VERSION "1.11.2"

NS_ :

BS_:

BU_: TCU BRK ESP MCU RDD GP TMS GW KPD1 RDE FNR ECU KPD2 ATSGO ACU IMU1 IMU2 IMU3 IMU4 IMU5 AGW PMI HDOQS EGOQS OBC EEC CBSW EJRH EJLH EPDLT EPDL2 EPDLR EPDLA TRBDZ ECU1 CLST LC510 EGDL JS SMB KPAC ACCU Audio TGU RDRR RDLH RDRH AVM CHMSL CTC SMK EVC MCU2 PHM MC3D AMBLMP RCTGU RDU PT3D XCU can1 can2

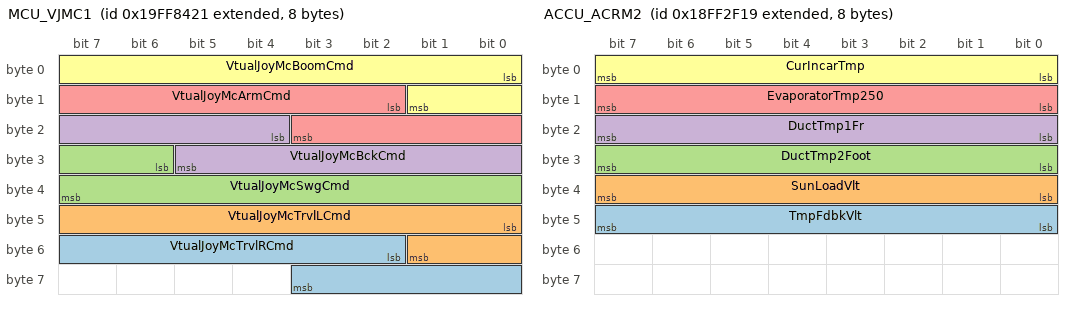
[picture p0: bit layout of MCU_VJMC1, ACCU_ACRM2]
BO_ 2583659553 MCU_VJMC1: 8 MCU
 SG_ VtualJoyMcTrvlRCmd : 50|10@1- (2,-1000) [-1000|3092] "" Vector__XXX
 SG_ VtualJoyMcTrvlLCmd : 40|10@1- (2,-1000) [-1000|3092] "" Vector__XXX
 SG_ VtualJoyMcSwgCmd : 30|10@1- (2,-1000) [-1000|3092] "" Vector__XXX
 SG_ VtualJoyMcBckCmd : 20|10@1- (2,-1000) [-1000|3092] "" Vector__XXX
 SG_ VtualJoyMcArmCmd : 10|10@1- (2,-1000) [-1000|3092] "" Vector__XXX
 SG_ VtualJoyMcBoomCmd : 0|10@1- (2,-1000) [-1000|3092] "" Vector__XXX

BO_ 2583660065 MCU_ESMMC: 250 MCU
 SG_ EstopTpr : 11|2@1+ (1,0) [0|3] "" Vector__XXX
 SG_ FuncFault : 8|3@1+ (1,0) [0|7] "" Vector__XXX
 SG_ GrdAstOptimizedCtrlMdSt : 6|2@1+ (1,0) [0|3] "" Vector__XXX
 SG_ InterlckSt : 3|3@1+ (1,0) [0|7] "" Vector__XXX
 SG_ AutoSt : 0|3@1+ (1,0) [0|7] "" Vector__XXX

BO_ 2583658336 MCU2_WCPD: 76 MCU2
 SG_ WghBckZeroWeight : 576|32@1+ (0.001,-1000000) [0|4294967295] "kg" Vector__XXX
 SG_ WghBckWeight : 544|32@1+ (0.001,-1000000) [0|4294967295] "kg" Vector__XXX
 SG_ WghFrLinkPrmt7 : 512|32@1+ (0.001,-1000000) [0|4294967295] "" Vector__XXX
 SG_ WghFrLinkPrmt6 : 480|32@1+ (0.001,-1000000) [0|4294967295] "" Vector__XXX
 SG_ WghFrLinkPrmt5 : 448|32@1+ (0.001,-1000000) [0|4294967295] "" Vector__XXX
 SG_ WghFrLinkPrmt4 : 416|32@1+ (0.001,-1000000) [0|4294967295] "" Vector__XXX
 SG_ WghFrLinkPrmt3 : 384|32@1+ (0.001,-1000000) [0|4294967295] "" Vector__XXX
 SG_ WghFrLinkPrmt2 : 352|32@1+ (0.001,-1000000) [0|4294967295] "" Vector__XXX
 SG_ WghFrLinkPrmt1 : 320|32@1+ (0.001,-1000000) [0|4294967295] "" Vector__XXX
 SG_ ArmCylStribeckFrcCoefc : 288|32@1+ (0.001,-1000000) [0|4294967295] "" Vector__XXX
 SG_ ArmCylViscousFrcCoefc : 256|32@1+ (0.001,-1000000) [0|4294967295] "" Vector__XXX
 SG_ ArmCylPrsClmbFrcCoefc : 224|32@1+ (0.001,-1000000) [0|4294967295] "" Vector__XXX
 SG_ ArmCylClmbFrcCoefc : 192|32@1+ (0.001,-1000000) [0|4294967295] "" Vector__XXX
 SG_ ArmCylPrsDrpFrcCoefc : 160|32@1+ (0.001,-1000000) [0|4294967295] "" Vector__XXX
 SG_ BoomCylStribeckFrcCoefc : 128|32@1+ (0.001,-1000000) [0|4294967295] "" Vector__XXX
 SG_ BoomCylViscousFrcCoefc : 96|32@1+ (0.001,-1000000) [0|4294967295] "" Vector__XXX
 SG_ BoomCylPrsClmbFrcCoefc : 64|32@1+ (0.001,-1000000) [0|4294967295] "" Vector__XXX
 SG_ BoomCylClmbFrcCoefc : 32|32@1+ (0.001,-1000000) [0|4294967295] "" Vector__XXX
 SG_ BoomCylPrsDrpFrcCoefc : 0|32@1+ (0.001,-1000000) [0|4294967295] "" Vector__XXX

BO_ 2583658160 MC3D_WCCV2: 250 MC3D
 SG_ TgBckCylVelocityUpLm : 16|8@1+ (0.1,0) [0|20] "mmps" Vector__XXX
 SG_ TgBckCylVelocityLwLm : 8|8@1+ (0.1,0) [0|20] "mmps" Vector__XXX
 SG_ CurBckCylVelocity : 0|8@1+ (0.1,0) [0|20] "mmps" Vector__XXX

BO_ 2566908592 MC3D_MWIG: 250 MC3D
 SG_ TiltRttArg : 62|2@1+ (1,0) [0|3] "" Vector__XXX
 SG_ GnssSt : 58|4@1+ (1,0) [0|15] "" Vector__XXX
 SG_ VhcStFineSwgTprDsb : 56|2@1+ (1,0) [0|3] "" Vector__XXX
 SG_ IndSymbolMcTprRlsSt : 54|2@1+ (1,0) [0|3] "" Vector__XXX
 SG_ EfenceTgSetSideWallR : 52|2@1- (1,-32000) [-32000|32255] "mm" Vector__XXX
 SG_ EfenceWarnSideWallR : 50|2@1- (1,-32000) [-32000|32255] "mm" Vector__XXX
 SG_ EfenceWarnSideWallL : 48|2@1+ (1,0) [0|3] "" Vector__XXX
 SG_ AssitSwgRh : 46|2@1+ (1,0) [0|3] "" Vector__XXX
 SG_ AssitSwgLh : 44|2@1+ (1,0) [0|3] "" Vector__XXX
 SG_ AssitBck : 42|2@1+ (1,0) [0|3] "" Vector__XXX
 SG_ AssitGrd : 40|2@1+ (1,0) [0|3] "" Vector__XXX
 SG_ SafeWrkSideFar : 36|2@1+ (1,0) [0|3] "" Vector__XXX
 SG_ SafeWrkSideMid : 34|2@1+ (1,0) [0|3] "" Vector__XXX
 SG_ SafeWrkSideNear : 32|2@1+ (1,0) [0|3] "" Vector__XXX
 SG_ SafeWrkFrFar : 28|2@1+ (1,0) [0|3] "" Vector__XXX
 SG_ SafeWrkFrMid : 26|2@1+ (1,0) [0|3] "" Vector__XXX
 SG_ SafeWrkFrNear : 24|2@1+ (1,0) [0|3] "" Vector__XXX
 SG_ FrMvGuidArmOut : 22|2@1+ (1,0) [0|3] "" Vector__XXX
 SG_ FrMvGuidArmIn : 20|2@1+ (1,0) [0|3] "" Vector__XXX
 SG_ FrMvGuidBoomDn : 18|2@1+ (1,0) [0|3] "" Vector__XXX
 SG_ FrMvGuidBoomUp : 16|2@1+ (1,0) [0|3] "" Vector__XXX
 SG_ EfenceTrkWrn : 14|2@1+ (1,0) [0|3] "" Vector__XXX
 SG_ EfenceDzWrn : 12|2@1+ (1,0) [0|3] "" Vector__XXX
 SG_ EfenceCabWrn : 10|2@1+ (1,0) [0|3] "" Vector__XXX
 SG_ EfenceFSwgRhWrn : 8|2@1+ (1,0) [0|3] "" Vector__XXX
 SG_ EfenceFSwgLhWrn : 6|2@1+ (1,0) [0|3] "" Vector__XXX
 SG_ EfenceCeilWrn : 4|2@1+ (1,0) [0|3] "" Vector__XXX
 SG_ EfenceFloorWrn : 2|2@1+ (1,0) [0|3] "" Vector__XXX
 SG_ EfenceWallWrn : 0|2@1+ (1,0) [0|3] "" Vector__XXX

BO_ 2566909872 MC3D_LADG: 250 MC3D
 SG_ Reach : 48|16@1- (1,-32000) [-32000|32255] "mm" Vector__XXX
 SG_ Hight : 32|16@1- (1,-32000) [-32000|32255] "mm" Vector__XXX
 SG_ RatedLoad : 16|16@1+ (2,0) [0|128510] "kg" Vector__XXX
 SG_ ActLoad : 0|16@1+ (2,0) [0|128510] "kg" Vector__XXX

BO_ 2566913200 MC3D_MCWHG3: 250 MC3D

BO_ 2566913456 MC3D_HSDI: 250 MC3D
 SG_ RandomVal : 0|16@1+ (1,0) [0|65535] "" Vector__XXX

BO_ 2583659184 MC3D_WCJA2: 250 MC3D
 SG_ TgBckJointAngEndPos : 16|8@1+ (1,-125) [-125|125] "deg" Vector__XXX
 SG_ TgBckJointAngStartPos : 8|8@1+ (1,-125) [-125|125] "deg" Vector__XXX
 SG_ CurBckJointAng : 0|8@1+ (1,-125) [-125|125] "deg" Vector__XXX

BO_ 2583659440 MC3D_ALAIG: 250 MC3D
 SG_ SafeWrkIndSwgR : 58|2@1+ (1,0) [0|3] "" Vector__XXX
 SG_ SafeWrkIndSwgL : 56|2@1+ (1,0) [0|3] "" Vector__XXX
 SG_ SafeWrkInd8Far : 54|2@1+ (1,0) [0|3] "" Vector__XXX
 SG_ SafeWrkInd8Mid : 52|2@1+ (1,0) [0|3] "" Vector__XXX
 SG_ SafeWrkInd8Near : 50|2@1+ (1,0) [0|3] "" Vector__XXX
 SG_ SafeWrkInd7Far : 48|2@1+ (1,0) [0|3] "" Vector__XXX
 SG_ SafeWrkInd7Mid : 46|2@1+ (1,0) [0|3] "" Vector__XXX
 SG_ SafeWrkInd7Near : 44|2@1+ (1,0) [0|3] "" Vector__XXX
 SG_ SafeWrkInd6Far : 42|2@1+ (1,0) [0|3] "" Vector__XXX
 SG_ SafeWrkInd6Mid : 40|2@1+ (1,0) [0|3] "" Vector__XXX
 SG_ SafeWrkInd6Near : 38|2@1+ (1,0) [0|3] "" Vector__XXX
 SG_ SafeWrkInd5Far : 36|2@1+ (1,0) [0|3] "" Vector__XXX
 SG_ SafeWrkInd5Mid : 34|2@1+ (1,0) [0|3] "" Vector__XXX
 SG_ SafeWrkInd5Near : 32|2@1+ (1,0) [0|3] "" Vector__XXX
 SG_ SafeWrkInd4Far : 30|2@1+ (1,0) [0|3] "" Vector__XXX
 SG_ SafeWrkInd4Mid : 28|2@1+ (1,0) [0|3] "" Vector__XXX
 SG_ SafeWrkInd4Near : 26|2@1+ (1,0) [0|3] "" Vector__XXX
 SG_ SafeWrkInd3Far : 24|2@1+ (1,0) [0|3] "" Vector__XXX
 SG_ SafeWrkInd3Mid : 22|2@1+ (1,0) [0|3] "" Vector__XXX
 SG_ SafeWrkInd3Near : 20|2@1+ (1,0) [0|3] "" Vector__XXX
 SG_ SafeWrkInd2Far : 18|2@1+ (1,0) [0|3] "" Vector__XXX
 SG_ SafeWrkInd2Mid : 16|2@1+ (1,0) [0|3] "" Vector__XXX
 SG_ SafeWrkInd2Near : 14|2@1+ (1,0) [0|3] "" Vector__XXX
 SG_ SafeWrkInd1Far : 12|2@1+ (1,0) [0|3] "" Vector__XXX
 SG_ SafeWrkInd1Mid : 10|2@1+ (1,0) [0|3] "" Vector__XXX
 SG_ SafeWrkInd1Near : 8|2@1+ (1,0) [0|3] "" Vector__XXX
 SG_ ReliefPressureLm : 3|2@1+ (1,0) [0|3] "" Vector__XXX
 SG_ ArmReachInd : 1|2@1+ (1,0) [0|3] "" Vector__XXX
 SG_ AdvLiftAssReady : 0|1@1+ (1,0) [0|1] "" Vector__XXX

BO_ 2583659696 MC3D_VJMC1: 10 MC3D
 SG_ VtualJoyMcTrvlRCmd : 50|10@1- (2,-1000) [-1000|3092] "" Vector__XXX
 SG_ VtualJoyMcTrvlLCmd : 40|10@1- (2,-1000) [-1000|3092] "" Vector__XXX
 SG_ VtualJoyMcSwgCmd : 30|10@1- (2,-1000) [-1000|3092] "" Vector__XXX
 SG_ VtualJoyMcBckCmd : 20|10@1- (2,-1000) [-1000|3092] "" Vector__XXX
 SG_ VtualJoyMcArmCmd : 10|10@1- (2,-1000) [-1000|3092] "" Vector__XXX
 SG_ VtualJoyMcBoomCmd : 0|10@1- (2,-1000) [-1000|3092] "" Vector__XXX

BO_ 2583659952 MC3D_VJMC2: 250 MC3D
 SG_ VtualJoyMcTrAux2Cmd : 50|10@1- (2,-1000) [-1000|3092] "" Vector__XXX
 SG_ VtualJoyMcTrAux1Cmd : 40|10@1- (2,-1000) [-1000|3092] "" Vector__XXX
 SG_ VtualJoyMcTrRttCmd : 30|10@1- (2,-1000) [-1000|3092] "" Vector__XXX
 SG_ VtualJoyMcTrTiltCmd : 20|10@1- (2,-1000) [-1000|3092] "" Vector__XXX
 SG_ VtualJoyMcOptCmd : 10|10@1- (2,-1000) [-1000|3092] "" Vector__XXX
 SG_ VtualJoyMcArtiCmd : 0|10@1- (2,-1000) [-1000|3092] "" Vector__XXX

BO_ 2583660464 MC3D_MCRES: 250 MC3D
 SG_ SelBckNo : 16|8@1+ (1,0) [0|255] "" Vector__XXX
 SG_ SelMdHeartbeat : 12|3@1+ (1,0) [0|7] "" Vector__XXX
 SG_ ArmingAcptReq : 10|2@1+ (1,0) [0|3] "" Vector__XXX
 SG_ McActCmd : 8|2@1+ (1,0) [0|3] "" Vector__XXX
 SG_ GrdAstOptmCtrlMdSt : 6|2@1+ (1,0) [0|3] "" Vector__XXX
 SG_ McItlReq : 3|3@1+ (1,0) [0|7] "" Vector__XXX
 SG_ McReqMd : 0|3@1+ (1,0) [0|7] "" Vector__XXX

BO_ 2566911153 AMBLMP_ALSD: 250 AMBLMP
 SG_ AmbLmpColorMd : 33|1@1+ (1,0) [0|1] "" Vector__XXX
 SG_ AmbLmpSt : 32|1@1+ (1,0) [0|1] "" Vector__XXX
 SG_ AmbLmpBrightness : 24|8@1+ (1,0) [0|250] "percent" Vector__XXX
 SG_ AmbLmpColor : 0|24@1+ (1,0) [0|16777215] "count" Vector__XXX

BO_ 2566911308 RCTGU_TGUVCC: 8 RCTGU
 SG_ SelMdHeartbeat : 48|3@1+ (1,0) [0|7] "" Vector__XXX
 SG_ ArmingAcptReq : 45|2@1+ (1,0) [0|3] "" Vector__XXX
 SG_ RmWrkMdSelSig : 40|3@1+ (1,0) [0|7] "" Vector__XXX
 SG_ RmTrvlSpdSelSig : 38|2@1+ (1,0) [0|3] "" Vector__XXX
 SG_ RmPwrMdSelSig2 : 36|2@1+ (1,0) [0|3] "" Vector__XXX
 SG_ RmCtrlActSig : 34|2@1+ (1,0) [0|3] "" Vector__XXX
 SG_ RmItlReq : 32|2@1+ (1,0) [0|3] "" Vector__XXX
 SG_ RmRpmSig : 24|8@1+ (0.004,0) [0|100] "percent" Vector__XXX
 SG_ RmCtrlReq : 22|2@1+ (1,0) [0|3] "" Vector__XXX
 SG_ RmEgStopSt : 20|2@1+ (1,0) [0|3] "" Vector__XXX
 SG_ RmPwrMdSelSig1 : 18|2@1+ (1,0) [0|3] "" Vector__XXX
 SG_ RmEmgStopOprSig : 16|2@1+ (1,0) [0|3] "" Vector__XXX
 SG_ RmFrcRgnOprSig : 14|2@1+ (1,0) [0|3] "" Vector__XXX
 SG_ RmHornOprSig : 12|2@1+ (1,0) [0|3] "" Vector__XXX
 SG_ RmPltCutoffRlsSvOprSig : 10|2@1+ (1,0) [0|3] "" Vector__XXX
 SG_ RmFineSwgSvOprSig : 8|2@1+ (1,0) [0|3] "" Vector__XXX
 SG_ RmCbLmpRly2OprSig : 6|2@1+ (1,0) [0|3] "" Vector__XXX
 SG_ RmCbLmpRly1OprSig : 4|2@1+ (1,0) [0|3] "" Vector__XXX
 SG_ RmBodyLmpRlyOprSig : 2|2@1+ (1,0) [0|3] "" Vector__XXX
 SG_ RmWrkLmpRlyOprSig : 0|2@1+ (1,0) [0|3] "" Vector__XXX

BO_ 2566860569 ACCU_ACRM2: 8 ACCU
 SG_ TmpFdbkVlt : 40|8@1+ (0.02044,0) [0|5.11] "" Vector__XXX
 SG_ SunLoadVlt : 32|8@1+ (0.02044,0) [0|5.11] "" Vector__XXX
 SG_ DuctTmp2Foot : 24|8@1+ (1,-40) [-40|210] "" Vector__XXX
 SG_ DuctTmp1Fr : 16|8@1+ (1,-40) [-40|210] "" Vector__XXX
 SG_ EvaporatorTmp250 : 8|8@1+ (1,-40) [-40|210] "" Vector__XXX
 SG_ CurIncarTmp : 0|8@1+ (1,-40) [-40|210] "" Vector__XXX

BO_ 2565844776 GP_GPSMPHM: 1785 GP

BO_ 2566867632 MC3D_SIG4: 8 MC3D
 SG_ WarnPopLimitangexcess : 62|2@1+ (1,0) [0|3] "" Vector__XXX
 SG_ WarnPopMgMcSsErr : 58|4@1+ (1,0) [0|15] "" Vector__XXX
 SG_ McTemporaryRlsPop : 56|2@1+ (1,0) [0|3] "" Vector__XXX
 SG_ VhcStStickStr : 54|2@1+ (1,0) [0|3] "" Vector__XXX
 SG_ VhcStFineSwg : 52|2@1+ (1,0) [0|3] "" Vector__XXX
 SG_ ActTrvlSpdforCrwl : 50|2@1+ (1,0) [0|3] "" Vector__XXX
 SG_ ActTrvlStforCrwl : 48|2@1+ (1,0) [0|3] "" Vector__XXX
 SG_ VhcStParallelLift : 46|2@1+ (1,0) [0|3] "" Vector__XXX
 SG_ VhcStFrSspnAuto : 44|2@1+ (1,0) [0|3] "" Vector__XXX
 SG_ RmCrakingSt : 40|4@1+ (1,0) [0|15] "" Vector__XXX
 SG_ IndTrmsColdStart : 39|1@1+ (1,0) [0|1] "" Vector__XXX
 SG_ VhcStElevatingCabin : 37|2@1+ (1,0) [0|3] "" Vector__XXX
 SG_ WarnPopStickStr : 36|1@1+ (1,0) [0|1] "" Vector__XXX
 SG_ PopCmdThwLvrErr : 35|1@1+ (1,0) [0|1] "" Vector__XXX
 SG_ HpApMd : 33|2@1+ (1,0) [0|3] "" Vector__XXX
 SG_ GrLmt : 32|1@1+ (1,0) [0|1] "" Vector__XXX
 SG_ BodyAng : 24|8@1+ (1,-125) [-125|125] "deg" Vector__XXX
 SG_ WghIndSt : 22|2@1+ (1,0) [0|3] "" Vector__XXX
 SG_ BrkHold : 21|1@1+ (1,0) [0|1] "" Vector__XXX
 SG_ RtrdSt : 18|3@1+ (1,0) [0|7] "" Vector__XXX
 SG_ PilotCutOffSt : 16|2@1+ (1,0) [0|3] "" Vector__XXX
 SG_ BodySt : 14|2@1+ (1,0) [0|3] "" Vector__XXX
 SG_ VhcStGndSaw : 13|1@1+ (1,0) [0|1] "" Vector__XXX
 SG_ PopCmdJoyLvrNtrlErr : 12|1@1+ (1,0) [0|1] "" Vector__XXX
 SG_ VhcStIntAxleLck : 11|1@1+ (1,0) [0|1] "" Vector__XXX
 SG_ TrlHhFlowMd : 8|3@1+ (1,0) [0|7] "" Vector__XXX
 SG_ ExcAutoBrkAntiFire : 6|2@1+ (1,0) [0|3] "" Vector__XXX
 SG_ TrlIntLckOvrd : 5|1@1+ (1,0) [0|1] "" Vector__XXX
 SG_ TrlCtrlFlow : 3|2@1+ (1,0) [0|3] "" Vector__XXX
 SG_ TrlSelfLv : 1|2@1+ (1,0) [0|3] "" Vector__XXX
 SG_ TrlHhFlow : 0|1@1+ (1,0) [0|1] "" Vector__XXX

BO_ 2583660720 MC3D_XCUTE: 250 MC3D
 SG_ Mc3DGrdTgErrorR : 32|16@1- (1,-32000) [-32000|32255] "" Vector__XXX
 SG_ Mc3DGrdTgErrorCnt : 16|16@1- (1,-32000) [-32000|32255] "" Vector__XXX
 SG_ Mc3DGrdTgErrorL : 0|16@1- (1,-32000) [-32000|32255] "" Vector__XXX

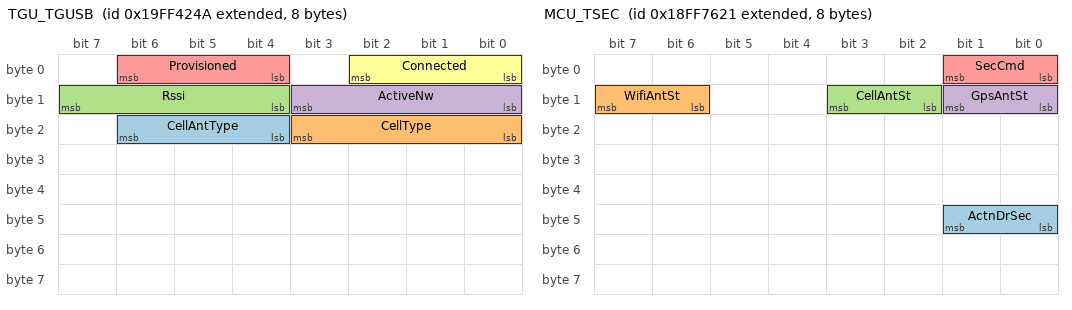
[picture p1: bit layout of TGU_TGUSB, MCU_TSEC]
BO_ 2583642698 TGU_TGUSB: 8 TGU
 SG_ CellAntType : 20|3@1+ (1,0) [0|3] "" Vector__XXX
 SG_ CellType : 16|4@1+ (1,0) [0|15] "" Vector__XXX
 SG_ Rssi : 12|4@1+ (1,0) [0|15] "" Vector__XXX
 SG_ ActiveNw : 8|4@1+ (1,0) [0|15] "" Vector__XXX
 SG_ Provisioned : 4|3@1+ (1,0) [0|7] "" Vector__XXX
 SG_ Connected : 0|3@1+ (1,0) [0|7] "" Vector__XXX

BO_ 2565406538 TGU_TUACK: 8 TGU
 SG_ Ack : 0|2@1+ (1,0) [0|3] "" Vector__XXX

BO_ 2566878753 MCU_TSEC: 8 MCU
 SG_ ActnDrSec : 40|2@1+ (1,0) [0|3] "" Vector__XXX
 SG_ WifiAntSt : 14|2@1+ (1,0) [0|3] "" Vector__XXX
 SG_ CellAntSt : 10|2@1+ (1,0) [0|3] "" Vector__XXX
 SG_ GpsAntSt : 8|2@1+ (1,0) [0|3] "" Vector__XXX
 SG_ SecCmd : 0|2@1+ (1,0) [0|3] "" Vector__XXX

BO_ 2583643176 GP_KLLI: 13 GP
 SG_ PinCd : 48|56@1+ (1,0) [0|7.20575940379279E+16] "ASCII" Vector__XXX
 SG_ DigitalKey : 0|48@1+ (1,0) [0|281474976710655] "binary" Vector__XXX

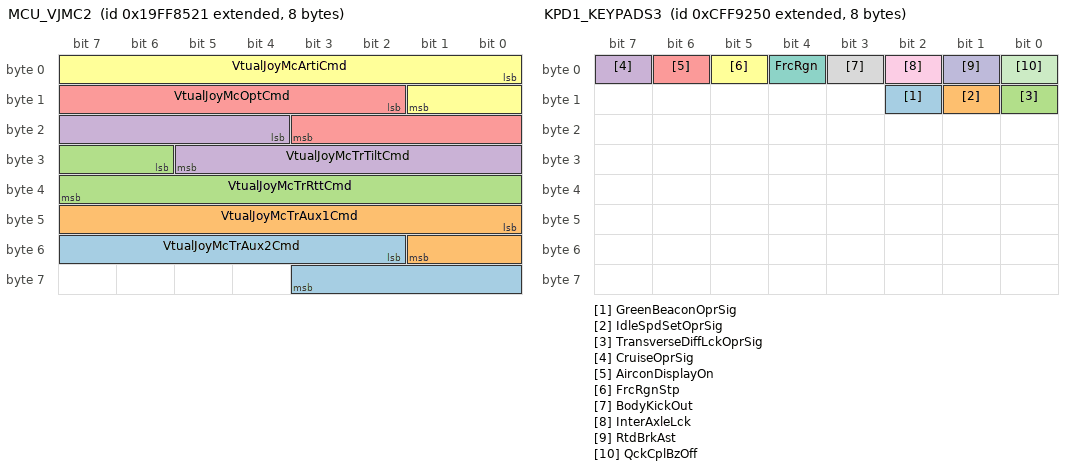
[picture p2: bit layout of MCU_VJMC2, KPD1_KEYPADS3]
BO_ 2583659809 MCU_VJMC2: 8 MCU
 SG_ VtualJoyMcTrAux2Cmd : 50|10@1- (2,-1000) [-1000|3092] "" Vector__XXX
 SG_ VtualJoyMcTrAux1Cmd : 40|10@1- (2,-1000) [-1000|3092] "" Vector__XXX
 SG_ VtualJoyMcTrRttCmd : 30|10@1- (2,-1000) [-1000|3092] "" Vector__XXX
 SG_ VtualJoyMcTrTiltCmd : 20|10@1- (2,-1000) [-1000|3092] "" Vector__XXX
 SG_ VtualJoyMcOptCmd : 10|10@1- (2,-1000) [-1000|3092] "" Vector__XXX
 SG_ VtualJoyMcArtiCmd : 0|10@1- (2,-1000) [-1000|3092] "" Vector__XXX

BO_ 2583643432 GP_DKTL: 1785 GP
 SG_ DkeyListInfo : 0|14280@1+ (1,0) [0|0] "ASCII-VN" Vector__XXX

BO_ 2566868513 MCU_SIG5: 8 MCU
 SG_ VhcStSybEmgStrCheck : 62|2@1+ (1,0) [0|3] "" Vector__XXX
 SG_ CmdBodyLiftLmt : 60|2@1+ (1,0) [0|3] "" Vector__XXX
 SG_ VhcStSybAutoHold : 56|4@1+ (1,0) [0|15] "" Vector__XXX
 SG_ VhcStSybAutoDig : 52|3@1+ (1,0) [0|7] "" Vector__XXX
 SG_ RearRTirePrsLow : 50|2@1+ (1,0) [0|3] "" Vector__XXX
 SG_ RearLTirePrsLow : 48|2@1+ (1,0) [0|3] "" Vector__XXX
 SG_ FrRTirePrsLow : 46|2@1+ (1,0) [0|3] "" Vector__XXX
 SG_ FrLTirePrsLow : 44|2@1+ (1,0) [0|3] "" Vector__XXX
 SG_ HhFlowAuxSt : 40|3@1+ (1,0) [0|7] "" Vector__XXX
 SG_ IndSybWirelessChgSt : 38|2@1+ (1,0) [0|3] "" Vector__XXX
 SG_ VhcStSybIdleSpdSet : 36|2@1+ (1,0) [0|3] "" Vector__XXX
 SG_ GrStMismatchSig : 34|2@1+ (1,0) [0|3] "" Vector__XXX
 SG_ VhcStSybBrkChg : 32|2@1+ (1,0) [0|3] "" Vector__XXX
 SG_ CmdFineSwg : 30|2@1+ (1,0) [0|3] "" Vector__XXX
 SG_ CmdOptLinePrsRf : 28|2@1+ (1,0) [0|3] "" Vector__XXX
 SG_ AdtUserWghCalSt : 26|2@1+ (1,0) [0|3] "" Vector__XXX
 SG_ VhcStateSybSpdLimitCtrl : 24|2@1+ (1,0) [0|3] "" Vector__XXX
 SG_ TmShftMdSybforLd : 21|3@1+ (1,0) [0|7] "" Vector__XXX
 SG_ BckShakeStSig : 18|3@1+ (1,0) [0|7] "" Vector__XXX
 SG_ CmdForceRegenFail : 16|2@1+ (1,0) [0|3] "" Vector__XXX
 SG_ DumpBodyOprSig : 12|2@1+ (1,0) [0|3] "" Vector__XXX
 SG_ WghStRefreshSig : 10|2@1+ (1,0) [0|3] "" Vector__XXX
 SG_ CmdStarterFail : 8|2@1+ (1,0) [0|3] "" Vector__XXX
 SG_ IdleSpdSetCond : 6|2@1+ (1,0) [0|3] "" Vector__XXX
 SG_ CmdRrSspn_SelfLv : 4|2@1+ (1,0) [0|3] "" Vector__XXX
 SG_ VhcStSybRrSspnAuto : 2|2@1+ (1,0) [0|3] "" Vector__XXX
 SG_ CmdFrSspn : 0|2@1+ (1,0) [0|3] "" Vector__XXX

BO_ 2365559376 KPD1_KEYPADS3: 8 KPD1
 SG_ GreenBeaconOprSig : 10|1@1+ (1,0) [0|1] "" Vector__XXX
 SG_ IdleSpdSetOprSig : 9|1@1+ (1,0) [0|1] "" Vector__XXX
 SG_ TransverseDiffLckOprSig : 8|1@1+ (1,0) [0|1] "" Vector__XXX
 SG_ CruiseOprSig : 7|1@1+ (1,0) [0|1] "" Vector__XXX
 SG_ AirconDisplayOn : 6|1@1+ (1,0) [0|3] "" Vector__XXX
 SG_ FrcRgnStp : 5|1@1+ (1,0) [0|3] "" Vector__XXX
 SG_ FrcRgn : 4|1@1+ (1,0) [0|3] "" Vector__XXX
 SG_ BodyKickOut : 3|1@1+ (1,0) [0|1] "" Vector__XXX
 SG_ InterAxleLck : 2|1@1+ (1,0) [0|1] "" Vector__XXX
 SG_ RtdBrkAst : 1|1@1+ (1,0) [0|1] "" Vector__XXX
 SG_ QckCplBzOff : 0|1@1+ (1,0) [0|1] "" Vector__XXX

BO_ 2365559585 MCU_KEYPADI5: 8 MCU
 SG_ GreenBeaconLInd : 58|2@1+ (1,0) [0|3] "" Vector__XXX
 SG_ GreenBeaconCtrInd : 56|2@1+ (1,0) [0|3] "" Vector__XXX
 SG_ GreenBeaconRInd : 54|2@1+ (1,0) [0|3] "" Vector__XXX
 SG_ IdleSpdSetLInd : 52|2@1+ (1,0) [0|3] "" Vector__XXX
 SG_ IdleSpdSetCtrInd : 50|2@1+ (1,0) [0|3] "" Vector__XXX
 SG_ IdleSpdSetRInd : 48|2@1+ (1,0) [0|3] "" Vector__XXX
 SG_ TransverseDiffLckLOprSig : 46|2@1+ (1,0) [0|3] "" Vector__XXX
 SG_ TransverseDiffLckCtrOprSig : 44|2@1+ (1,0) [0|3] "" Vector__XXX
 SG_ TransverseDiffLckROprSig : 42|2@1+ (1,0) [0|3] "" Vector__XXX
 SG_ CruiseLInd : 40|2@1+ (1,0) [0|3] "" Vector__XXX
 SG_ CruiseCtrInd : 38|2@1+ (1,0) [0|3] "" Vector__XXX
 SG_ CruiseRInd : 36|2@1+ (1,0) [0|3] "" Vector__XXX
 SG_ RtdBrkAstLInd : 34|2@1+ (1,0) [0|3] "" Vector__XXX
 SG_ RtdBrkAstCtrInd : 32|2@1+ (1,0) [0|3] "" Vector__XXX
 SG_ RtdBrkAstRInd : 30|2@1+ (1,0) [0|3] "" Vector__XXX
 SG_ QckCplBzOffLInd : 28|2@1+ (1,0) [0|3] "" Vector__XXX
 SG_ QckCplBzOffCtrInd : 26|2@1+ (1,0) [0|3] "" Vector__XXX
 SG_ QckCplBzOffRInd : 24|2@1+ (1,0) [0|3] "" Vector__XXX
 SG_ FrcRgnStpLInd : 22|2@1+ (1,0) [0|3] "" Vector__XXX
 SG_ FrcRgnStpCtrInd : 20|2@1+ (1,0) [0|3] "" Vector__XXX
 SG_ FrcRgnStpRInd : 18|2@1+ (1,0) [0|3] "" Vector__XXX
 SG_ FrcRgnLInd : 16|2@1+ (1,0) [0|3] "" Vector__XXX
 SG_ FrcRgnCtrInd : 14|2@1+ (1,0) [0|3] "" Vector__XXX
 SG_ FrcRgnRInd : 12|2@1+ (1,0) [0|3] "" Vector__XXX
 SG_ BodyKickOutLInd : 10|2@1+ (1,0) [0|3] "" Vector__XXX
 SG_ BodyKickOutCtrInd : 8|2@1+ (1,0) [0|3] "" Vector__XXX
 SG_ BodyKickOutRInd : 6|2@1+ (1,0) [0|3] "" Vector__XXX
 SG_ InterAxleLckLInd : 4|2@1+ (1,0) [0|3] "" Vector__XXX
 SG_ InterAxleLckCtrInd : 2|2@1+ (1,0) [0|3] "" Vector__XXX
 SG_ InterAxleLckRInd : 0|2@1+ (1,0) [0|3] "" Vector__XXX

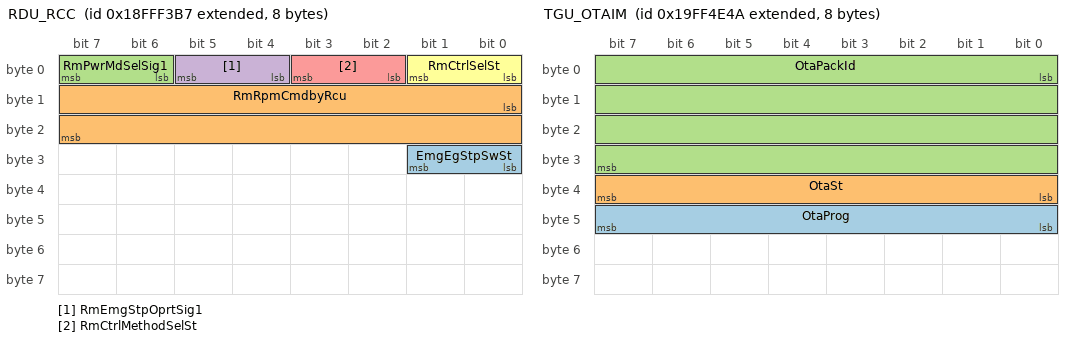
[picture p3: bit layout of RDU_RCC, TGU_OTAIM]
BO_ 2566910903 RDU_RCC: 8 RDU
 SG_ EmgEgStpSwSt : 24|2@1+ (1,0) [0|3] "" Vector__XXX
 SG_ RmRpmCmdbyRcu : 8|16@1+ (0.001,0) [0|64.255] "V" Vector__XXX
 SG_ RmPwrMdSelSig1 : 6|2@1+ (1,0) [0|3] "" Vector__XXX
 SG_ RmEmgStpOprtSig1 : 4|2@1+ (1,0) [0|3] "" Vector__XXX
 SG_ RmCtrlMethodSelSt : 2|2@1+ (1,0) [0|3] "" Vector__XXX
 SG_ RmCtrlSelSt : 0|2@1+ (1,0) [0|3] "" Vector__XXX

BO_ 2566891510 PT3D_TCSMVCU: 8 PT3D
 SG_ Mc3DOprtSt : 24|8@1+ (1,0) [0|255] "" Vector__XXX
 SG_ Mc3DSysReadySt : 16|8@1+ (1,0) [0|255] "" Vector__XXX

BO_ 2583645770 TGU_OTAIM: 8 TGU
 SG_ OtaProg : 40|8@1+ (1,0) [0|100] "percent" Vector__XXX
 SG_ OtaSt : 32|8@1+ (1,0) [0|15] "" Vector__XXX
 SG_ OtaPackId : 0|32@1+ (1,0) [0|4294967295] "" Vector__XXX

BO_ 2566859041 MCU_CTM: 8 MCU
 SG_ FnrDirForLv1RrMon : 0|2@1+ (1,0) [0|3] "" Vector__XXX

BO_ 2566858273 MCU_AFCL: 1785 MCU
 SG_ Afc : 0|1@1+ (1,0) [0|1] "ignore" Vector__XXX

BO_ 2566858529 MCU_HFCL: 1785 MCU
 SG_ Hfc : 0|1@1+ (1,0) [0|1] "ignore" Vector__XXX

BO_ 2583646026 TGU_API: 1783 TGU
 SG_ EndPoint : 1200|13064@1+ (1,0) [0|0] "ASCII-VN" Vector__XXX
 SG_ Key : 0|1200@1+ (1,0) [0|0] "ASCII-FN" Vector__XXX

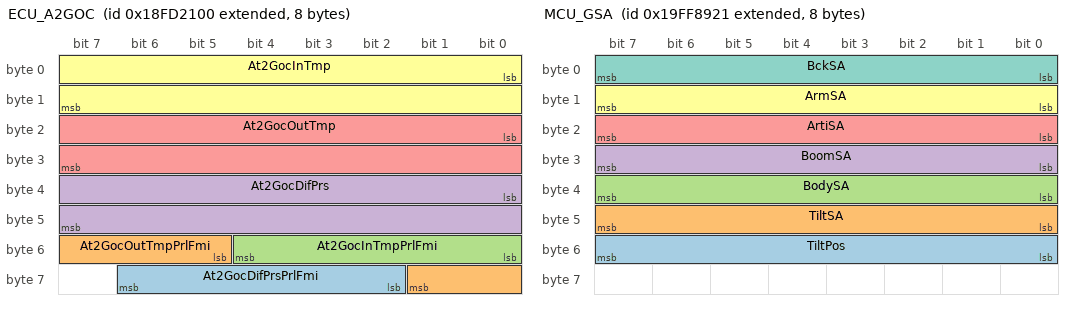
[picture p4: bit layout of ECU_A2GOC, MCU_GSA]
BO_ 2566725888 ECU_A2GOC: 8 ECU
 SG_ At2GocDifPrsPrlFmi : 58|5@1+ (1,0) [0|31] "" Vector__XXX
 SG_ At2GocOutTmpPrlFmi : 53|5@1+ (1,0) [0|31] "" Vector__XXX
 SG_ At2GocInTmpPrlFmi : 48|5@1+ (1,0) [0|31] "" Vector__XXX
 SG_ At2GocDifPrs : 32|16@1+ (0.1,0) [0|6425.5] "kPa" Vector__XXX
 SG_ At2GocOutTmp : 16|16@1+ (0.03125,-273) [-273|1734.96875] "celsius" Vector__XXX
 SG_ At2GocInTmp : 0|16@1+ (0.03125,-273) [-273|1734.96875] "celsius" Vector__XXX

BO_ 2566879050 TGU_TMSGPSI2: 8 TGU
 SG_ Z : 48|16@1+ (1,0) [0|65535] "m" Vector__XXX

BO_ 2566913576 GP_MTSI: 88 GP
 SG_ CompanyName : 504|200@1+ (1,0) [0|1.60693804425899E+60] "ASCII" Vector__XXX
 SG_ TgWghofCurTrk : 488|16@1+ (2,0) [0|128510] "kg" Vector__XXX
 SG_ TrkCntFinalTm : 456|32@1+ (1,0) [0|4211081215] "s" Vector__XXX
 SG_ MaterialLoadSt : 448|1@1+ (1,0) [0|1] "" Vector__XXX
 SG_ TotWghCurTrk : 432|16@1+ (2,0) [0|128510] "kg" Vector__XXX
 SG_ BckCntCurTrk : 416|16@1+ (1,0) [0|65535] "count" Vector__XXX
 SG_ MtrDensity : 400|16@1+ (1,0) [0|64255] "kgpm3" Vector__XXX
 SG_ MtrName : 200|200@1+ (1,0) [0|255] "ASCII" Vector__XXX
 SG_ TrkName : 0|200@1+ (1,0) [0|1.60693804425899E+60] "ASCII" Vector__XXX

BO_ 2566838880 MCU2_SOFT: 1785 MCU2
 SG_ PckVer : 8|14272@1+ (1,0) [0|0] "ASCII" Vector__XXX
 SG_ DtLgh : 0|8@1+ (1,0) [0|255] "" Vector__XXX

BO_ 2633947703 AVM_SOFT: 1785 AVM
 SG_ PckVer : 8|14272@1+ (1,0) [0|0] "ASCII" Vector__XXX
 SG_ DtLgh : 0|8@1+ (1,0) [0|255] "" Vector__XXX

BO_ 2566838959 PHM_SOFT: 1785 PHM
 SG_ PckVer : 8|14272@1+ (1,0) [0|0] "ASCII" Vector__XXX
 SG_ DtLgh : 0|8@1+ (1,0) [0|255] "" Vector__XXX

BO_ 2566838960 MC3D_SOFT: 1785 MC3D
 SG_ PckVer : 8|14272@1+ (1,0) [0|0] "ASCII" Vector__XXX
 SG_ DtLgh : 0|8@1+ (1,0) [0|255] "" Vector__XXX

BO_ 2583660833 MCU_GSA: 8 MCU
 SG_ TiltPos : 48|8@1+ (1,0) [0|255] "" Vector__XXX
 SG_ TiltSA : 40|8@1+ (1,0) [0|255] "" Vector__XXX
 SG_ BodySA : 32|8@1+ (1,0) [0|255] "" Vector__XXX
 SG_ BoomSA : 24|8@1+ (1,0) [0|255] "" Vector__XXX
 SG_ ArtiSA : 16|8@1+ (1,0) [0|255] "" Vector__XXX
 SG_ ArmSA : 8|8@1+ (1,0) [0|255] "" Vector__XXX
 SG_ BckSA : 0|8@1+ (1,0) [0|255] "" Vector__XXX

BO_ 2566885450 TGU_QRCI: 55 TGU
 SG_ PartNo : 312|128@1+ (1,0) [0|3.40282366920938E+38] "ASCII-FN" Vector__XXX
 SG_ SerialNo : 184|128@1+ (1,0) [0|3.40282366920938E+38] "ASCII-FN" Vector__XXX
 SG_ MnftCode : 120|64@1+ (1,0) [0|1.84467440737096E+19] "ASCII-FN" Vector__XXX
 SG_ ComCode : 56|64@1+ (1,0) [0|1.84467440737096E+19] "ASCII-FN" Vector__XXX
 SG_ Year : 48|8@1+ (1,1985) [1985|2235] "year" Vector__XXX
 SG_ Day : 40|8@1+ (0.25,0) [0|62.5] "days" Vector__XXX
 SG_ Month : 32|8@1+ (1,0) [0|250] "month" Vector__XXX
 SG_ SwVer : 0|32@1+ (1,0) [0|4294967295] "ASCII" Vector__XXX

BO_ 2583645258 TGU_RDI: 1785 TGU
 SG_ RmSetDataList : 8|14272@1+ (1,0) [0|0] "ASCII-VN" Vector__XXX
 SG_ GpBtnCtrl : 4|3@1+ (1,0) [0|7] "" Vector__XXX
 SG_ GpPopupReq : 0|4@1+ (1,0) [0|15] "" Vector__XXX

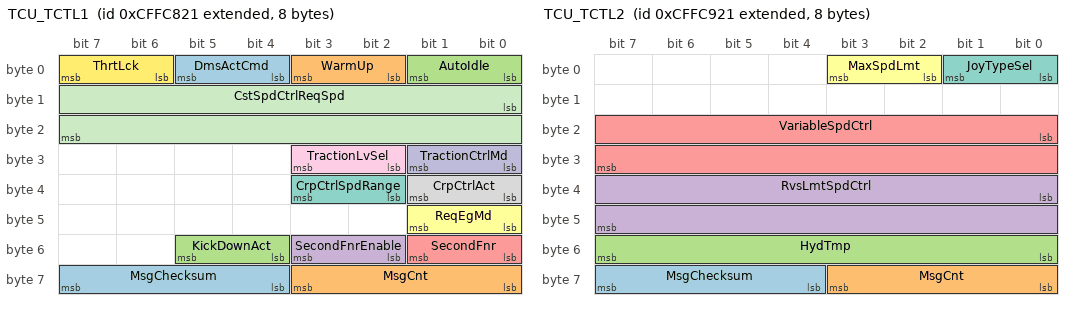
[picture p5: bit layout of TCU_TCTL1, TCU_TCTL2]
BO_ 2365573153 TCU_TCTL1: 8 TCU
 SG_ MsgChecksum : 60|4@1+ (1,0) [0|15] "" Vector__XXX
 SG_ MsgCnt : 56|4@1+ (1,0) [0|15] "" Vector__XXX
 SG_ KickDownAct : 52|2@1+ (1,0) [0|3] "" Vector__XXX
 SG_ SecondFnrEnable : 50|2@1+ (1,0) [0|3] "" Vector__XXX
 SG_ SecondFnr : 48|2@1+ (1,0) [0|3] "" Vector__XXX
 SG_ ReqEgMd : 40|2@1+ (1,0) [0|3] "" Vector__XXX
 SG_ CrpCtrlSpdRange : 34|2@1+ (1,0) [0|3] "" Vector__XXX
 SG_ CrpCtrlAct : 32|2@1+ (1,0) [0|3] "" Vector__XXX
 SG_ TractionLvSel : 26|2@1+ (1,0) [0|3] "" Vector__XXX
 SG_ TractionCtrlMd : 24|2@1+ (1,0) [0|3] "" Vector__XXX
 SG_ CstSpdCtrlReqSpd : 8|16@1+ (0.125,0) [0|8031.875] "rpm" Vector__XXX
 SG_ ThrtLck : 6|2@1+ (1,0) [0|3] "" Vector__XXX
 SG_ DmsActCmd : 4|2@1+ (1,0) [0|3] "" Vector__XXX
 SG_ WarmUp : 2|2@1+ (1,0) [0|3] "" Vector__XXX
 SG_ AutoIdle : 0|2@1+ (1,0) [0|3] "" Vector__XXX

BO_ 2365573409 TCU_TCTL2: 8 TCU
 SG_ MsgChecksum : 60|4@1+ (1,0) [0|15] "" Vector__XXX
 SG_ MsgCnt : 56|4@1+ (1,0) [0|15] "" Vector__XXX
 SG_ HydTmp : 48|8@1+ (1,-30) [0|145] "celsius" Vector__XXX
 SG_ RvsLmtSpdCtrl : 32|16@1+ (0.2,0) [0|50] "kmph" Vector__XXX
 SG_ VariableSpdCtrl : 16|16@1+ (0.2,0) [0|50] "kmph" Vector__XXX
 SG_ MaxSpdLmt : 2|2@1+ (1,0) [0|3] "" Vector__XXX
 SG_ JoyTypeSel : 0|2@1+ (1,0) [0|3] "" Vector__XXX

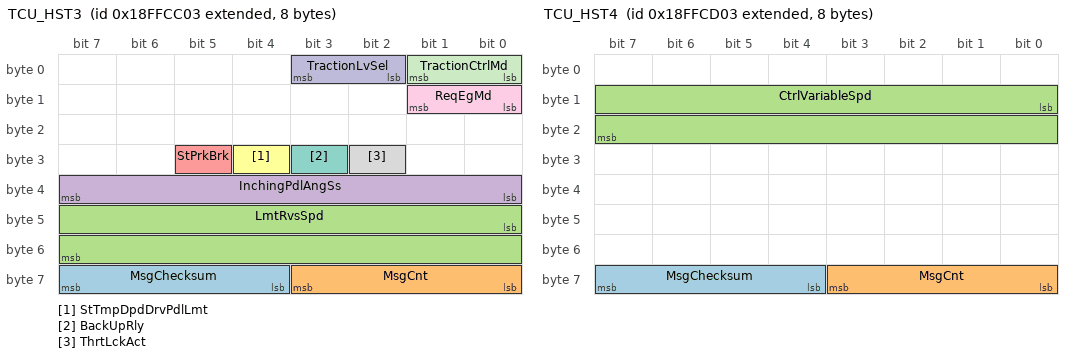
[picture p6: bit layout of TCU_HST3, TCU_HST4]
BO_ 2566900739 TCU_HST3: 8 TCU
 SG_ MsgChecksum : 60|4@1+ (1,0) [0|15] "" Vector__XXX
 SG_ MsgCnt : 56|4@1+ (1,0) [0|15] "" Vector__XXX
 SG_ LmtRvsSpd : 40|16@1+ (0.2,0) [0|50] "kmph" Vector__XXX
 SG_ InchingPdlAngSs : 32|8@1+ (0.025,0) [0|6.25] "V" Vector__XXX
 SG_ StPrkBrk : 29|1@1+ (1,0) [0|1] "" Vector__XXX
 SG_ StTmpDpdDrvPdlLmt : 28|1@1+ (1,0) [0|1] "" Vector__XXX
 SG_ BackUpRly : 27|1@1+ (1,0) [0|1] "" Vector__XXX
 SG_ ThrtLckAct : 26|1@1+ (1,0) [0|1] "" Vector__XXX
 SG_ ReqEgMd : 8|2@1+ (1,0) [0|3] "" Vector__XXX
 SG_ TractionLvSel : 2|2@1+ (1,0) [0|3] "" Vector__XXX
 SG_ TractionCtrlMd : 0|2@1+ (1,0) [0|3] "" Vector__XXX

BO_ 2566900995 TCU_HST4: 8 TCU
 SG_ MsgChecksum : 60|4@1+ (1,0) [0|15] "" Vector__XXX
 SG_ MsgCnt : 56|4@1+ (1,0) [0|15] "" Vector__XXX
 SG_ CtrlVariableSpd : 8|16@1+ (0.2,0) [0|50] "kmph" Vector__XXX

BO_ 2566888963 TCU_TMCI: 8 TCU
 SG_ AutoShiftIcbConfig : 0|2@1+ (1,0) [0|3] "" Vector__XXX

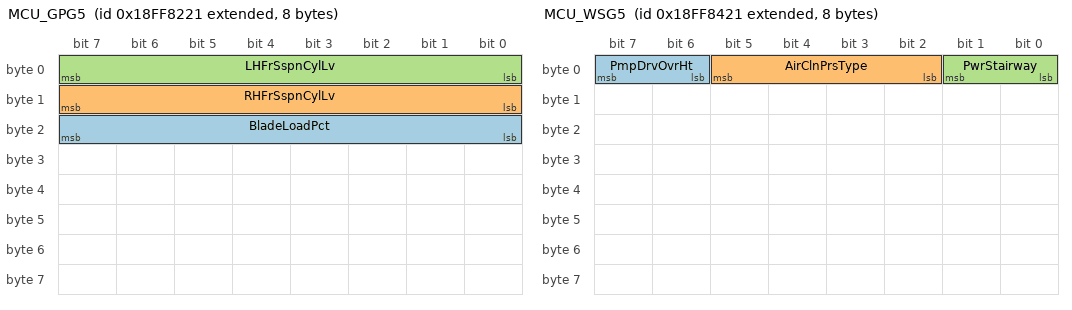
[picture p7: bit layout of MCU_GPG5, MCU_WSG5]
BO_ 2566881825 MCU_GPG5: 8 MCU
 SG_ BladeLoadPct : 16|8@1+ (1,0) [0|250] "percent" Vector__XXX
 SG_ RHFrSspnCylLv : 8|8@1+ (1,-125) [-125|125] "percent" Vector__XXX
 SG_ LHFrSspnCylLv : 0|8@1+ (1,-125) [-125|125] "percent" Vector__XXX

BO_ 2566882081 MCU_WSG4: 8 MCU
 SG_ CoolLvWarneTMSCab : 36|2@1+ (1,0) [0|3] "" Vector__XXX
 SG_ CoolLvWarneTMS22 : 34|2@1+ (1,0) [0|3] "" Vector__XXX
 SG_ CoolLvWarneTMS21 : 32|2@1+ (1,0) [0|3] "" Vector__XXX
 SG_ CoolLvWarneTMS13 : 30|2@1+ (1,0) [0|3] "" Vector__XXX
 SG_ CoolLvWarneTMS12 : 28|2@1+ (1,0) [0|3] "" Vector__XXX
 SG_ CoolLvWarneTMS11 : 26|2@1+ (1,0) [0|3] "" Vector__XXX
 SG_ Ldc2AbnCur : 24|2@1+ (1,0) [0|3] "" Vector__XXX
 SG_ Ldc1AbnCur : 22|2@1+ (1,0) [0|3] "" Vector__XXX
 SG_ Ldc2AbnVlt : 20|2@1+ (1,0) [0|3] "" Vector__XXX
 SG_ Ldc1AbnVlt : 18|2@1+ (1,0) [0|3] "" Vector__XXX
 SG_ Imd : 16|2@1+ (1,0) [0|3] "" Vector__XXX
 SG_ BatSuperCoolWarn : 14|2@1+ (1,0) [0|3] "" Vector__XXX
 SG_ ObcOvrHt : 12|2@1+ (1,0) [0|3] "" Vector__XXX
 SG_ TrvlIvtOvrHt : 10|2@1+ (1,0) [0|3] "" Vector__XXX
 SG_ SwgIvtOvrHt : 8|2@1+ (1,0) [0|3] "" Vector__XXX
 SG_ PmpIvtOvrHt : 6|2@1+ (1,0) [0|3] "" Vector__XXX
 SG_ TrvlMotOvrHt : 4|2@1+ (1,0) [0|3] "" Vector__XXX
 SG_ SwgMotOvrHt : 2|2@1+ (1,0) [0|3] "" Vector__XXX
 SG_ PmpMotOvrHt : 0|2@1+ (1,0) [0|3] "" Vector__XXX

BO_ 2566882337 MCU_WSG5: 8 MCU
 SG_ PmpDrvOvrHt : 6|2@1+ (1,0) [0|3] "" Vector__XXX
 SG_ AirClnPrsType : 2|4@1+ (1,0) [0|15] "" Vector__XXX
 SG_ PwrStairway : 0|2@1+ (1,0) [0|3] "" Vector__XXX

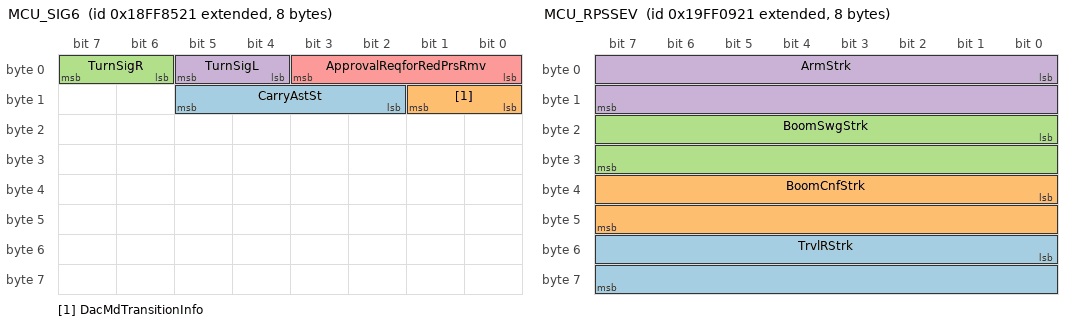
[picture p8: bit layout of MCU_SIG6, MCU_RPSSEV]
BO_ 2566882593 MCU_SIG6: 8 MCU
 SG_ CarryAstSt : 10|4@1+ (1,0) [0|15] "" Vector__XXX
 SG_ DacMdTransitionInfo : 8|2@1+ (1,0) [0|3] "" Vector__XXX
 SG_ TurnSigR : 6|2@1+ (1,0) [0|3] "" Vector__XXX
 SG_ TurnSigL : 4|2@1+ (1,0) [0|3] "" Vector__XXX
 SG_ ApprovalReqforRedPrsRmv : 0|4@1+ (1,0) [0|15] "" Vector__XXX

BO_ 2583628065 MCU_RPSSEV: 8 MCU
 SG_ TrvlRStrk : 48|16@1+ (0.01,-20) [-20|20] "mm" Vector__XXX
 SG_ BoomCnfStrk : 32|16@1+ (0.01,-20) [-20|20] "mm" Vector__XXX
 SG_ BoomSwgStrk : 16|16@1+ (0.01,-20) [-20|20] "mm" Vector__XXX
 SG_ ArmStrk : 0|16@1+ (0.01,-20) [-20|20] "mm" Vector__XXX

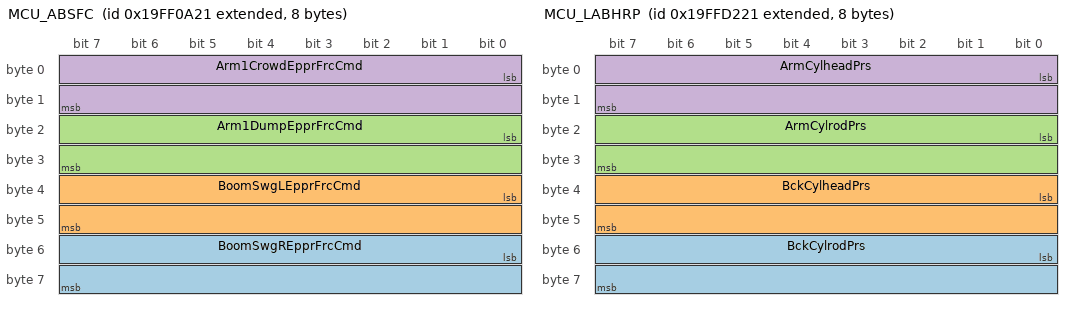
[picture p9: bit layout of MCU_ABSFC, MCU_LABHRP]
BO_ 2583628321 MCU_ABSFC: 8 MCU
 SG_ BoomSwgREpprFrcCmd : 48|16@1+ (0.01,-20) [-20|20] "mm" Vector__XXX
 SG_ BoomSwgLEpprFrcCmd : 32|16@1+ (0.01,-20) [-20|20] "mm" Vector__XXX
 SG_ Arm1DumpEpprFrcCmd : 16|16@1+ (0.01,-20) [-20|20] "mm" Vector__XXX
 SG_ Arm1CrowdEpprFrcCmd : 0|16@1+ (0.01,-20) [-20|20] "mm" Vector__XXX

BO_ 2583661345 MCU_SBUDI: 44 MCU
 SG_ PsmartMd : 320|32@1+ (1,0) [0|4211081215] "kWh" Vector__XXX
 SG_ TotSocBatUsed : 288|32@1+ (1,0) [0|4211081215] "kWh" Vector__XXX
 SG_ LiftMd : 256|32@1+ (1,0) [0|4211081215] "kWh" Vector__XXX
 SG_ TrvlStd : 224|32@1+ (1,0) [0|4211081215] "kWh" Vector__XXX
 SG_ TrvlPwr : 192|32@1+ (1,0) [0|4211081215] "kWh" Vector__XXX
 SG_ Idle : 160|32@1+ (1,0) [0|4211081215] "kWh" Vector__XXX
 SG_ AutoIdle : 128|32@1+ (1,0) [0|4211081215] "kWh" Vector__XXX
 SG_ EcoMd : 96|32@1+ (1,0) [0|4211081215] "kWh" Vector__XXX
 SG_ StdMd : 64|32@1+ (1,0) [0|4211081215] "kWh" Vector__XXX
 SG_ PwrMd : 32|32@1+ (1,0) [0|4211081215] "kWh" Vector__XXX
 SG_ PwrPlusMd : 0|32@1+ (1,0) [0|4211081215] "kWh" Vector__XXX

BO_ 2583679521 MCU_LABHRP: 8 MCU
 SG_ BckCylrodPrs : 48|16@1+ (0.01,0) [0|642.55] "bar" Vector__XXX
 SG_ BckCylheadPrs : 32|16@1+ (0.01,0) [0|642.55] "bar" Vector__XXX
 SG_ ArmCylrodPrs : 16|16@1+ (0.01,0) [0|642.55] "bar" Vector__XXX
 SG_ ArmCylheadPrs : 0|16@1+ (0.01,0) [0|642.55] "bar" Vector__XXX

BO_ 2583679777 MCU_LASP: 8 MCU
 SG_ BckAngPct : 16|16@1+ (0.01,0) [-321.27|321.28] "%" Vector__XXX
 SG_ ArmAngPct : 0|16@1+ (0.01,0) [-321.27|321.28] "%" Vector__XXX

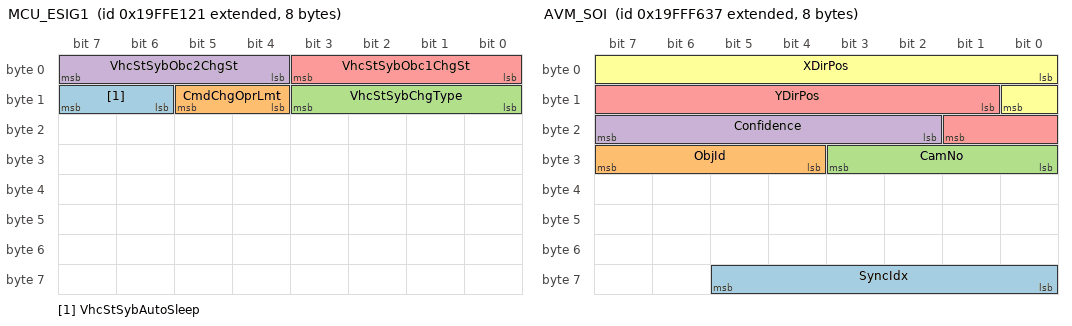
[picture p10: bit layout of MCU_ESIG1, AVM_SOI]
BO_ 2583683361 MCU_ESIG1: 8 MCU
 SG_ VhcStSybAutoSleep : 14|2@1+ (1,0) [0|3] "" Vector__XXX
 SG_ CmdChgOprLmt : 12|2@1+ (1,0) [0|3] "" Vector__XXX
 SG_ VhcStSybChgType : 8|4@1+ (1,0) [0|15] "" Vector__XXX
 SG_ VhcStSybObc2ChgSt : 4|4@1+ (1,0) [0|15] "" Vector__XXX
 SG_ VhcStSybObc1ChgSt : 0|4@1+ (1,0) [0|15] "" Vector__XXX

BO_ 2583661096 GP_GPI: 8 GP
 SG_ GeoidalHgt : 0|24@1+ (0.001,-8388.608) [-8388.608|8388.607] "m" Vector__XXX

BO_ 2583688759 AVM_SOI: 8 AVM
 SG_ SyncIdx : 56|6@1+ (1,0) [0|63] "" Vector__XXX
 SG_ ObjId : 28|4@1+ (1,0) [0|10] "" Vector__XXX
 SG_ CamNo : 24|4@1+ (1,0) [0|5] "ea" Vector__XXX
 SG_ Confidence : 18|6@1+ (2,0) [0|100] "%" Vector__XXX
 SG_ YDirPos : 9|9@1+ (0.1,-16) [-16|16] "m" Vector__XXX
 SG_ XDirPos : 0|9@1+ (0.1,-16) [-16|16] "m" Vector__XXX

BO_ 2583688624 XCU_DLC: 8 XCU
 SG_ BrkLmtCmd : 8|8@1+ (1,-125) [-125|125] "%" Vector__XXX
 SG_ AccLmtCmd : 0|8@1+ (1,-125) [-125|125] "%" Vector__XXX

BO_ 2583689136 XCU_XOI: 8 XCU
 SG_ SyncIdx : 56|8@1+ (1,0) [0|255] "" Vector__XXX
 SG_ FusionOdinZone6 : 51|3@1+ (1,0) [0|7] "" Vector__XXX
 SG_ FusionOdinZone5 : 48|3@1+ (1,0) [0|7] "" Vector__XXX
 SG_ FusionOdinZone4 : 45|3@1+ (1,0) [0|7] "" Vector__XXX
 SG_ FusionOdinZone3 : 42|3@1+ (1,0) [0|7] "" Vector__XXX
 SG_ FusionOdinZone2 : 39|3@1+ (1,0) [0|7] "" Vector__XXX
 SG_ FusionOdinZone1 : 36|3@1+ (1,0) [0|7] "" Vector__XXX
 SG_ RadarOdinZone6 : 33|3@1+ (1,0) [0|7] "" Vector__XXX
 SG_ RadarOdinZone5 : 30|3@1+ (1,0) [0|7] "" Vector__XXX
 SG_ RadarOdinZone4 : 27|3@1+ (1,0) [0|7] "" Vector__XXX
 SG_ RadarOdinZone3 : 24|3@1+ (1,0) [0|7] "" Vector__XXX
 SG_ RadarOdinZone2 : 21|3@1+ (1,0) [0|7] "" Vector__XXX
 SG_ RadarOdinZone1 : 18|3@1+ (1,0) [0|7] "" Vector__XXX
 SG_ SavmOdinZone6 : 15|3@1+ (1,0) [0|7] "" Vector__XXX
 SG_ SavmOdinZone5 : 12|3@1+ (1,0) [0|7] "" Vector__XXX
 SG_ SavmOdinZone4 : 9|3@1+ (1,0) [0|7] "" Vector__XXX
 SG_ SavmOdinZone3 : 6|3@1+ (1,0) [0|7] "" Vector__XXX
 SG_ SavmOdinZone2 : 3|3@1+ (1,0) [0|7] "" Vector__XXX
 SG_ SavmOdinZone1 : 0|3@1+ (1,0) [0|7] "" Vector__XXX

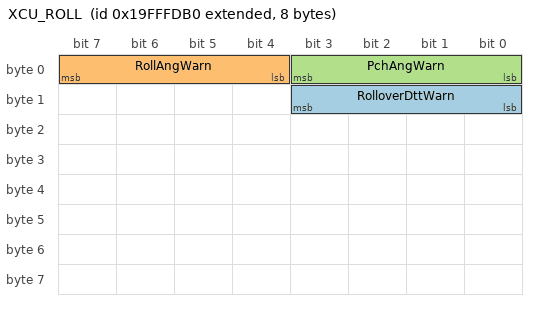
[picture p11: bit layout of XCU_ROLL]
BO_ 2583690672 XCU_ROLL: 8 XCU
 SG_ RolloverDttWarn : 8|4@1+ (1,0) [0|15] "" Vector__XXX
 SG_ RollAngWarn : 4|4@1+ (1,0) [0|15] "" Vector__XXX
 SG_ PchAngWarn : 0|4@1+ (1,0) [0|15] "" Vector__XXX

BO_ 2566865953 MCU_SIG2: 8 MCU
 SG_ HstTractionLvSel : 63|1@1+ (1,0) [0|1] "" Vector__XXX
 SG_ FltHold : 62|1@1+ (1,0) [0|1] "" Vector__XXX
 SG_ Adb : 60|2@1+ (1,0) [0|3] "" Vector__XXX
 SG_ Cruise : 59|1@1+ (1,0) [0|1] "" Vector__XXX
 SG_ WhlDrvMd : 57|2@1+ (1,0) [0|3] "" Vector__XXX
 SG_ DesMchShtDn : 56|1@1+ (1,0) [0|1] "" Vector__XXX
 SG_ FrcRgnStp : 55|1@1+ (1,0) [0|1] "" Vector__XXX
 SG_ FrcRgnScs : 54|1@1+ (1,0) [0|1] "" Vector__XXX
 SG_ WghCnt : 53|1@1+ (1,0) [0|1] "" Vector__XXX
 SG_ MapCreateProg : 48|5@1+ (1,0) [0|31] "" Vector__XXX
 SG_ AngSsTunReq : 47|1@1+ (1,0) [0|1] "" Vector__XXX
 SG_ ZeroCalbReq : 46|1@1+ (1,0) [0|1] "" Vector__XXX
 SG_ WarmUp : 45|1@1+ (1,0) [0|1] "" Vector__XXX
 SG_ MapCreatReady : 44|1@1+ (1,0) [0|1] "" Vector__XXX
 SG_ ColdStart : 40|4@1+ (1,0) [0|15] "" Vector__XXX
 SG_ WghTooHv : 38|1@1+ (1,0) [0|1] "" Vector__XXX
 SG_ WghPoorLft : 37|1@1+ (1,0) [0|1] "" Vector__XXX
 SG_ WghStartPosHh : 36|1@1+ (1,0) [0|1] "" Vector__XXX
 SG_ WghSpdBuc : 35|1@1+ (1,0) [0|1] "" Vector__XXX
 SG_ WghUnderSpd : 34|1@1+ (1,0) [0|1] "" Vector__XXX
 SG_ RrDefst : 33|1@1+ (1,0) [0|1] "" Vector__XXX
 SG_ EmgMd : 32|1@1+ (1,0) [0|1] "" Vector__XXX
 SG_ OprMd : 30|2@1+ (1,0) [0|3] "" Vector__XXX
 SG_ OprPowMd : 26|4@1+ (1,0) [0|15] "" Vector__XXX
 SG_ HstMdWld : 24|2@1+ (1,0) [0|3] "" Vector__XXX
 SG_ CCO : 23|1@1+ (1,0) [0|250] "minutes" Vector__XXX
 SG_ TrqCvt : 22|1@1+ (1,0) [0|250] "minutes" Vector__XXX
 SG_ TrvMdWld : 20|2@1+ (1,0) [0|3] "" Vector__XXX
 SG_ Creep : 19|1@1+ (1,0) [0|250] "minutes" Vector__XXX
 SG_ ThrtLck : 18|1@1+ (1,0) [0|250] "minutes" Vector__XXX
 SG_ Dhl : 17|1@1+ (1,0) [0|250] "minutes" Vector__XXX
 SG_ LisSw : 16|1@1+ (1,0) [0|250] "minutes" Vector__XXX
 SG_ CoolDrtTm : 8|8@1+ (1,0) [0|250] "minutes" Vector__XXX
 SG_ WifDrtTm : 0|8@1+ (1,0) [0|250] "minutes" Vector__XXX

BO_ 2566838784 ECU_SOFT: 58 can1
 SG_ SwId : 8|32@1+ (1,0) [0|255] "ASCII" Vector__XXX
 SG_ NoOfSwId : 0|8@1+ (1,0) [0|15] "Steps" Vector__XXX

BO_ 2566838858 TGU_SOFT: 36 can1
 SG_ FwBleVer : 200|32@1+ (1,0) [0|255] "ASCII" Vector__XXX
 SG_ FwBleYy : 192|8@1+ (1,1985) [1985|2235] "year" Vector__XXX
 SG_ FwBleDd : 184|8@1+ (0.25,0) [0|62.5] "days" Vector__XXX
 SG_ FwBleMm : 176|8@1+ (1,0) [0|250] "month" Vector__XXX
 SG_ FwEsuVer : 144|32@1+ (1,0) [0|255] "ASCII" Vector__XXX
 SG_ FwEsuYy : 136|8@1+ (1,1985) [1985|2235] "year" Vector__XXX
 SG_ FwEsuDd : 128|8@1+ (0.25,0) [0|62.5] "days" Vector__XXX
 SG_ FwEsuMm : 120|8@1+ (1,0) [0|250] "month" Vector__XXX
 SG_ FwTguVer : 88|32@1+ (1,0) [0|255] "ASCII" Vector__XXX
 SG_ FwTguYy : 80|8@1+ (1,1985) [1985|2235] "year" Vector__XXX
 SG_ FwTguDd : 72|8@1+ (0.25,0) [0|62.5] "days" Vector__XXX
 SG_ FwTguMm : 64|8@1+ (1,0) [0|250] "month" Vector__XXX
 SG_ SwTguVer : 32|32@1+ (1,0) [0|255] "ASCII" Vector__XXX
 SG_ SwTguYy : 24|8@1+ (1,1985) [1985|2235] "year" Vector__XXX
 SG_ SwTguDd : 16|8@1+ (0.25,0) [0|62.5] "days" Vector__XXX
 SG_ SwTguMm : 8|8@1+ (1,0) [0|250] "month" Vector__XXX
 SG_ VerCnt : 0|8@1+ (1,0) [0|250] "" Vector__XXX

BO_ 2583642401 MCU_MPI: 36 can2
 SG_ TguId : 152|128@1+ (1,0) [0|255] "ASCII" Vector__XXX
 SG_ Oem : 120|32@1+ (1,0) [0|255] "ASCII" Vector__XXX
 SG_ Mch : 0|120@1+ (1,0) [0|255] "ASCII" Vector__XXX

CM_ BO_ 2583659553 "Virtual Joystick Manual Command 1";
CM_ SG_ 2583659553 VtualJoyMcTrvlRCmd "Virutal Joystick MC Travel Right Cmd";
CM_ SG_ 2583659553 VtualJoyMcTrvlLCmd "Virutal Joystick MC Travel Left Cmd";
CM_ SG_ 2583659553 VtualJoyMcSwgCmd "Virutal Joystick MC Swing Cmd";
CM_ SG_ 2583659553 VtualJoyMcBckCmd "Virtual Joystick MC Bucket Cmd";
CM_ SG_ 2583659553 VtualJoyMcArmCmd "Virtual Joystick MC Arm Cmd";
CM_ SG_ 2583659553 VtualJoyMcBoomCmd "Virtual Joystick MC Boom Cmd";
CM_ BO_ 2583660065 "EPOS Status Message to MC controller";
CM_ SG_ 2583660065 EstopTpr "E-stop Temporary Stop";
CM_ SG_ 2583660065 FuncFault "Functional Fault";
CM_ SG_ 2583660065 GrdAstOptimizedCtrlMdSt "Grade Assist Optimized Control Mode Status";
CM_ SG_ 2583660065 InterlckSt "Interlock State";
CM_ SG_ 2583660065 AutoSt "Auto State";
CM_ BO_ 2583658336 "Weighing Calibration Parameter Data ";
CM_ SG_ 2583658336 WghBckZeroWeight "Weighing Bucket Zero Weight";
CM_ SG_ 2583658336 WghBckWeight "Weighing Bucket Weight";
CM_ SG_ 2583658336 WghFrLinkPrmt7 "Weighing Front Link Parameter 7";
CM_ SG_ 2583658336 WghFrLinkPrmt6 "Weighing Front Link Parameter 6";
CM_ SG_ 2583658336 WghFrLinkPrmt5 "Weighing Front Link Parameter 5";
CM_ SG_ 2583658336 WghFrLinkPrmt4 "Weighing Front Link Parameter 4";
CM_ SG_ 2583658336 WghFrLinkPrmt3 "Weighing Front Link Parameter 3";
CM_ SG_ 2583658336 WghFrLinkPrmt2 "Weighing Front Link Parameter 2";
CM_ SG_ 2583658336 WghFrLinkPrmt1 "Weighing Front Link Parameter 1";
CM_ SG_ 2583658336 ArmCylStribeckFrcCoefc "Arm Cylinder Stribeck Friction Coefficient";
CM_ SG_ 2583658336 ArmCylViscousFrcCoefc "Arm Cylinder Viscous Friction Coefficient";
CM_ SG_ 2583658336 ArmCylPrsClmbFrcCoefc "Arm Cylinder Pressure Coulomb Friction Coefficient";
CM_ SG_ 2583658336 ArmCylClmbFrcCoefc "Arm Cylinder Coulomb Friction Coefficient";
CM_ SG_ 2583658336 ArmCylPrsDrpFrcCoefc "Arm Cylinder Pressure Drop Friction Coefficient";
CM_ SG_ 2583658336 BoomCylStribeckFrcCoefc "Boom Cylinder Stribeck Friction Coefficient";
CM_ SG_ 2583658336 BoomCylViscousFrcCoefc "Boom Cylinder Viscous Friction Coefficient";
CM_ SG_ 2583658336 BoomCylPrsClmbFrcCoefc "Boom Cylinder Pressure Coulomb Friction Coefficient";
CM_ SG_ 2583658336 BoomCylClmbFrcCoefc "Boom Cylinder Coulomb Friction Coefficient";
CM_ SG_ 2583658336 BoomCylPrsDrpFrcCoefc "Boom Cylinder Pressure Drop Friction Coefficient";
CM_ BO_ 2583658160 "Weighing Calibration Cylinder Velocity 2";
CM_ SG_ 2583658160 TgBckCylVelocityUpLm "Target Bucket Cylinder Velocity; Upper Limit";
CM_ SG_ 2583658160 TgBckCylVelocityLwLm "Target Bucket Cylinder Velocity; Lower Limit";
CM_ SG_ 2583658160 CurBckCylVelocity "Current Bucket Cylinder Velocity";
CM_ BO_ 2566908592 "MC Weighing Info Group";
CM_ SG_ 2566908592 TiltRttArg "Indicator Symbol; Tilt-Rotator Arrangement";
CM_ SG_ 2566908592 GnssSt "GNSS Status";
CM_ SG_ 2566908592 VhcStFineSwgTprDsb "Vehicle Status; Fine Swing Temporary Disable";
CM_ SG_ 2566908592 IndSymbolMcTprRlsSt "Indicator Symbol; MC Temporary Release Status";
CM_ SG_ 2566908592 EfenceTgSetSideWallR "E-Fence Target Set; Side Wall Right";
CM_ SG_ 2566908592 EfenceWarnSideWallR "E-Fence Warning; Side Wall Right";
CM_ SG_ 2566908592 EfenceWarnSideWallL "E-Fence Warning; Side Wall Left";
CM_ SG_ 2566908592 AssitSwgRh "AssistStatus;SwingRight";
CM_ SG_ 2566908592 AssitSwgLh "AssistStatus;SwingLeft";
CM_ SG_ 2566908592 AssitBck "AssistStatus;Bucket";
CM_ SG_ 2566908592 AssitGrd "AssistStatus;Grade";
CM_ SG_ 2566908592 SafeWrkSideFar "SafeWorkingIndicator;SideFar";
CM_ SG_ 2566908592 SafeWrkSideMid "SafeWorkingIndicator;SideMid";
CM_ SG_ 2566908592 SafeWrkSideNear "SafeWorkingIndicator;SideNear";
CM_ SG_ 2566908592 SafeWrkFrFar "SafeWorkingIndicator;FrontFar";
CM_ SG_ 2566908592 SafeWrkFrMid "SafeWorkingIndicator;FrontMid";
CM_ SG_ 2566908592 SafeWrkFrNear "SafeWorkingIndicator;FrontNear";
CM_ SG_ 2566908592 FrMvGuidArmOut "FrontMovementGuide;ArmOut";
CM_ SG_ 2566908592 FrMvGuidArmIn "FrontMovementGuide;ArmIn";
CM_ SG_ 2566908592 FrMvGuidBoomDn "FrontMovementGuide;BoomDown";
CM_ SG_ 2566908592 FrMvGuidBoomUp "FrontMovementGuide:BoomUp";
CM_ SG_ 2566908592 EfenceTrkWrn "E-fenceWarning;Track";
CM_ SG_ 2566908592 EfenceDzWrn "E-fenceWarning;Dozer";
CM_ SG_ 2566908592 EfenceCabWrn "E-fenceWarning;Cabin";
CM_ SG_ 2566908592 EfenceFSwgRhWrn "E-fenceWarning;SwingRight";
CM_ SG_ 2566908592 EfenceFSwgLhWrn "E-fenceWarning;SwingLeft";
CM_ SG_ 2566908592 EfenceCeilWrn "E-fenceWarning;Ceiling";
CM_ SG_ 2566908592 EfenceFloorWrn "E-fenceWarning;Floor";
CM_ SG_ 2566908592 EfenceWallWrn "E-fenceWarning;Wall";
CM_ BO_ 2566909872 "Lift Assist Data Group";
CM_ SG_ 2566909872 Reach "Reach";
CM_ SG_ 2566909872 Hight "Hight";
CM_ SG_ 2566909872 RatedLoad "RatedLoad";
CM_ SG_ 2566909872 ActLoad "ActualLoad";
CM_ BO_ 2566913200 "MC Weighing Handshake Group 3";
CM_ BO_ 2566913456 "MC Weighing Target Set Value";
CM_ SG_ 2566913456 RandomVal "RandomValue";
CM_ BO_ 2583659184 "Weighing Calibration Joint Angle 2";
CM_ SG_ 2583659184 TgBckJointAngEndPos "Target Bucket Joint Angle; End Position";
CM_ SG_ 2583659184 TgBckJointAngStartPos "Target Bucket Joint Angle; Start Position";
CM_ SG_ 2583659184 CurBckJointAng "Current Bucket Joint Angle";
CM_ BO_ 2583659440 "Advanced Lift Assist Info Group";
CM_ SG_ 2583659440 SafeWrkIndSwgR "Safe Working Indicator; Swing Right";
CM_ SG_ 2583659440 SafeWrkIndSwgL "Safe Working Indicator; Swing Left";
CM_ SG_ 2583659440 SafeWrkInd8Far "Safe Working Indicator; 8_Far";
CM_ SG_ 2583659440 SafeWrkInd8Mid "Safe Working Indicator; 8_Mid";
CM_ SG_ 2583659440 SafeWrkInd8Near "Safe Working Indicator; 8_Near";
CM_ SG_ 2583659440 SafeWrkInd7Far "Safe Working Indicator; 7_Far";
CM_ SG_ 2583659440 SafeWrkInd7Mid "Safe Working Indicator; 7_Mid";
CM_ SG_ 2583659440 SafeWrkInd7Near "Safe Working Indicator; 7_Near";
CM_ SG_ 2583659440 SafeWrkInd6Far "Safe Working Indicator; 6_Far";
CM_ SG_ 2583659440 SafeWrkInd6Mid "Safe Working Indicator; 6_Mid";
CM_ SG_ 2583659440 SafeWrkInd6Near "Safe Working Indicator; 6_Near";
CM_ SG_ 2583659440 SafeWrkInd5Far "Safe Working Indicator; 5_Far";
CM_ SG_ 2583659440 SafeWrkInd5Mid "Safe Working Indicator; 5_Mid";
CM_ SG_ 2583659440 SafeWrkInd5Near "Safe Working Indicator; 5_Near";
CM_ SG_ 2583659440 SafeWrkInd4Far "Safe Working Indicator; 4_Far";
CM_ SG_ 2583659440 SafeWrkInd4Mid "Safe Working Indicator; 4_Mid";
CM_ SG_ 2583659440 SafeWrkInd4Near "Safe Working Indicator; 4_Near";
CM_ SG_ 2583659440 SafeWrkInd3Far "Safe Working Indicator; 3_Far";
CM_ SG_ 2583659440 SafeWrkInd3Mid "Safe Working Indicator; 3_Mid";
CM_ SG_ 2583659440 SafeWrkInd3Near "Safe Working Indicator; 3_Near";
CM_ SG_ 2583659440 SafeWrkInd2Far "Safe Working Indicator; 2_Far";
CM_ SG_ 2583659440 SafeWrkInd2Mid "Safe Working Indicator; 2_Mid";
CM_ SG_ 2583659440 SafeWrkInd2Near "Safe Working Indicator; 2_Near";
CM_ SG_ 2583659440 SafeWrkInd1Far "Safe Working Indicator; 1_Far";
CM_ SG_ 2583659440 SafeWrkInd1Mid "Safe Working Indicator; 1_Mid";
CM_ SG_ 2583659440 SafeWrkInd1Near "Safe Working Indicator; 1_Near";
CM_ SG_ 2583659440 ReliefPressureLm "Relief Pressure Limit";
CM_ SG_ 2583659440 ArmReachInd "Arm Reach Indicator";
CM_ SG_ 2583659440 AdvLiftAssReady "Advanced Lift Assist Ready";
CM_ BO_ 2583659696 "Virtual Joystick Manual Command 1";
CM_ SG_ 2583659696 VtualJoyMcTrvlRCmd "Virutal Joystick MC Travel Right Cmd";
CM_ SG_ 2583659696 VtualJoyMcTrvlLCmd "Virutal Joystick MC Travel Left Cmd";
CM_ SG_ 2583659696 VtualJoyMcSwgCmd "Virutal Joystick MC Swing Cmd";
CM_ SG_ 2583659696 VtualJoyMcBckCmd "Virtual Joystick MC Bucket Cmd";
CM_ SG_ 2583659696 VtualJoyMcArmCmd "Virtual Joystick MC Arm Cmd";
CM_ SG_ 2583659696 VtualJoyMcBoomCmd "Virtual Joystick MC Boom Cmd";
CM_ BO_ 2583659952 "Virtual Joystick Manual Command 2";
CM_ SG_ 2583659952 VtualJoyMcTrAux2Cmd "Virutal Joystick MC TR Aux2 Cmd";
CM_ SG_ 2583659952 VtualJoyMcTrAux1Cmd "Virutal Joystick MC TR Aux1 Cmd";
CM_ SG_ 2583659952 VtualJoyMcTrRttCmd "Virutal Joystick MC TR Rotator Cmd";
CM_ SG_ 2583659952 VtualJoyMcTrTiltCmd "Virtual Joystick MC TR Tilt Cmd";
CM_ SG_ 2583659952 VtualJoyMcOptCmd "Virtual Joystick MC Option Cmd";
CM_ SG_ 2583659952 VtualJoyMcArtiCmd "Virtual Joystick MC Arti Cmd";
CM_ BO_ 2583660464 "MC Request to EPOS Status";
CM_ SG_ 2583660464 SelBckNo "Selected Bucket Number";
CM_ SG_ 2583660464 SelMdHeartbeat "SelectedMode (Heart beat)";
CM_ SG_ 2583660464 ArmingAcptReq "Arming Accept Request";
CM_ SG_ 2583660464 McActCmd "MC Activation Command (TemporaryStop)";
CM_ SG_ 2583660464 GrdAstOptmCtrlMdSt "Grade Assist Optimized Control Mode Status";
CM_ SG_ 2583660464 McItlReq "MC Interlock Request";
CM_ SG_ 2583660464 McReqMd "MC Requested Mode ";
CM_ BO_ 2566911153 "Ambient Lamp Setting Data";
CM_ SG_ 2566911153 AmbLmpColorMd "Ambient Lamp Color Mode";
CM_ SG_ 2566911153 AmbLmpSt "Ambient Lamp State";
CM_ SG_ 2566911153 AmbLmpBrightness "Ambient Lamp Brightness";
CM_ SG_ 2566911153 AmbLmpColor "Ambient Lamp Color";
CM_ BO_ 2566911308 "RC TGU Vehicle Control Command ";
CM_ SG_ 2566911308 SelMdHeartbeat "Selected Mode (Heart beat)";
CM_ SG_ 2566911308 ArmingAcptReq "Arming Accept Request";
CM_ SG_ 2566911308 RmWrkMdSelSig "Remote Work Mode Select Signal";
CM_ SG_ 2566911308 RmTrvlSpdSelSig "Remote Travel Speed Select Signal";
CM_ SG_ 2566911308 RmPwrMdSelSig2 "Remote Power Mode Select Signal 2";
CM_ SG_ 2566911308 RmCtrlActSig "Remote Control Activation Signal";
CM_ SG_ 2566911308 RmItlReq "Remote Interlock Request";
CM_ SG_ 2566911308 RmRpmSig "Remote RPM Signal";
CM_ SG_ 2566911308 RmCtrlReq "Remote Control Request";
CM_ SG_ 2566911308 RmEgStopSt "Remote Emergency Stop Status";
CM_ SG_ 2566911308 RmPwrMdSelSig1 "Remote Power Mode Select signal 1";
CM_ SG_ 2566911308 RmEmgStopOprSig "Remote Emergency Stop Operating Signal";
CM_ SG_ 2566911308 RmFrcRgnOprSig "Remote Forced Regeneration Operating Signal";
CM_ SG_ 2566911308 RmHornOprSig "Remote Horn Operating Signal";
CM_ SG_ 2566911308 RmPltCutoffRlsSvOprSig "Remote Pilot Cut-off Release S/V Operating Signal";
CM_ SG_ 2566911308 RmFineSwgSvOprSig "Remote Fine Swing S/V Operating Signal";
CM_ SG_ 2566911308 RmCbLmpRly2OprSig "Remote Cabin Lamp Relay 2 Operating Signal";
CM_ SG_ 2566911308 RmCbLmpRly1OprSig "Remote Cabin Lamp Relay 1 Operating Signal";
CM_ SG_ 2566911308 RmBodyLmpRlyOprSig "Remote Body Lamp Relay Operating Signal";
CM_ SG_ 2566911308 RmWrkLmpRlyOprSig "Remote Working Lamp Relay Operating Signal";
CM_ BO_ 2566860569 "Aircon Response Message 2";
CM_ SG_ 2566860569 TmpFdbkVlt "Temperature Feedback Voltage";
CM_ SG_ 2566860569 SunLoadVlt "SunLoad Voltage";
CM_ SG_ 2566860569 DuctTmp2Foot "Duct Temperature2_Foot";
CM_ SG_ 2566860569 DuctTmp1Fr "Duct Temperature1_Front";
CM_ SG_ 2566860569 EvaporatorTmp250 "Evaporator Temperature_250";
CM_ SG_ 2566860569 CurIncarTmp "Current Incar Temperature";
CM_ BO_ 2565844776 "GP Setting Message to PHM Controller";
CM_ BO_ 2566867632 "State Information Group 4";
CM_ SG_ 2566867632 WarnPopLimitangexcess "Warning pop-up; Limit angle excess";
CM_ SG_ 2566867632 WarnPopMgMcSsErr "Warning pop-up; MG/MC Sensor Error";
CM_ SG_ 2566867632 McTemporaryRlsPop "MC Temporary Release Pop-up";
CM_ SG_ 2566867632 VhcStStickStr "Vehicle State Symbol; Stick Steering";
CM_ SG_ 2566867632 VhcStFineSwg "Vehicle State Symbol; Fine Swing";
CM_ SG_ 2566867632 ActTrvlSpdforCrwl "Actual Travel Speed for Crawler";
CM_ SG_ 2566867632 ActTrvlStforCrwl "Actual Travel Status for Crawler";
CM_ SG_ 2566867632 VhcStParallelLift "Vehicle State Symbol; Parallel Lift";
CM_ SG_ 2566867632 VhcStFrSspnAuto "Vehicle State Symbol; Front Suspension Auto";
CM_ SG_ 2566867632 RmCrakingSt "Remote Craking Status";
CM_ SG_ 2566867632 IndTrmsColdStart "Indicator Symbol; Transmission Cold Start";
CM_ SG_ 2566867632 VhcStElevatingCabin "Vehicle State Symbol; Elevating Cabin";
CM_ SG_ 2566867632 WarnPopStickStr "Warning Pop-up; Stick Steering";
CM_ SG_ 2566867632 PopCmdThwLvrErr "Pop-up Indication Command; Thumb Wheel Lever Error Pop-up";
CM_ SG_ 2566867632 HpApMd "HP/APMode";
CM_ SG_ 2566867632 GrLmt "VehicleStateSymbol;GearLimit";
CM_ SG_ 2566867632 BodyAng "BodyAngle";
CM_ SG_ 2566867632 WghIndSt "Weighing Indicator State";
CM_ SG_ 2566867632 BrkHold "VehicleStateSymbol;BrakeHold";
CM_ SG_ 2566867632 RtrdSt "RetarderState";
CM_ SG_ 2566867632 PilotCutOffSt "VehicleStateSymbol;PilotCutOffStatus";
CM_ SG_ 2566867632 BodySt "IndicatorSymbol;Bodystate";
CM_ SG_ 2566867632 VhcStGndSaw "VehicleStateSymbol;GroundSaw";
CM_ SG_ 2566867632 PopCmdJoyLvrNtrlErr "Pop-up Indication Command;  Joystick Lever Neutral Error Pop-up";
CM_ SG_ 2566867632 VhcStIntAxleLck "VehicleStateSymbol;InterAxleLock";
CM_ SG_ 2566867632 TrlHhFlowMd "TrackLoaderTypeGraphic;HighFlowMode";
CM_ SG_ 2566867632 ExcAutoBrkAntiFire "ExcavatorTypeSymbol;AutoBreaker,AntiBlankFireIndicator";
CM_ SG_ 2566867632 TrlIntLckOvrd "TrackLoaderTypeSymbol;InterlockOverride";
CM_ SG_ 2566867632 TrlCtrlFlow "TrackLoaderTypeSymbol;ContinuousFlowIndicator";
CM_ SG_ 2566867632 TrlSelfLv "TrackLoaderTypeSymbol;SelfLevelIndicator";
CM_ SG_ 2566867632 TrlHhFlow "TrackLoaderTypeSymbol;HighFlowIndicator";
CM_ BO_ 2583660720 "MC Controller Target Error";
CM_ SG_ 2583660720 Mc3DGrdTgErrorR "3D MC Grading Target Error : Right";
CM_ SG_ 2583660720 Mc3DGrdTgErrorCnt "3D MC Grading Target Error : Center";
CM_ SG_ 2583660720 Mc3DGrdTgErrorL "3D MC Grading Target Error : Left";
CM_ BO_ 2583642698 "TGU Symbol";
CM_ SG_ 2583642698 CellAntType "Cell Antenna Type";
CM_ SG_ 2583642698 CellType "Cell Type Connected";
CM_ SG_ 2583642698 Rssi "RSSI";
CM_ SG_ 2583642698 ActiveNw "Active Network";
CM_ SG_ 2583642698 Provisioned "Provisioned";
CM_ SG_ 2583642698 Connected "Connected";
CM_ BO_ 2565406538 "TMS Unlock Ack";
CM_ SG_ 2565406538 Ack "Ack_Nack";
CM_ BO_ 2566878753 "Telematics Security";
CM_ SG_ 2566878753 ActnDrSec "Activation DR security";
CM_ SG_ 2566878753 WifiAntSt "WiFi Antenna Status";
CM_ SG_ 2566878753 CellAntSt "Cell Antenna Status";
CM_ SG_ 2566878753 GpsAntSt "GPS Antenna Status";
CM_ SG_ 2566878753 SecCmd "Security Command";
CM_ BO_ 2583643176 "Keyless Login";
CM_ SG_ 2583643176 PinCd "PIN Code";
CM_ SG_ 2583643176 DigitalKey "DigitalKey";
CM_ BO_ 2583659809 "Virtual Joystick Manual Command 2";
CM_ SG_ 2583659809 VtualJoyMcTrAux2Cmd "Virutal Joystick MC TR Aux2 Cmd";
CM_ SG_ 2583659809 VtualJoyMcTrAux1Cmd "Virutal Joystick MC TR Aux1 Cmd";
CM_ SG_ 2583659809 VtualJoyMcTrRttCmd "Virutal Joystick MC TR Rotator Cmd";
CM_ SG_ 2583659809 VtualJoyMcTrTiltCmd "Virtual Joystick MC TR Tilt Cmd";
CM_ SG_ 2583659809 VtualJoyMcOptCmd "Virtual Joystick MC Option Cmd";
CM_ SG_ 2583659809 VtualJoyMcArtiCmd "Virtual Joystick MC Arti Cmd";
CM_ BO_ 2583643432 "Digital Key Total List Registered";
CM_ SG_ 2583643432 DkeyListInfo "Digital Key List Information";
CM_ BO_ 2566868513 "State Information Group 5";
CM_ SG_ 2566868513 VhcStSybEmgStrCheck "Vehicle State Symbol; Emergency Steering Check ";
CM_ SG_ 2566868513 CmdBodyLiftLmt "Pop-up Command; Body Lift Limited";
CM_ SG_ 2566868513 VhcStSybAutoHold "Vehicle State Symbol; Auto Hold ";
CM_ SG_ 2566868513 VhcStSybAutoDig "Vehicle State Symbol; Auto Digging";
CM_ SG_ 2566868513 RearRTirePrsLow "Rear Right Tire Pressure Low";
CM_ SG_ 2566868513 RearLTirePrsLow "Rear Left Tire Pressure Low";
CM_ SG_ 2566868513 FrRTirePrsLow "Front Right Tire Pressure Low";
CM_ SG_ 2566868513 FrLTirePrsLow "Front Left Tire Pressure Low";
CM_ SG_ 2566868513 HhFlowAuxSt "High Flow Aux State";
CM_ SG_ 2566868513 IndSybWirelessChgSt "Indicator Symbol; Wireless Charging Status";
CM_ SG_ 2566868513 VhcStSybIdleSpdSet "Vehicle State Symbol; Idle Speed Setting ";
CM_ SG_ 2566868513 GrStMismatchSig "Gear State Mismatch Signal";
CM_ SG_ 2566868513 VhcStSybBrkChg "Vehicle State Symbol; Brake charging";
CM_ SG_ 2566868513 CmdFineSwg "Pop-up Command; Fine Swing";
CM_ SG_ 2566868513 CmdOptLinePrsRf "Pop-up Command;Optional Line Pressure Relief";
CM_ SG_ 2566868513 AdtUserWghCalSt "ADT User Weighing Calibration State";
CM_ SG_ 2566868513 VhcStateSybSpdLimitCtrl "Vehicle State Symbol; Speed Limit Control";
CM_ SG_ 2566868513 TmShftMdSybforLd "T/M Shift Mode Symbol for Loader (HCE)";
CM_ SG_ 2566868513 BckShakeStSig "Bucket Shake Status Signal";
CM_ SG_ 2566868513 CmdForceRegenFail "Pop-up Indication Command; Force Regen Failure Pop-up";
CM_ SG_ 2566868513 DumpBodyOprSig "Dump Body Operation Signal";
CM_ SG_ 2566868513 WghStRefreshSig "Weighing State Refresh Signal";
CM_ SG_ 2566868513 CmdStarterFail "Pop-up Indication Command; Starter Fail Pop-up";
CM_ SG_ 2566868513 IdleSpdSetCond "Idle Speed Setting Condition";
CM_ SG_ 2566868513 CmdRrSspn_SelfLv "Pop-up Indication Command; Rear Suspension_Self Leveling ";
CM_ SG_ 2566868513 VhcStSybRrSspnAuto "Vehicle State Symbol; Rear Suspension Auto";
CM_ SG_ 2566868513 CmdFrSspn "Pop-up Indication Command; Front Suspension";
CM_ BO_ 2365559376 "KeyPad Signal 3";
CM_ SG_ 2365559376 GreenBeaconOprSig "Green Beacon Operate Signal";
CM_ SG_ 2365559376 IdleSpdSetOprSig "Idle Speed Setting Operate Signal";
CM_ SG_ 2365559376 TransverseDiffLckOprSig "Transverse Differential Lock Operate Signal";
CM_ SG_ 2365559376 CruiseOprSig "Cruise Operate Signal";
CM_ SG_ 2365559376 AirconDisplayOn "Aircon Display On";
CM_ SG_ 2365559376 FrcRgnStp "ForcedRegenerationStop";
CM_ SG_ 2365559376 FrcRgn "ForcedRegeneration";
CM_ SG_ 2365559376 BodyKickOut "Body Kick Out";
CM_ SG_ 2365559376 InterAxleLck "Inter Axle Lock";
CM_ SG_ 2365559376 RtdBrkAst "Retarder Brake Assist";
CM_ SG_ 2365559376 QckCplBzOff "Quick Coupler Buzzer Off";
CM_ BO_ 2365559585 "KeyPad Indicate 5";
CM_ SG_ 2365559585 GreenBeaconLInd "Green Beacon Left indicator";
CM_ SG_ 2365559585 GreenBeaconCtrInd "Green Beacon Center indicator";
CM_ SG_ 2365559585 GreenBeaconRInd "Green Beacon Right indicator";
CM_ SG_ 2365559585 IdleSpdSetLInd "Idle Speed Setting Left indicator";
CM_ SG_ 2365559585 IdleSpdSetCtrInd "Idle Speed Setting Center indicator";
CM_ SG_ 2365559585 IdleSpdSetRInd "Idle Speed Setting Right indicator";
CM_ SG_ 2365559585 TransverseDiffLckLOprSig "Transverse Differential Lock Left indicator";
CM_ SG_ 2365559585 TransverseDiffLckCtrOprSig "Transverse Differential Lock Center indicator";
CM_ SG_ 2365559585 TransverseDiffLckROprSig "Transverse Differential Lock Right indicator";
CM_ SG_ 2365559585 CruiseLInd "Cruise Left indicator";
CM_ SG_ 2365559585 CruiseCtrInd "Cruise Center indicator";
CM_ SG_ 2365559585 CruiseRInd "Cruise Right indicator";
CM_ SG_ 2365559585 RtdBrkAstLInd "Retarder Brake Assist Left indicator";
CM_ SG_ 2365559585 RtdBrkAstCtrInd "Retarder Brake Assist Center indicator";
CM_ SG_ 2365559585 RtdBrkAstRInd "Retarder Brake Assist Right indicator";
CM_ SG_ 2365559585 QckCplBzOffLInd "Quick Coupler Buzzer Off Left indicator";
CM_ SG_ 2365559585 QckCplBzOffCtrInd "Quick Coupler Buzzer Off Center indicator";
CM_ SG_ 2365559585 QckCplBzOffRInd "Quick Coupler Buzzer Off Right indicator";
CM_ SG_ 2365559585 FrcRgnStpLInd "ForcedRegenerationStop Left indicator";
CM_ SG_ 2365559585 FrcRgnStpCtrInd "ForcedRegenerationStop Center indicator";
CM_ SG_ 2365559585 FrcRgnStpRInd "ForcedRegenerationStop Right indicator";
CM_ SG_ 2365559585 FrcRgnLInd "ForcedRegeneration Left indicator";
CM_ SG_ 2365559585 FrcRgnCtrInd "ForcedRegeneration Center indicator";
CM_ SG_ 2365559585 FrcRgnRInd "ForcedRegeneration Right indicator";
CM_ SG_ 2365559585 BodyKickOutLInd "Body Kick Out Left indicator";
CM_ SG_ 2365559585 BodyKickOutCtrInd "Body Kick Out Center indicator";
CM_ SG_ 2365559585 BodyKickOutRInd "Body Kick Out Right indicator";
CM_ SG_ 2365559585 InterAxleLckLInd "Inter Axle Lock Left indicator";
CM_ SG_ 2365559585 InterAxleLckCtrInd "Inter Axle Lock Center indicator";
CM_ SG_ 2365559585 InterAxleLckRInd "Inter Axle Lock Right indicator";
CM_ BO_ 2566910903 "Remote Control Configuration ";
CM_ SG_ 2566910903 EmgEgStpSwSt "Emergency Engine Stop Switch Status";
CM_ SG_ 2566910903 RmRpmCmdbyRcu "Remote RPM Command by RCU";
CM_ SG_ 2566910903 RmPwrMdSelSig1 "Remote Power Mode Select signal 1";
CM_ SG_ 2566910903 RmEmgStpOprtSig1 "Remote Emergency Stop Operating Signal 1";
CM_ SG_ 2566910903 RmCtrlMethodSelSt "Remote Control Method Select Status";
CM_ SG_ 2566910903 RmCtrlSelSt "Remote Control Select Status";
CM_ BO_ 2566891510 "Topcon Setting Message to VCU";
CM_ SG_ 2566891510 Mc3DOprtSt "3D MC Operating Status";
CM_ SG_ 2566891510 Mc3DSysReadySt "3D MC System Ready Status";
CM_ BO_ 2583645770 "OTA Install Management";
CM_ SG_ 2583645770 OtaProg "OTA Progress";
CM_ SG_ 2583645770 OtaSt "OTA Status";
CM_ SG_ 2583645770 OtaPackId "OTA Package ID";
CM_ BO_ 2566859041 "Channel Transfer Message";
CM_ SG_ 2566859041 FnrDirForLv1RrMon "FNR Direction for Level1 Rear Monitor";
CM_ BO_ 2566858273 "Active Fault Code List";
CM_ SG_ 2566858273 Afc "Active Fault Code List";
CM_ BO_ 2566858529 "Historical Fault Code List";
CM_ SG_ 2566858529 Hfc "Historical Fault Code List";
CM_ BO_ 2583646026 "API Information";
CM_ SG_ 2583646026 EndPoint "API Endpoint";
CM_ SG_ 2583646026 Key "API Key";
CM_ BO_ 2566725888 "Aftertreatment 2 Gas Oxidation Catalyst";
CM_ SG_ 2566725888 At2GocDifPrsPrlFmi "Aftertreatment 2 Gas Oxidation Catalyst Differential Pressure Preliminary FMI";
CM_ SG_ 2566725888 At2GocOutTmpPrlFmi "Aftertreatment 2 Gas Oxidation Catalyst Outlet Temperature Preliminary FMI";
CM_ SG_ 2566725888 At2GocInTmpPrlFmi "Aftertreatment 2 Gas Oxidation Catalyst Intake Temperature Preliminary FMI";
CM_ SG_ 2566725888 At2GocDifPrs "Aftertreatment 2 Gas Oxidation Catalyst Differential Pressure";
CM_ SG_ 2566725888 At2GocOutTmp "Aftertreatment 2 Gas Oxidation Catalyst Outlet Temperature";
CM_ SG_ 2566725888 At2GocInTmp "Aftertreatment 2 Gas Oxidation Catalyst Intake Temperature";
CM_ BO_ 2566879050 "GPS Information #2 (periodic broadcasting, Terminal -> other controller)";
CM_ SG_ 2566879050 Z "Altitude";
CM_ BO_ 2566913576 "MTSI";
CM_ SG_ 2566913576 CompanyName "Company Name";
CM_ SG_ 2566913576 TgWghofCurTrk "Target Weight of Current Truck";
CM_ SG_ 2566913576 TrkCntFinalTm "Truck Count Final Time";
CM_ SG_ 2566913576 MaterialLoadSt "MaterialsLoadingStatus";
CM_ SG_ 2566913576 TotWghCurTrk "TotalWeightofcurrenttruck";
CM_ SG_ 2566913576 BckCntCurTrk "BucketCountofcurrenttruck";
CM_ SG_ 2566913576 MtrDensity "SelectedMaterialDensity";
CM_ SG_ 2566913576 MtrName "MaterialName";
CM_ SG_ 2566913576 TrkName "TruckName";
CM_ BO_ 2566838880 "Software Identification";
CM_ SG_ 2566838880 PckVer "Package Version";
CM_ SG_ 2566838880 DtLgh "Data Length";
CM_ BO_ 2633947703 "Software Identification";
CM_ SG_ 2633947703 PckVer "Package Version";
CM_ SG_ 2633947703 DtLgh "Data Length";
CM_ BO_ 2566838959 "Software Identification";
CM_ SG_ 2566838959 PckVer "Package Version";
CM_ SG_ 2566838959 DtLgh "Data Length";
CM_ BO_ 2566838960 "Software Identification";
CM_ SG_ 2566838960 PckVer "Package Version";
CM_ SG_ 2566838960 DtLgh "Data Length";
CM_ BO_ 2583660833 "GS520 Source Address";
CM_ SG_ 2583660833 TiltPos "Tilt position";
CM_ SG_ 2583660833 TiltSA "Tilt Source address";
CM_ SG_ 2583660833 BodySA "Body Source address";
CM_ SG_ 2583660833 BoomSA "Boom Source address";
CM_ SG_ 2583660833 ArtiSA "Arti Source address";
CM_ SG_ 2583660833 ArmSA "Arm Source address";
CM_ SG_ 2583660833 BckSA "Bucket Source address";
CM_ BO_ 2566885450 "QR Code Information";
CM_ SG_ 2566885450 PartNo "PartNumber";
CM_ SG_ 2566885450 SerialNo "SerialNumber";
CM_ SG_ 2566885450 MnftCode "ManufacturerCode";
CM_ SG_ 2566885450 ComCode "ComponentCode";
CM_ SG_ 2566885450 Year "Year";
CM_ SG_ 2566885450 Day "Day";
CM_ SG_ 2566885450 Month "Month";
CM_ SG_ 2566885450 SwVer "SWVersion";
CM_ BO_ 2583645258 "Remote Diagnostics Information";
CM_ SG_ 2583645258 RmSetDataList "Remote Setting Data List";
CM_ SG_ 2583645258 GpBtnCtrl "CAN Blackbox Trigger Button";
CM_ SG_ 2583645258 GpPopupReq "Remote Diagnostic - GP Display Popup Request";
CM_ BO_ 2365573153 "TCU CONTROL 1";
CM_ SG_ 2365573153 MsgChecksum "Message Checksum";
CM_ SG_ 2365573153 MsgCnt "Message Counter";
CM_ SG_ 2365573153 KickDownAct "Kick Down Activation";
CM_ SG_ 2365573153 SecondFnrEnable "2nd FNR Enable";
CM_ SG_ 2365573153 SecondFnr "2nd FNR";
CM_ SG_ 2365573153 ReqEgMd "Request Engine Mode";
CM_ SG_ 2365573153 CrpCtrlSpdRange "Creep Control Speed Range";
CM_ SG_ 2365573153 CrpCtrlAct "Creep Control Activation";
CM_ SG_ 2365573153 TractionLvSel "Traction Level Selection";
CM_ SG_ 2365573153 TractionCtrlMd "Traction Control Mode";
CM_ SG_ 2365573153 CstSpdCtrlReqSpd "Constant Speed Control Requested Speed";
CM_ SG_ 2365573153 ThrtLck "Throttle Lock";
CM_ SG_ 2365573153 DmsActCmd "DMS Activation Command";
CM_ SG_ 2365573153 WarmUp "Warm Up";
CM_ SG_ 2365573153 AutoIdle "Auto Idle";
CM_ BO_ 2365573409 "TCU CONTROL 2";
CM_ SG_ 2365573409 MsgChecksum "Message Checksum";
CM_ SG_ 2365573409 MsgCnt "Message Counter";
CM_ SG_ 2365573409 HydTmp "Hydraulic Temperature";
CM_ SG_ 2365573409 RvsLmtSpdCtrl "Reverse Limit Speed Control";
CM_ SG_ 2365573409 VariableSpdCtrl "Variable Speed Control";
CM_ SG_ 2365573409 MaxSpdLmt "Max Speed Limitation";
CM_ SG_ 2365573409 JoyTypeSel "Joystick Type Selection";
CM_ BO_ 2566900739 "HST_3";
CM_ SG_ 2566900739 MsgChecksum "Message Checksum";
CM_ SG_ 2566900739 MsgCnt "Message Counter";
CM_ SG_ 2566900739 LmtRvsSpd "Limited Reverse Speed";
CM_ SG_ 2566900739 InchingPdlAngSs "Inching Pedal Angle Sensor";
CM_ SG_ 2566900739 StPrkBrk "Status Parking Brake";
CM_ SG_ 2566900739 StTmpDpdDrvPdlLmt "Status Temperature Dependent Drive Pedal Limitation";
CM_ SG_ 2566900739 BackUpRly "Back Up Relay";
CM_ SG_ 2566900739 ThrtLckAct "Status of Throttle Lock Activation";
CM_ SG_ 2566900739 ReqEgMd "Request Engine Mode";
CM_ SG_ 2566900739 TractionLvSel "Traction Level Selection";
CM_ SG_ 2566900739 TractionCtrlMd "Traction Control Mode";
CM_ BO_ 2566900995 "HST_4";
CM_ SG_ 2566900995 MsgChecksum "Message Checksum";
CM_ SG_ 2566900995 MsgCnt "Message Counter";
CM_ SG_ 2566900995 CtrlVariableSpd "Controlling Variable Speed";
CM_ BO_ 2566888963 "TCU Machine Configuration Information";
CM_ SG_ 2566888963 AutoShiftIcbConfig "Auto Shift Interchangeability Configuration";
CM_ BO_ 2566881825 "Gauge Data Group 5";
CM_ SG_ 2566881825 BladeLoadPct "Gauge Data; Blade Load Percentage";
CM_ SG_ 2566881825 RHFrSspnCylLv "RH Front Suspension Cylinder Level";
CM_ SG_ 2566881825 LHFrSspnCylLv "LH Front Suspension Cylinder Level";
CM_ BO_ 2566882081 "Warning Symbol Group 4";
CM_ SG_ 2566882081 CoolLvWarneTMSCab "Warning Symbol; Coolant Level Warning_eTMS_Cabin";
CM_ SG_ 2566882081 CoolLvWarneTMS22 "Warning Symbol; Coolant Level Warning_eTMS_2_#2";
CM_ SG_ 2566882081 CoolLvWarneTMS21 "Warning Symbol; Coolant Level Warning_eTMS_2_#1";
CM_ SG_ 2566882081 CoolLvWarneTMS13 "Warning Symbol; Coolant Level Warning_eTMS_1_#3";
CM_ SG_ 2566882081 CoolLvWarneTMS12 "Warning Symbol; Coolant Level Warning_eTMS_1_#2";
CM_ SG_ 2566882081 CoolLvWarneTMS11 "Warning Symbol; Coolant Level Warning_eTMS_1_#1";
CM_ SG_ 2566882081 Ldc2AbnCur "Warning Symbol; LDC 2 Abnormal Current";
CM_ SG_ 2566882081 Ldc1AbnCur "Warning Symbol; LDC 1 Abnormal Current";
CM_ SG_ 2566882081 Ldc2AbnVlt "Warning Symbol; LDC 2 Abnormal Voltage";
CM_ SG_ 2566882081 Ldc1AbnVlt "Warning Symbol; LDC 1 Abnormal Voltage";
CM_ SG_ 2566882081 Imd "Warning Symbol; IMD(Insulation Monitoring Device)";
CM_ SG_ 2566882081 BatSuperCoolWarn "Warning Symbol; Battery SuperCooling Warning";
CM_ SG_ 2566882081 ObcOvrHt "Warning Symbol; OBC Overheat";
CM_ SG_ 2566882081 TrvlIvtOvrHt "Warning Symbol; Travel Inverter Overheat";
CM_ SG_ 2566882081 SwgIvtOvrHt "Warning Symbol; Swing Inverter Overheat";
CM_ SG_ 2566882081 PmpIvtOvrHt "Warning Symbol; Pump Inverter Overheat";
CM_ SG_ 2566882081 TrvlMotOvrHt "Warning Symbol; Travel Motor Overheat";
CM_ SG_ 2566882081 SwgMotOvrHt "Warning Symbol; Swing Motor Overheat";
CM_ SG_ 2566882081 PmpMotOvrHt "Warning Symbol; Pump Motor Overheat";
CM_ BO_ 2566882337 "Warning Symbol Group 5";
CM_ SG_ 2566882337 PmpDrvOvrHt "Warning Symbol; Pump Drive Overheat";
CM_ SG_ 2566882337 AirClnPrsType "Warning Symbol; Air Cleaner (Pressure Type)";
CM_ SG_ 2566882337 PwrStairway "Warning Symbol; Powered Stairway ";
CM_ BO_ 2566882593 "State Information Group 6";
CM_ SG_ 2566882593 CarryAstSt "Carry Assist State";
CM_ SG_ 2566882593 DacMdTransitionInfo "Pop-up Command; DAC Mode Transition Information";
CM_ SG_ 2566882593 TurnSigR "Turn Signal Right";
CM_ SG_ 2566882593 TurnSigL "Turn Signal Left";
CM_ SG_ 2566882593 ApprovalReqforRedPrsRmv "Pop-up Command; Approval request for residual pressure removal";
CM_ BO_ 2583628065 "Rear Pump Spool Stroke Command EV";
CM_ SG_ 2583628065 TrvlRStrk "Travel Right Stroke";
CM_ SG_ 2583628065 BoomCnfStrk "Boom Confluence Stroke";
CM_ SG_ 2583628065 BoomSwgStrk "Boom Swing Stroke";
CM_ SG_ 2583628065 ArmStrk "Arm Stroke";
CM_ BO_ 2583628321 "Arm Boom Swing Forced Command";
CM_ SG_ 2583628321 BoomSwgREpprFrcCmd "Boom-Swing Right EPPR Forced Command";
CM_ SG_ 2583628321 BoomSwgLEpprFrcCmd "Boom-Swing Left EPPR Forced Command";
CM_ SG_ 2583628321 Arm1DumpEpprFrcCmd "Arm 1 Dump EPPR Forced Command";
CM_ SG_ 2583628321 Arm1CrowdEpprFrcCmd "Arm 1 Crowd EPPR Forced Command";
CM_ BO_ 2583661345 "SOC Battery Used Data Information";
CM_ SG_ 2583661345 PsmartMd "P smart Mode";
CM_ SG_ 2583661345 TotSocBatUsed "Total SOC Battery Used";
CM_ SG_ 2583661345 LiftMd "Lift Mode";
CM_ SG_ 2583661345 TrvlStd "TravelStandard";
CM_ SG_ 2583661345 TrvlPwr "TravelPower";
CM_ SG_ 2583661345 Idle "Idle";
CM_ SG_ 2583661345 AutoIdle "Auto Idle";
CM_ SG_ 2583661345 EcoMd "Economy Mode";
CM_ SG_ 2583661345 StdMd "Standard Mode";
CM_ SG_ 2583661345 PwrMd "Power Mode";
CM_ SG_ 2583661345 PwrPlusMd "Power+ Mode";
CM_ BO_ 2583679521 "Loader Arm Bucket Head Rod Pressure";
CM_ SG_ 2583679521 BckCylrodPrs "Bucket cylinder rod pressure";
CM_ SG_ 2583679521 BckCylheadPrs "Bucket cylinder head pressure";
CM_ SG_ 2583679521 ArmCylrodPrs "Arm cylinder rod pressure";
CM_ SG_ 2583679521 ArmCylheadPrs "Arm cylinder head pressure";
CM_ BO_ 2583679777 "Loader Angle Sensor Percentage";
CM_ SG_ 2583679777 BckAngPct "Bucket Angle Percentage";
CM_ SG_ 2583679777 ArmAngPct "Arm Angle Percentage";
CM_ BO_ 2583683361 "Electric State Information Group 1";
CM_ SG_ 2583683361 VhcStSybAutoSleep "Vehicle State Symbol; Auto Sleep";
CM_ SG_ 2583683361 CmdChgOprLmt "Pop-up Command; Charging Operating Limit";
CM_ SG_ 2583683361 VhcStSybChgType "Vehicle State Symbol; charging Type";
CM_ SG_ 2583683361 VhcStSybObc2ChgSt "Vehicle State Symbol; OBC 2 charging State";
CM_ SG_ 2583683361 VhcStSybObc1ChgSt "Vehicle State Symbol; OBC 1 charging State";
CM_ BO_ 2583661096 "GP Processed Information";
CM_ SG_ 2583661096 GeoidalHgt "Geoidal Height";
CM_ BO_ 2583688759 "SAVM Object Information";
CM_ SG_ 2583688759 SyncIdx "Sync Index";
CM_ SG_ 2583688759 ObjId "Object ID";
CM_ SG_ 2583688759 CamNo "Camera Number";
CM_ SG_ 2583688759 Confidence "Confidence";
CM_ SG_ 2583688759 YDirPos "Y-Direction Position";
CM_ SG_ 2583688759 XDirPos "X-Direction Position";
CM_ BO_ 2583688624 "Drive Limit Command";
CM_ SG_ 2583688624 BrkLmtCmd "Brake Limit Cmd";
CM_ SG_ 2583688624 AccLmtCmd "Accel Limit Cmd";
CM_ BO_ 2583689136 "XCU Object Information";
CM_ SG_ 2583689136 SyncIdx "Sync Index";
CM_ SG_ 2583689136 FusionOdinZone6 "Fusion OD in zone 6";
CM_ SG_ 2583689136 FusionOdinZone5 "Fusion OD in zone 5";
CM_ SG_ 2583689136 FusionOdinZone4 "Fusion OD in zone 4";
CM_ SG_ 2583689136 FusionOdinZone3 "Fusion OD in zone 3";
CM_ SG_ 2583689136 FusionOdinZone2 "Fusion OD in zone 2";
CM_ SG_ 2583689136 FusionOdinZone1 "Fusion OD in zone 1";
CM_ SG_ 2583689136 RadarOdinZone6 "RADAR OD in zone 6";
CM_ SG_ 2583689136 RadarOdinZone5 "RADAR OD in zone 5";
CM_ SG_ 2583689136 RadarOdinZone4 "RADAR OD in zone 4";
CM_ SG_ 2583689136 RadarOdinZone3 "RADAR OD in zone 3";
CM_ SG_ 2583689136 RadarOdinZone2 "RADAR OD in zone 2";
CM_ SG_ 2583689136 RadarOdinZone1 "RADAR OD in zone 1";
CM_ SG_ 2583689136 SavmOdinZone6 "SAVM OD in zone 6";
CM_ SG_ 2583689136 SavmOdinZone5 "SAVM OD in zone 5";
CM_ SG_ 2583689136 SavmOdinZone4 "SAVM OD in zone 4";
CM_ SG_ 2583689136 SavmOdinZone3 "SAVM OD in zone 3";
CM_ SG_ 2583689136 SavmOdinZone2 "SAVM OD in zone 2";
CM_ SG_ 2583689136 SavmOdinZone1 "SAVM OD in zone 1";
CM_ BO_ 2583690672 "Rollover Warning";
CM_ SG_ 2583690672 RolloverDttWarn "Rollover Detection Warning";
CM_ SG_ 2583690672 RollAngWarn "Roll Angle Warning";
CM_ SG_ 2583690672 PchAngWarn "Pitch Angle Warning";
CM_ BO_ 2566865953 "State Information Group 2";
CM_ SG_ 2566865953 HstTractionLvSel "WarningPop-up;HSTTractionLevelSelect";
CM_ SG_ 2566865953 FltHold "VehicleStateSymbol;FloatingHolding";
CM_ SG_ 2566865953 Adb "VehicleStateSymbol;ADB";
CM_ SG_ 2566865953 Cruise "VehicleStateSymbol;Cruise";
CM_ SG_ 2566865953 WhlDrvMd "Popup DisplayCommand;4WheelDriveModePop-up";
CM_ SG_ 2566865953 DesMchShtDn "WarningPop-up;DESMachineShutdown";
CM_ SG_ 2566865953 FrcRgnStp "WarningPop-up;ForcedRegenerationStop";
CM_ SG_ 2566865953 FrcRgnScs "WarningPop-up;ForcedRegenerationSuccess";
CM_ SG_ 2566865953 WghCnt "WeighingSignal;WeightCount";
CM_ SG_ 2566865953 MapCreateProg "WeighingSignal;MapCreationProgressStepNo.";
CM_ SG_ 2566865953 AngSsTunReq "WeighingSignal;AngleSensorTunningRequest";
CM_ SG_ 2566865953 ZeroCalbReq "WeighingSignal;ZeroCalibrationRequest";
CM_ SG_ 2566865953 WarmUp "WeighingSignal;WarmUpRequest";
CM_ SG_ 2566865953 MapCreatReady "WeighingSignal;MapCreationReadySignal";
CM_ SG_ 2566865953 ColdStart "WarningPop-up;ColdStart";
CM_ SG_ 2566865953 WghTooHv "WarningPop-up;WeighingTooheavyWarning";
CM_ SG_ 2566865953 WghPoorLft "WarningPop-up;WeighingPoorLiftWarning";
CM_ SG_ 2566865953 WghStartPosHh "WarningPop-up;WeighingStartPositionHighWarning";
CM_ SG_ 2566865953 WghSpdBuc "WarningPop-up;WeighingSpeedBounceWarning";
CM_ SG_ 2566865953 WghUnderSpd "WarningPop-up;WeighingUnderSpeedWarning";
CM_ SG_ 2566865953 RrDefst "IndicatorSymbol;RearDefrost";
CM_ SG_ 2566865953 EmgMd "WarningPop-up;EmergencyMode";
CM_ SG_ 2566865953 OprMd "VehicleStateSymbol;OperatingModeInformation";
CM_ SG_ 2566865953 OprPowMd "VehicleStateSymbol;OperatingPowerModeInformation";
CM_ SG_ 2566865953 HstMdWld "TractionMode(HST)SymbolforLoader";
CM_ SG_ 2566865953 CCO "VehicleStateSymbol;CCO";
CM_ SG_ 2566865953 TrqCvt "VehicleStateSymbol;TorqueConverter";
CM_ SG_ 2566865953 TrvMdWld "TravelModeSymbolforLoader";
CM_ SG_ 2566865953 Creep "VehicleStateSymbol;Creep";
CM_ SG_ 2566865953 ThrtLck "VehicleStateSymbol;ThrottleLock";
CM_ SG_ 2566865953 Dhl "VehicleStateSymbol;DHL";
CM_ SG_ 2566865953 LisSw "VehicleStateSymbol;LISSiwtch";
CM_ SG_ 2566865953 CoolDrtTm "CoolantDeratingTime";
CM_ SG_ 2566865953 WifDrtTm "WIFDeratingTime";
CM_ BO_ 2566838784 "Generated by script";
CM_ SG_ 2566838784 SwId "Software Identification";
CM_ SG_ 2566838784 NoOfSwId "SPN: 965, Number of software identification";
CM_ BO_ 2566838858 "Generated by script";
CM_ SG_ 2566838858 FwBleVer "FW BLE Version";
CM_ SG_ 2566838858 FwBleYy "FW BLE Build Date ; Year";
CM_ SG_ 2566838858 FwBleDd "FW BLE Build Date ; Day";
CM_ SG_ 2566838858 FwBleMm "FW BLE Build Date ; Month";
CM_ SG_ 2566838858 FwEsuVer "FW ESU Version";
CM_ SG_ 2566838858 FwEsuYy "FW ESU Build Date ; Year";
CM_ SG_ 2566838858 FwEsuDd "FW ESU Build Date ; Day";
CM_ SG_ 2566838858 FwEsuMm "FW ESU Build Date ; Month";
CM_ SG_ 2566838858 FwTguVer "FW TGU Version";
CM_ SG_ 2566838858 FwTguYy "FW TGU Build Date ; Year";
CM_ SG_ 2566838858 FwTguDd "FW TGU Build Date ; Day";
CM_ SG_ 2566838858 FwTguMm "FW TGU Build Date ; Month";
CM_ SG_ 2566838858 SwTguVer "SW TGU Version";
CM_ SG_ 2566838858 SwTguYy "SW TGU Build Date ; Year";
CM_ SG_ 2566838858 SwTguDd "SW TGU Build Date ; Day";
CM_ SG_ 2566838858 SwTguMm "SW TGU Build Date ; Month";
CM_ SG_ 2566838858 VerCnt "Number of software identification fields(N)";
CM_ BO_ 2583642401 "Generated by script";
CM_ SG_ 2583642401 TguId "SPN: 517455, Terminal Serial Number";
CM_ SG_ 2583642401 Oem "SPN: 517450, OEM Information";
CM_ SG_ 2583642401 Mch "SPN: 517449, Machine Asset ID";
BA_DEF_ BO_  "Channel" STRING ;
BA_DEF_ BO_  "VssMsg" STRING ;
BA_DEF_ SG_  "VssSig" STRING ;
BA_DEF_ BO_  "GenMsgCycleTime" INT 0 65535;
BA_DEF_ SG_  "SystemSignalLongSymbol" STRING ;
BA_DEF_DEF_  "Channel" "";
BA_DEF_DEF_  "VssMsg" "";
BA_DEF_DEF_  "VssSig" "";
BA_DEF_DEF_  "GenMsgCycleTime" 0;
BA_DEF_DEF_  "SystemSignalLongSymbol" "";
BA_ "GenMsgCycleTime" BO_ 2583659553 10;
BA_ "VssMsg" BO_ 2583659553 "Mch.MCU.VJMC1";
BA_ "Channel" BO_ 2583659553 "can3";
BA_ "GenMsgCycleTime" BO_ 2583660065 100;
BA_ "VssMsg" BO_ 2583660065 "Mch.MCU.ESMMC";
BA_ "Channel" BO_ 2583660065 "can1";
BA_ "VssMsg" BO_ 2583658336 "Mch.MCU2.WCPD";
BA_ "Channel" BO_ 2583658336 "can1";
BA_ "GenMsgCycleTime" BO_ 2583658160 100;
BA_ "VssMsg" BO_ 2583658160 "Mch.MC3D.WCCV2";
BA_ "Channel" BO_ 2583658160 "can1";
BA_ "GenMsgCycleTime" BO_ 2566908592 100;
BA_ "VssMsg" BO_ 2566908592 "Mch.MC3D.MWIG";
BA_ "Channel" BO_ 2566908592 "can1";
BA_ "GenMsgCycleTime" BO_ 2566909872 100;
BA_ "VssMsg" BO_ 2566909872 "Mch.MC3D.LADG";
BA_ "Channel" BO_ 2566909872 "can1";
BA_ "VssMsg" BO_ 2566913200 "Mch.MC3D.MCWHG3";
BA_ "Channel" BO_ 2566913200 "can1";
BA_ "VssMsg" BO_ 2566913456 "Mch.MC3D.HSDI";
BA_ "Channel" BO_ 2566913456 "can1";
BA_ "GenMsgCycleTime" BO_ 2583659184 100;
BA_ "VssMsg" BO_ 2583659184 "Mch.MC3D.WCJA2";
BA_ "Channel" BO_ 2583659184 "can1";
BA_ "GenMsgCycleTime" BO_ 2583659440 100;
BA_ "VssMsg" BO_ 2583659440 "Mch.MC3D.ALAIG";
BA_ "Channel" BO_ 2583659440 "can1";
BA_ "GenMsgCycleTime" BO_ 2583659696 8;
BA_ "VssMsg" BO_ 2583659696 "Mch.MC3D.VJMC1";
BA_ "Channel" BO_ 2583659696 "can1";
BA_ "GenMsgCycleTime" BO_ 2583659952 10;
BA_ "VssMsg" BO_ 2583659952 "Mch.MC3D.VJMC2";
BA_ "Channel" BO_ 2583659952 "can1";
BA_ "GenMsgCycleTime" BO_ 2583660464 100;
BA_ "VssMsg" BO_ 2583660464 "Mch.MC3D.MCRES";
BA_ "Channel" BO_ 2583660464 "can1";
BA_ "GenMsgCycleTime" BO_ 2566911153 1000;
BA_ "VssMsg" BO_ 2566911153 "Mch.AMBLMP.ALSD";
BA_ "Channel" BO_ 2566911153 "can1";
BA_ "GenMsgCycleTime" BO_ 2566911308 1000;
BA_ "VssMsg" BO_ 2566911308 "Mch.RCTGU.TGUVCC";
BA_ "Channel" BO_ 2566911308 "can1";
BA_ "GenMsgCycleTime" BO_ 2566860569 500;
BA_ "VssMsg" BO_ 2566860569 "Mch.ACCU.ACRM2";
BA_ "Channel" BO_ 2566860569 "can1";
BA_ "VssMsg" BO_ 2565844776 "Mch.GP.GPSMPHM";
BA_ "Channel" BO_ 2565844776 "can1";
BA_ "GenMsgCycleTime" BO_ 2566867632 200;
BA_ "VssMsg" BO_ 2566867632 "Mch.MC3D.SIG4";
BA_ "Channel" BO_ 2566867632 "can1";
BA_ "GenMsgCycleTime" BO_ 2583660720 20;
BA_ "VssMsg" BO_ 2583660720 "Mch.MC3D.XCUTE";
BA_ "Channel" BO_ 2583660720 "can1";
BA_ "GenMsgCycleTime" BO_ 2583642698 10000;
BA_ "VssMsg" BO_ 2583642698 "Mch.TGU.TGUSB";
BA_ "Channel" BO_ 2583642698 "can1";
BA_ "VssMsg" BO_ 2565406538 "Mch.TGU.TUACK";
BA_ "Channel" BO_ 2565406538 "can1";
BA_ "GenMsgCycleTime" BO_ 2566878753 1000;
BA_ "VssMsg" BO_ 2566878753 "Mch.MCU.TSEC";
BA_ "Channel" BO_ 2566878753 "can1";
BA_ "VssMsg" BO_ 2583643176 "Mch.GP.KLLI";
BA_ "Channel" BO_ 2583643176 "can1";
BA_ "GenMsgCycleTime" BO_ 2583659809 10;
BA_ "VssMsg" BO_ 2583659809 "Mch.MCU.VJMC2";
BA_ "Channel" BO_ 2583659809 "can3";
BA_ "VssMsg" BO_ 2583643432 "Mch.GP.DKTL";
BA_ "Channel" BO_ 2583643432 "can1";
BA_ "GenMsgCycleTime" BO_ 2566868513 200;
BA_ "VssMsg" BO_ 2566868513 "Mch.MCU.SIG5";
BA_ "Channel" BO_ 2566868513 "can1";
BA_ "GenMsgCycleTime" BO_ 2365559376 100;
BA_ "VssMsg" BO_ 2365559376 "Mch.KPD1.KEYPADS3";
BA_ "Channel" BO_ 2365559376 "can1";
BA_ "GenMsgCycleTime" BO_ 2365559585 100;
BA_ "VssMsg" BO_ 2365559585 "Mch.MCU.KEYPADI5";
BA_ "Channel" BO_ 2365559585 "can1";
BA_ "GenMsgCycleTime" BO_ 2566910903 1000;
BA_ "VssMsg" BO_ 2566910903 "Mch.RDU.RCC";
BA_ "Channel" BO_ 2566910903 "can1";
BA_ "GenMsgCycleTime" BO_ 2566891510 50;
BA_ "VssMsg" BO_ 2566891510 "Mch.PT3D.TCSMVCU";
BA_ "Channel" BO_ 2566891510 "can1";
BA_ "VssMsg" BO_ 2583645770 "Mch.TGU.OTAIM";
BA_ "Channel" BO_ 2583645770 "can2";
BA_ "GenMsgCycleTime" BO_ 2566859041 200;
BA_ "VssMsg" BO_ 2566859041 "Mch.MCU.CTM";
BA_ "Channel" BO_ 2566859041 "can1";
BA_ "VssMsg" BO_ 2566858273 "Mch.MCU.AFCL";
BA_ "Channel" BO_ 2566858273 "can1";
BA_ "VssMsg" BO_ 2566858529 "Mch.MCU.HFCL";
BA_ "Channel" BO_ 2566858529 "can1";
BA_ "VssMsg" BO_ 2583646026 "Mch.TGU.API";
BA_ "Channel" BO_ 2583646026 "can2";
BA_ "GenMsgCycleTime" BO_ 2566725888 500;
BA_ "VssMsg" BO_ 2566725888 "Mch.ECU.A2GOC";
BA_ "Channel" BO_ 2566725888 "can1";
BA_ "GenMsgCycleTime" BO_ 2566879050 1000;
BA_ "VssMsg" BO_ 2566879050 "Mch.TGU.TMSGPSI2";
BA_ "Channel" BO_ 2566879050 "can1";
BA_ "VssMsg" BO_ 2566913576 "Mch.GP.MTSI";
BA_ "Channel" BO_ 2566913576 "can1";
BA_ "VssMsg" BO_ 2566838880 "Mch.MCU2.SOFT";
BA_ "Channel" BO_ 2566838880 "can2";
BA_ "VssMsg" BO_ 2633947703 "Mch.AVM.SOFT";
BA_ "Channel" BO_ 2633947703 "can2";
BA_ "VssMsg" BO_ 2566838959 "Mch.PHM.SOFT";
BA_ "Channel" BO_ 2566838959 "can2";
BA_ "VssMsg" BO_ 2566838960 "Mch.MC3D.SOFT";
BA_ "Channel" BO_ 2566838960 "can2";
BA_ "GenMsgCycleTime" BO_ 2583660833 1000;
BA_ "VssMsg" BO_ 2583660833 "Mch.MCU.GSA";
BA_ "Channel" BO_ 2583660833 "can1";
BA_ "VssMsg" BO_ 2566885450 "Mch.TGU.QRCI";
BA_ "Channel" BO_ 2566885450 "can1";
BA_ "VssMsg" BO_ 2583645258 "Mch.TGU.RDI";
BA_ "Channel" BO_ 2583645258 "can1";
BA_ "GenMsgCycleTime" BO_ 2365573153 100;
BA_ "VssMsg" BO_ 2365573153 "Mch.TCU.TCTL1";
BA_ "Channel" BO_ 2365573153 "can1";
BA_ "GenMsgCycleTime" BO_ 2365573409 100;
BA_ "VssMsg" BO_ 2365573409 "Mch.TCU.TCTL2";
BA_ "Channel" BO_ 2365573409 "can1";
BA_ "GenMsgCycleTime" BO_ 2566900739 100;
BA_ "VssMsg" BO_ 2566900739 "Mch.TCU.HST3";
BA_ "Channel" BO_ 2566900739 "can1";
BA_ "GenMsgCycleTime" BO_ 2566900995 100;
BA_ "VssMsg" BO_ 2566900995 "Mch.TCU.HST4";
BA_ "Channel" BO_ 2566900995 "can1";
BA_ "VssMsg" BO_ 2566888963 "Mch.TCU.TMCI";
BA_ "Channel" BO_ 2566888963 "can1";
BA_ "GenMsgCycleTime" BO_ 2566881825 200;
BA_ "VssMsg" BO_ 2566881825 "Mch.MCU.GPG5";
BA_ "Channel" BO_ 2566881825 "can1";
BA_ "GenMsgCycleTime" BO_ 2566882081 200;
BA_ "VssMsg" BO_ 2566882081 "Mch.MCU.WSG4";
BA_ "Channel" BO_ 2566882081 "can1";
BA_ "GenMsgCycleTime" BO_ 2566882337 200;
BA_ "VssMsg" BO_ 2566882337 "Mch.MCU.WSG5";
BA_ "Channel" BO_ 2566882337 "can1";
BA_ "GenMsgCycleTime" BO_ 2566882593 200;
BA_ "VssMsg" BO_ 2566882593 "Mch.MCU.SIG6";
BA_ "Channel" BO_ 2566882593 "can1";
BA_ "GenMsgCycleTime" BO_ 2583628065 10;
BA_ "VssMsg" BO_ 2583628065 "Mch.MCU.RPSSEV";
BA_ "Channel" BO_ 2583628065 "can1";
BA_ "VssMsg" BO_ 2583628321 "Mch.MCU.ABSFC";
BA_ "Channel" BO_ 2583628321 "can1";
BA_ "VssMsg" BO_ 2583661345 "Mch.MCU.SBUDI";
BA_ "Channel" BO_ 2583661345 "can1";
BA_ "GenMsgCycleTime" BO_ 2583679521 20;
BA_ "VssMsg" BO_ 2583679521 "Mch.MCU.LABHRP";
BA_ "Channel" BO_ 2583679521 "can1";
BA_ "GenMsgCycleTime" BO_ 2583679777 20;
BA_ "VssMsg" BO_ 2583679777 "Mch.MCU.LASP";
BA_ "Channel" BO_ 2583679777 "can1";
BA_ "GenMsgCycleTime" BO_ 2583683361 200;
BA_ "VssMsg" BO_ 2583683361 "Mch.MCU.ESIG1";
BA_ "Channel" BO_ 2583683361 "can1";
BA_ "GenMsgCycleTime" BO_ 2583661096 1000;
BA_ "VssMsg" BO_ 2583661096 "Mch.GP.GPI";
BA_ "Channel" BO_ 2583661096 "can1";
BA_ "GenMsgCycleTime" BO_ 2583688759 100;
BA_ "VssMsg" BO_ 2583688759 "Mch.AVM.SOI";
BA_ "Channel" BO_ 2583688759 "can1";
BA_ "GenMsgCycleTime" BO_ 2583688624 10;
BA_ "VssMsg" BO_ 2583688624 "Mch.XCU.DLC";
BA_ "Channel" BO_ 2583688624 "can1";
BA_ "GenMsgCycleTime" BO_ 2583689136 100;
BA_ "VssMsg" BO_ 2583689136 "Mch.XCU.XOI";
BA_ "Channel" BO_ 2583689136 "can1";
BA_ "GenMsgCycleTime" BO_ 2583690672 100;
BA_ "VssMsg" BO_ 2583690672 "Mch.XCU.ROLL";
BA_ "Channel" BO_ 2583690672 "can1";
BA_ "GenMsgCycleTime" BO_ 2566865953 200;
BA_ "VssMsg" BO_ 2566865953 "Mch.MCU.SIG2";
BA_ "Channel" BO_ 2566865953 "can1";
BA_ "VssMsg" BO_ 2566838784 "Mch.ECU.SOFT";
BA_ "Channel" BO_ 2566838784 "can1";
BA_ "VssMsg" BO_ 2566838858 "Mch.TGU.SOFT";
BA_ "Channel" BO_ 2566838858 "can1";
BA_ "VssMsg" BO_ 2583642401 "Mch.MCU.MPI";
BA_ "Channel" BO_ 2583642401 "can2";
BA_ "VssSig" SG_ 2583659553 VtualJoyMcTrvlRCmd "Mch.MCU.VJMC1.VtualJoyMcTrvlRCmd";
BA_ "VssSig" SG_ 2583659553 VtualJoyMcTrvlLCmd "Mch.MCU.VJMC1.VtualJoyMcTrvlLCmd";
BA_ "VssSig" SG_ 2583659553 VtualJoyMcSwgCmd "Mch.MCU.VJMC1.VtualJoyMcSwgCmd";
BA_ "VssSig" SG_ 2583659553 VtualJoyMcBckCmd "Mch.MCU.VJMC1.VtualJoyMcBckCmd";
BA_ "VssSig" SG_ 2583659553 VtualJoyMcArmCmd "Mch.MCU.VJMC1.VtualJoyMcArmCmd";
BA_ "VssSig" SG_ 2583659553 VtualJoyMcBoomCmd "Mch.MCU.VJMC1.VtualJoyMcBoomCmd";
BA_ "VssSig" SG_ 2583660065 EstopTpr "Mch.MCU.ESMMC.EstopTpr";
BA_ "VssSig" SG_ 2583660065 FuncFault "Mch.MCU.ESMMC.FuncFault";
BA_ "VssSig" SG_ 2583660065 GrdAstOptimizedCtrlMdSt "Mch.MCU.ESMMC.GrdAstOptimizedCtrlMdSt";
BA_ "VssSig" SG_ 2583660065 InterlckSt "Mch.MCU.ESMMC.InterlckSt";
BA_ "VssSig" SG_ 2583660065 AutoSt "Mch.MCU.ESMMC.AutoSt";
BA_ "VssSig" SG_ 2583658336 WghBckZeroWeight "Mch.MCU2.WCPD.WghBckZeroWeight";
BA_ "VssSig" SG_ 2583658336 WghBckWeight "Mch.MCU2.WCPD.WghBckWeight";
BA_ "VssSig" SG_ 2583658336 WghFrLinkPrmt7 "Mch.MCU2.WCPD.WghFrLinkPrmt7";
BA_ "VssSig" SG_ 2583658336 WghFrLinkPrmt6 "Mch.MCU2.WCPD.WghFrLinkPrmt6";
BA_ "VssSig" SG_ 2583658336 WghFrLinkPrmt5 "Mch.MCU2.WCPD.WghFrLinkPrmt5";
BA_ "VssSig" SG_ 2583658336 WghFrLinkPrmt4 "Mch.MCU2.WCPD.WghFrLinkPrmt4";
BA_ "VssSig" SG_ 2583658336 WghFrLinkPrmt3 "Mch.MCU2.WCPD.WghFrLinkPrmt3";
BA_ "VssSig" SG_ 2583658336 WghFrLinkPrmt2 "Mch.MCU2.WCPD.WghFrLinkPrmt2";
BA_ "VssSig" SG_ 2583658336 WghFrLinkPrmt1 "Mch.MCU2.WCPD.WghFrLinkPrmt1";
BA_ "VssSig" SG_ 2583658336 ArmCylStribeckFrcCoefc "Mch.MCU2.WCPD.ArmCylStribeckFrcCoefc";
BA_ "VssSig" SG_ 2583658336 ArmCylViscousFrcCoefc "Mch.MCU2.WCPD.ArmCylViscousFrcCoefc";
BA_ "VssSig" SG_ 2583658336 ArmCylPrsClmbFrcCoefc "Mch.MCU2.WCPD.ArmCylPrsClmbFrcCoefc";
BA_ "VssSig" SG_ 2583658336 ArmCylClmbFrcCoefc "Mch.MCU2.WCPD.ArmCylClmbFrcCoefc";
BA_ "VssSig" SG_ 2583658336 ArmCylPrsDrpFrcCoefc "Mch.MCU2.WCPD.ArmCylPrsDrpFrcCoefc";
BA_ "VssSig" SG_ 2583658336 BoomCylStribeckFrcCoefc "Mch.MCU2.WCPD.BoomCylStribeckFrcCoefc";
BA_ "VssSig" SG_ 2583658336 BoomCylViscousFrcCoefc "Mch.MCU2.WCPD.BoomCylViscousFrcCoefc";
BA_ "VssSig" SG_ 2583658336 BoomCylPrsClmbFrcCoefc "Mch.MCU2.WCPD.BoomCylPrsClmbFrcCoefc";
BA_ "VssSig" SG_ 2583658336 BoomCylClmbFrcCoefc "Mch.MCU2.WCPD.BoomCylClmbFrcCoefc";
BA_ "VssSig" SG_ 2583658336 BoomCylPrsDrpFrcCoefc "Mch.MCU2.WCPD.BoomCylPrsDrpFrcCoefc";
BA_ "VssSig" SG_ 2583658160 TgBckCylVelocityUpLm "Mch.MC3D.WCCV2.TgBckCylVelocityUpLm";
BA_ "VssSig" SG_ 2583658160 TgBckCylVelocityLwLm "Mch.MC3D.WCCV2.TgBckCylVelocityLwLm";
BA_ "VssSig" SG_ 2583658160 CurBckCylVelocity "Mch.MC3D.WCCV2.CurBckCylVelocity";
BA_ "VssSig" SG_ 2566908592 TiltRttArg "Mch.MC3D.MWIG.TiltRttArg";
BA_ "VssSig" SG_ 2566908592 GnssSt "Mch.MC3D.MWIG.GnssSt";
BA_ "VssSig" SG_ 2566908592 VhcStFineSwgTprDsb "Mch.MC3D.MWIG.VhcStFineSwgTprDsb";
BA_ "VssSig" SG_ 2566908592 IndSymbolMcTprRlsSt "Mch.MC3D.MWIG.IndSymbolMcTprRlsSt";
BA_ "VssSig" SG_ 2566908592 EfenceTgSetSideWallR "Mch.MC3D.MWIG.EfenceTgSetSideWallR";
BA_ "VssSig" SG_ 2566908592 EfenceWarnSideWallR "Mch.MC3D.MWIG.EfenceWarnSideWallR";
BA_ "VssSig" SG_ 2566908592 EfenceWarnSideWallL "Mch.MC3D.MWIG.EfenceWarnSideWallL";
BA_ "VssSig" SG_ 2566908592 AssitSwgRh "Mch.MC3D.MWIG.AssitSwgRh";
BA_ "VssSig" SG_ 2566908592 AssitSwgLh "Mch.MC3D.MWIG.AssitSwgLh";
BA_ "VssSig" SG_ 2566908592 AssitBck "Mch.MC3D.MWIG.AssitBck";
BA_ "VssSig" SG_ 2566908592 AssitGrd "Mch.MC3D.MWIG.AssitGrd";
BA_ "VssSig" SG_ 2566908592 SafeWrkSideFar "Mch.MC3D.MWIG.SafeWrkSideFar";
BA_ "VssSig" SG_ 2566908592 SafeWrkSideMid "Mch.MC3D.MWIG.SafeWrkSideMid";
BA_ "VssSig" SG_ 2566908592 SafeWrkSideNear "Mch.MC3D.MWIG.SafeWrkSideNear";
BA_ "VssSig" SG_ 2566908592 SafeWrkFrFar "Mch.MC3D.MWIG.SafeWrkFrFar";
BA_ "VssSig" SG_ 2566908592 SafeWrkFrMid "Mch.MC3D.MWIG.SafeWrkFrMid";
BA_ "VssSig" SG_ 2566908592 SafeWrkFrNear "Mch.MC3D.MWIG.SafeWrkFrNear";
BA_ "VssSig" SG_ 2566908592 FrMvGuidArmOut "Mch.MC3D.MWIG.FrMvGuidArmOut";
BA_ "VssSig" SG_ 2566908592 FrMvGuidArmIn "Mch.MC3D.MWIG.FrMvGuidArmIn";
BA_ "VssSig" SG_ 2566908592 FrMvGuidBoomDn "Mch.MC3D.MWIG.FrMvGuidBoomDn";
BA_ "VssSig" SG_ 2566908592 FrMvGuidBoomUp "Mch.MC3D.MWIG.FrMvGuidBoomUp";
BA_ "VssSig" SG_ 2566908592 EfenceTrkWrn "Mch.MC3D.MWIG.EfenceTrkWrn";
BA_ "VssSig" SG_ 2566908592 EfenceDzWrn "Mch.MC3D.MWIG.EfenceDzWrn";
BA_ "VssSig" SG_ 2566908592 EfenceCabWrn "Mch.MC3D.MWIG.EfenceCabWrn";
BA_ "VssSig" SG_ 2566908592 EfenceFSwgRhWrn "Mch.MC3D.MWIG.EfenceFSwgRhWrn";
BA_ "VssSig" SG_ 2566908592 EfenceFSwgLhWrn "Mch.MC3D.MWIG.EfenceFSwgLhWrn";
BA_ "VssSig" SG_ 2566908592 EfenceCeilWrn "Mch.MC3D.MWIG.EfenceCeilWrn";
BA_ "VssSig" SG_ 2566908592 EfenceFloorWrn "Mch.MC3D.MWIG.EfenceFloorWrn";
BA_ "VssSig" SG_ 2566908592 EfenceWallWrn "Mch.MC3D.MWIG.EfenceWallWrn";
BA_ "VssSig" SG_ 2566909872 Reach "Mch.MC3D.LADG.Reach";
BA_ "VssSig" SG_ 2566909872 Hight "Mch.MC3D.LADG.Hight";
BA_ "VssSig" SG_ 2566909872 RatedLoad "Mch.MC3D.LADG.RatedLoad";
BA_ "VssSig" SG_ 2566909872 ActLoad "Mch.MC3D.LADG.ActLoad";
BA_ "VssSig" SG_ 2566913456 RandomVal "Mch.MC3D.HSDI.RandomVal";
BA_ "VssSig" SG_ 2583659184 TgBckJointAngEndPos "Mch.MC3D.WCJA2.TgBckJointAngEndPos";
BA_ "VssSig" SG_ 2583659184 TgBckJointAngStartPos "Mch.MC3D.WCJA2.TgBckJointAngStartPos";
BA_ "VssSig" SG_ 2583659184 CurBckJointAng "Mch.MC3D.WCJA2.CurBckJointAng";
BA_ "VssSig" SG_ 2583659440 SafeWrkIndSwgR "Mch.MC3D.ALAIG.SafeWrkIndSwgR";
BA_ "VssSig" SG_ 2583659440 SafeWrkIndSwgL "Mch.MC3D.ALAIG.SafeWrkIndSwgL";
BA_ "VssSig" SG_ 2583659440 SafeWrkInd8Far "Mch.MC3D.ALAIG.SafeWrkInd8Far";
BA_ "VssSig" SG_ 2583659440 SafeWrkInd8Mid "Mch.MC3D.ALAIG.SafeWrkInd8Mid";
BA_ "VssSig" SG_ 2583659440 SafeWrkInd8Near "Mch.MC3D.ALAIG.SafeWrkInd8Near";
BA_ "VssSig" SG_ 2583659440 SafeWrkInd7Far "Mch.MC3D.ALAIG.SafeWrkInd7Far";
BA_ "VssSig" SG_ 2583659440 SafeWrkInd7Mid "Mch.MC3D.ALAIG.SafeWrkInd7Mid";
BA_ "VssSig" SG_ 2583659440 SafeWrkInd7Near "Mch.MC3D.ALAIG.SafeWrkInd7Near";
BA_ "VssSig" SG_ 2583659440 SafeWrkInd6Far "Mch.MC3D.ALAIG.SafeWrkInd6Far";
BA_ "VssSig" SG_ 2583659440 SafeWrkInd6Mid "Mch.MC3D.ALAIG.SafeWrkInd6Mid";
BA_ "VssSig" SG_ 2583659440 SafeWrkInd6Near "Mch.MC3D.ALAIG.SafeWrkInd6Near";
BA_ "VssSig" SG_ 2583659440 SafeWrkInd5Far "Mch.MC3D.ALAIG.SafeWrkInd5Far";
BA_ "VssSig" SG_ 2583659440 SafeWrkInd5Mid "Mch.MC3D.ALAIG.SafeWrkInd5Mid";
BA_ "VssSig" SG_ 2583659440 SafeWrkInd5Near "Mch.MC3D.ALAIG.SafeWrkInd5Near";
BA_ "VssSig" SG_ 2583659440 SafeWrkInd4Far "Mch.MC3D.ALAIG.SafeWrkInd4Far";
BA_ "VssSig" SG_ 2583659440 SafeWrkInd4Mid "Mch.MC3D.ALAIG.SafeWrkInd4Mid";
BA_ "VssSig" SG_ 2583659440 SafeWrkInd4Near "Mch.MC3D.ALAIG.SafeWrkInd4Near";
BA_ "VssSig" SG_ 2583659440 SafeWrkInd3Far "Mch.MC3D.ALAIG.SafeWrkInd3Far";
BA_ "VssSig" SG_ 2583659440 SafeWrkInd3Mid "Mch.MC3D.ALAIG.SafeWrkInd3Mid";
BA_ "VssSig" SG_ 2583659440 SafeWrkInd3Near "Mch.MC3D.ALAIG.SafeWrkInd3Near";
BA_ "VssSig" SG_ 2583659440 SafeWrkInd2Far "Mch.MC3D.ALAIG.SafeWrkInd2Far";
BA_ "VssSig" SG_ 2583659440 SafeWrkInd2Mid "Mch.MC3D.ALAIG.SafeWrkInd2Mid";
BA_ "VssSig" SG_ 2583659440 SafeWrkInd2Near "Mch.MC3D.ALAIG.SafeWrkInd2Near";
BA_ "VssSig" SG_ 2583659440 SafeWrkInd1Far "Mch.MC3D.ALAIG.SafeWrkInd1Far";
BA_ "VssSig" SG_ 2583659440 SafeWrkInd1Mid "Mch.MC3D.ALAIG.SafeWrkInd1Mid";
BA_ "VssSig" SG_ 2583659440 SafeWrkInd1Near "Mch.MC3D.ALAIG.SafeWrkInd1Near";
BA_ "VssSig" SG_ 2583659440 ReliefPressureLm "Mch.MC3D.ALAIG.ReliefPressureLm";
BA_ "VssSig" SG_ 2583659440 ArmReachInd "Mch.MC3D.ALAIG.ArmReachInd";
BA_ "VssSig" SG_ 2583659440 AdvLiftAssReady "Mch.MC3D.ALAIG.AdvLiftAssReady";
BA_ "VssSig" SG_ 2583659696 VtualJoyMcTrvlRCmd "Mch.MC3D.VJMC1.VtualJoyMcTrvlRCmd";
BA_ "VssSig" SG_ 2583659696 VtualJoyMcTrvlLCmd "Mch.MC3D.VJMC1.VtualJoyMcTrvlLCmd";
BA_ "VssSig" SG_ 2583659696 VtualJoyMcSwgCmd "Mch.MC3D.VJMC1.VtualJoyMcSwgCmd";
BA_ "VssSig" SG_ 2583659696 VtualJoyMcBckCmd "Mch.MC3D.VJMC1.VtualJoyMcBckCmd";
BA_ "VssSig" SG_ 2583659696 VtualJoyMcArmCmd "Mch.MC3D.VJMC1.VtualJoyMcArmCmd";
BA_ "VssSig" SG_ 2583659696 VtualJoyMcBoomCmd "Mch.MC3D.VJMC1.VtualJoyMcBoomCmd";
BA_ "VssSig" SG_ 2583659952 VtualJoyMcTrAux2Cmd "Mch.MC3D.VJMC2.VtualJoyMcTrAux2Cmd";
BA_ "VssSig" SG_ 2583659952 VtualJoyMcTrAux1Cmd "Mch.MC3D.VJMC2.VtualJoyMcTrAux1Cmd";
BA_ "VssSig" SG_ 2583659952 VtualJoyMcTrRttCmd "Mch.MC3D.VJMC2.VtualJoyMcTrRttCmd";
BA_ "VssSig" SG_ 2583659952 VtualJoyMcTrTiltCmd "Mch.MC3D.VJMC2.VtualJoyMcTrTiltCmd";
BA_ "VssSig" SG_ 2583659952 VtualJoyMcOptCmd "Mch.MC3D.VJMC2.VtualJoyMcOptCmd";
BA_ "VssSig" SG_ 2583659952 VtualJoyMcArtiCmd "Mch.MC3D.VJMC2.VtualJoyMcArtiCmd";
BA_ "VssSig" SG_ 2583660464 SelBckNo "Mch.MC3D.MCRES.SelBckNo";
BA_ "VssSig" SG_ 2583660464 SelMdHeartbeat "Mch.MC3D.MCRES.SelMdHeartbeat";
BA_ "VssSig" SG_ 2583660464 ArmingAcptReq "Mch.MC3D.MCRES.ArmingAcptReq";
BA_ "VssSig" SG_ 2583660464 McActCmd "Mch.MC3D.MCRES.McActCmd";
BA_ "VssSig" SG_ 2583660464 GrdAstOptmCtrlMdSt "Mch.MC3D.MCRES.GrdAstOptmCtrlMdSt";
BA_ "VssSig" SG_ 2583660464 McItlReq "Mch.MC3D.MCRES.McItlReq";
BA_ "VssSig" SG_ 2583660464 McReqMd "Mch.MC3D.MCRES.McReqMd";
BA_ "VssSig" SG_ 2566911153 AmbLmpColorMd "Mch.AMBLMP.ALSD.AmbLmpColorMd";
BA_ "VssSig" SG_ 2566911153 AmbLmpSt "Mch.AMBLMP.ALSD.AmbLmpSt";
BA_ "VssSig" SG_ 2566911153 AmbLmpBrightness "Mch.AMBLMP.ALSD.AmbLmpBrightness";
BA_ "VssSig" SG_ 2566911153 AmbLmpColor "Mch.AMBLMP.ALSD.AmbLmpColor";
BA_ "VssSig" SG_ 2566911308 SelMdHeartbeat "Mch.RCTGU.TGUVCC.SelMdHeartbeat";
BA_ "VssSig" SG_ 2566911308 ArmingAcptReq "Mch.RCTGU.TGUVCC.ArmingAcptReq";
BA_ "VssSig" SG_ 2566911308 RmWrkMdSelSig "Mch.RCTGU.TGUVCC.RmWrkMdSelSig";
BA_ "VssSig" SG_ 2566911308 RmTrvlSpdSelSig "Mch.RCTGU.TGUVCC.RmTrvlSpdSelSig";
BA_ "VssSig" SG_ 2566911308 RmPwrMdSelSig2 "Mch.RCTGU.TGUVCC.RmPwrMdSelSig2";
BA_ "VssSig" SG_ 2566911308 RmCtrlActSig "Mch.RCTGU.TGUVCC.RmCtrlActSig";
BA_ "VssSig" SG_ 2566911308 RmItlReq "Mch.RCTGU.TGUVCC.RmItlReq";
BA_ "VssSig" SG_ 2566911308 RmRpmSig "Mch.RCTGU.TGUVCC.RmRpmSig";
BA_ "VssSig" SG_ 2566911308 RmCtrlReq "Mch.RCTGU.TGUVCC.RmCtrlReq";
BA_ "VssSig" SG_ 2566911308 RmEgStopSt "Mch.RCTGU.TGUVCC.RmEgStopSt";
BA_ "VssSig" SG_ 2566911308 RmPwrMdSelSig1 "Mch.RCTGU.TGUVCC.RmPwrMdSelSig1";
BA_ "VssSig" SG_ 2566911308 RmEmgStopOprSig "Mch.RCTGU.TGUVCC.RmEmgStopOprSig";
BA_ "VssSig" SG_ 2566911308 RmFrcRgnOprSig "Mch.RCTGU.TGUVCC.RmFrcRgnOprSig";
BA_ "VssSig" SG_ 2566911308 RmHornOprSig "Mch.RCTGU.TGUVCC.RmHornOprSig";
BA_ "VssSig" SG_ 2566911308 RmPltCutoffRlsSvOprSig "Mch.RCTGU.TGUVCC.RmPltCutoffRlsSvOprSig";
BA_ "VssSig" SG_ 2566911308 RmFineSwgSvOprSig "Mch.RCTGU.TGUVCC.RmFineSwgSvOprSig";
BA_ "VssSig" SG_ 2566911308 RmCbLmpRly2OprSig "Mch.RCTGU.TGUVCC.RmCbLmpRly2OprSig";
BA_ "VssSig" SG_ 2566911308 RmCbLmpRly1OprSig "Mch.RCTGU.TGUVCC.RmCbLmpRly1OprSig";
BA_ "VssSig" SG_ 2566911308 RmBodyLmpRlyOprSig "Mch.RCTGU.TGUVCC.RmBodyLmpRlyOprSig";
BA_ "VssSig" SG_ 2566911308 RmWrkLmpRlyOprSig "Mch.RCTGU.TGUVCC.RmWrkLmpRlyOprSig";
BA_ "VssSig" SG_ 2566860569 TmpFdbkVlt "Mch.ACCU.ACRM2.TmpFdbkVlt";
BA_ "VssSig" SG_ 2566860569 SunLoadVlt "Mch.ACCU.ACRM2.SunLoadVlt";
BA_ "VssSig" SG_ 2566860569 DuctTmp2Foot "Mch.ACCU.ACRM2.DuctTmp2Foot";
BA_ "VssSig" SG_ 2566860569 DuctTmp1Fr "Mch.ACCU.ACRM2.DuctTmp1Fr";
BA_ "VssSig" SG_ 2566860569 EvaporatorTmp250 "Mch.ACCU.ACRM2.EvaporatorTmp250";
BA_ "VssSig" SG_ 2566860569 CurIncarTmp "Mch.ACCU.ACRM2.CurIncarTmp";
BA_ "VssSig" SG_ 2566867632 WarnPopLimitangexcess "Mch.MC3D.SIG4.WarnPopLimitangexcess";
BA_ "VssSig" SG_ 2566867632 WarnPopMgMcSsErr "Mch.MC3D.SIG4.WarnPopMgMcSsErr";
BA_ "VssSig" SG_ 2566867632 McTemporaryRlsPop "Mch.MC3D.SIG4.McTemporaryRlsPop";
BA_ "VssSig" SG_ 2566867632 VhcStStickStr "Mch.MC3D.SIG4.VhcStStickStr";
BA_ "VssSig" SG_ 2566867632 VhcStFineSwg "Mch.MC3D.SIG4.VhcStFineSwg";
BA_ "VssSig" SG_ 2566867632 ActTrvlSpdforCrwl "Mch.MC3D.SIG4.ActTrvlSpdforCrwl";
BA_ "VssSig" SG_ 2566867632 ActTrvlStforCrwl "Mch.MC3D.SIG4.ActTrvlStforCrwl";
BA_ "VssSig" SG_ 2566867632 VhcStParallelLift "Mch.MC3D.SIG4.VhcStParallelLift";
BA_ "VssSig" SG_ 2566867632 VhcStFrSspnAuto "Mch.MC3D.SIG4.VhcStFrSspnAuto";
BA_ "VssSig" SG_ 2566867632 RmCrakingSt "Mch.MC3D.SIG4.RmCrakingSt";
BA_ "VssSig" SG_ 2566867632 IndTrmsColdStart "Mch.MC3D.SIG4.IndTrmsColdStart";
BA_ "VssSig" SG_ 2566867632 VhcStElevatingCabin "Mch.MC3D.SIG4.VhcStElevatingCabin";
BA_ "VssSig" SG_ 2566867632 WarnPopStickStr "Mch.MC3D.SIG4.WarnPopStickStr";
BA_ "VssSig" SG_ 2566867632 PopCmdThwLvrErr "Mch.MC3D.SIG4.PopCmdThwLvrErr";
BA_ "VssSig" SG_ 2566867632 HpApMd "Mch.MC3D.SIG4.HpApMd";
BA_ "VssSig" SG_ 2566867632 GrLmt "Mch.MC3D.SIG4.GrLmt";
BA_ "VssSig" SG_ 2566867632 BodyAng "Mch.MC3D.SIG4.BodyAng";
BA_ "VssSig" SG_ 2566867632 WghIndSt "Mch.MC3D.SIG4.WghIndSt";
BA_ "VssSig" SG_ 2566867632 BrkHold "Mch.MC3D.SIG4.BrkHold";
BA_ "VssSig" SG_ 2566867632 RtrdSt "Mch.MC3D.SIG4.RtrdSt";
BA_ "VssSig" SG_ 2566867632 PilotCutOffSt "Mch.MC3D.SIG4.PilotCutOffSt";
BA_ "VssSig" SG_ 2566867632 BodySt "Mch.MC3D.SIG4.BodySt";
BA_ "VssSig" SG_ 2566867632 VhcStGndSaw "Mch.MC3D.SIG4.VhcStGndSaw";
BA_ "VssSig" SG_ 2566867632 PopCmdJoyLvrNtrlErr "Mch.MC3D.SIG4.PopCmdJoyLvrNtrlErr";
BA_ "VssSig" SG_ 2566867632 VhcStIntAxleLck "Mch.MC3D.SIG4.VhcStIntAxleLck";
BA_ "VssSig" SG_ 2566867632 TrlHhFlowMd "Mch.MC3D.SIG4.TrlHhFlowMd";
BA_ "VssSig" SG_ 2566867632 ExcAutoBrkAntiFire "Mch.MC3D.SIG4.ExcAutoBrkAntiFire";
BA_ "VssSig" SG_ 2566867632 TrlIntLckOvrd "Mch.MC3D.SIG4.TrlIntLckOvrd";
BA_ "VssSig" SG_ 2566867632 TrlCtrlFlow "Mch.MC3D.SIG4.TrlCtrlFlow";
BA_ "VssSig" SG_ 2566867632 TrlSelfLv "Mch.MC3D.SIG4.TrlSelfLv";
BA_ "VssSig" SG_ 2566867632 TrlHhFlow "Mch.MC3D.SIG4.TrlHhFlow";
BA_ "VssSig" SG_ 2583660720 Mc3DGrdTgErrorR "Mch.MC3D.XCUTE.Mc3DGrdTgErrorR";
BA_ "VssSig" SG_ 2583660720 Mc3DGrdTgErrorCnt "Mch.MC3D.XCUTE.Mc3DGrdTgErrorCnt";
BA_ "VssSig" SG_ 2583660720 Mc3DGrdTgErrorL "Mch.MC3D.XCUTE.Mc3DGrdTgErrorL";
BA_ "VssSig" SG_ 2583642698 CellAntType "Mch.TGU.TGUSB.CellAntType";
BA_ "VssSig" SG_ 2583642698 CellType "Mch.TGU.TGUSB.CellType";
BA_ "VssSig" SG_ 2583642698 Rssi "Mch.TGU.TGUSB.Rssi";
BA_ "VssSig" SG_ 2583642698 ActiveNw "Mch.TGU.TGUSB.ActiveNw";
BA_ "VssSig" SG_ 2583642698 Provisioned "Mch.TGU.TGUSB.Provisioned";
BA_ "VssSig" SG_ 2583642698 Connected "Mch.TGU.TGUSB.Connected";
BA_ "VssSig" SG_ 2565406538 Ack "Mch.TGU.TUACK.Ack";
BA_ "VssSig" SG_ 2566878753 ActnDrSec "Mch.MCU.TSEC.ActnDrSec";
BA_ "VssSig" SG_ 2566878753 WifiAntSt "Mch.MCU.TSEC.WifiAntSt";
BA_ "VssSig" SG_ 2566878753 CellAntSt "Mch.MCU.TSEC.CellAntSt";
BA_ "VssSig" SG_ 2566878753 GpsAntSt "Mch.MCU.TSEC.GpsAntSt";
BA_ "VssSig" SG_ 2566878753 SecCmd "Mch.MCU.TSEC.SecCmd";
BA_ "VssSig" SG_ 2583643176 PinCd "Mch.GP.KLLI.PinCd";
BA_ "VssSig" SG_ 2583643176 DigitalKey "Mch.GP.KLLI.DigitalKey";
BA_ "VssSig" SG_ 2583659809 VtualJoyMcTrAux2Cmd "Mch.MCU.VJMC2.VtualJoyMcTrAux2Cmd";
BA_ "VssSig" SG_ 2583659809 VtualJoyMcTrAux1Cmd "Mch.MCU.VJMC2.VtualJoyMcTrAux1Cmd";
BA_ "VssSig" SG_ 2583659809 VtualJoyMcTrRttCmd "Mch.MCU.VJMC2.VtualJoyMcTrRttCmd";
BA_ "VssSig" SG_ 2583659809 VtualJoyMcTrTiltCmd "Mch.MCU.VJMC2.VtualJoyMcTrTiltCmd";
BA_ "VssSig" SG_ 2583659809 VtualJoyMcOptCmd "Mch.MCU.VJMC2.VtualJoyMcOptCmd";
BA_ "VssSig" SG_ 2583659809 VtualJoyMcArtiCmd "Mch.MCU.VJMC2.VtualJoyMcArtiCmd";
BA_ "VssSig" SG_ 2583643432 DkeyListInfo "Mch.GP.DKTL.DkeyListInfo";
BA_ "VssSig" SG_ 2566868513 VhcStSybEmgStrCheck "Mch.MCU.SIG5.VhcStSybEmgStrCheck";
BA_ "VssSig" SG_ 2566868513 CmdBodyLiftLmt "Mch.MCU.SIG5.CmdBodyLiftLmt";
BA_ "VssSig" SG_ 2566868513 VhcStSybAutoHold "Mch.MCU.SIG5.VhcStSybAutoHold";
BA_ "VssSig" SG_ 2566868513 VhcStSybAutoDig "Mch.MCU.SIG5.VhcStSybAutoDig";
BA_ "VssSig" SG_ 2566868513 RearRTirePrsLow "Mch.MCU.SIG5.RearRTirePrsLow";
BA_ "VssSig" SG_ 2566868513 RearLTirePrsLow "Mch.MCU.SIG5.RearLTirePrsLow";
BA_ "VssSig" SG_ 2566868513 FrRTirePrsLow "Mch.MCU.SIG5.FrRTirePrsLow";
BA_ "VssSig" SG_ 2566868513 FrLTirePrsLow "Mch.MCU.SIG5.FrLTirePrsLow";
BA_ "VssSig" SG_ 2566868513 HhFlowAuxSt "Mch.MCU.SIG5.HhFlowAuxSt";
BA_ "VssSig" SG_ 2566868513 IndSybWirelessChgSt "Mch.MCU.SIG5.IndSybWirelessChgSt";
BA_ "VssSig" SG_ 2566868513 VhcStSybIdleSpdSet "Mch.MCU.SIG5.VhcStSybIdleSpdSet";
BA_ "VssSig" SG_ 2566868513 GrStMismatchSig "Mch.MCU.SIG5.GrStMismatchSig";
BA_ "VssSig" SG_ 2566868513 VhcStSybBrkChg "Mch.MCU.SIG5.VhcStSybBrkChg";
BA_ "VssSig" SG_ 2566868513 CmdFineSwg "Mch.MCU.SIG5.CmdFineSwg";
BA_ "VssSig" SG_ 2566868513 CmdOptLinePrsRf "Mch.MCU.SIG5.CmdOptLinePrsRf";
BA_ "VssSig" SG_ 2566868513 AdtUserWghCalSt "Mch.MCU.SIG5.AdtUserWghCalSt";
BA_ "VssSig" SG_ 2566868513 VhcStateSybSpdLimitCtrl "Mch.MCU.SIG5.VhcStateSybSpdLimitCtrl";
BA_ "VssSig" SG_ 2566868513 TmShftMdSybforLd "Mch.MCU.SIG5.TmShftMdSybforLd";
BA_ "VssSig" SG_ 2566868513 BckShakeStSig "Mch.MCU.SIG5.BckShakeStSig";
BA_ "VssSig" SG_ 2566868513 CmdForceRegenFail "Mch.MCU.SIG5.CmdForceRegenFail";
BA_ "VssSig" SG_ 2566868513 DumpBodyOprSig "Mch.MCU.SIG5.DumpBodyOprSig";
BA_ "VssSig" SG_ 2566868513 WghStRefreshSig "Mch.MCU.SIG5.WghStRefreshSig";
BA_ "VssSig" SG_ 2566868513 CmdStarterFail "Mch.MCU.SIG5.CmdStarterFail";
BA_ "VssSig" SG_ 2566868513 IdleSpdSetCond "Mch.MCU.SIG5.IdleSpdSetCond";
BA_ "VssSig" SG_ 2566868513 CmdRrSspn_SelfLv "Mch.MCU.SIG5.CmdRrSspn_SelfLv";
BA_ "VssSig" SG_ 2566868513 VhcStSybRrSspnAuto "Mch.MCU.SIG5.VhcStSybRrSspnAuto";
BA_ "VssSig" SG_ 2566868513 CmdFrSspn "Mch.MCU.SIG5.CmdFrSspn";
BA_ "VssSig" SG_ 2365559376 GreenBeaconOprSig "Mch.KPD1.KEYPADS3.GreenBeaconOprSig";
BA_ "VssSig" SG_ 2365559376 IdleSpdSetOprSig "Mch.KPD1.KEYPADS3.IdleSpdSetOprSig";
BA_ "VssSig" SG_ 2365559376 TransverseDiffLckOprSig "Mch.KPD1.KEYPADS3.TransverseDiffLckOprSig";
BA_ "VssSig" SG_ 2365559376 CruiseOprSig "Mch.KPD1.KEYPADS3.CruiseOprSig";
BA_ "VssSig" SG_ 2365559376 AirconDisplayOn "Mch.KPD1.KEYPADS3.AirconDisplayOn";
BA_ "VssSig" SG_ 2365559376 FrcRgnStp "Mch.KPD1.KEYPADS3.FrcRgnStp";
BA_ "VssSig" SG_ 2365559376 FrcRgn "Mch.KPD1.KEYPADS3.FrcRgn";
BA_ "VssSig" SG_ 2365559376 BodyKickOut "Mch.KPD1.KEYPADS3.BodyKickOut";
BA_ "VssSig" SG_ 2365559376 InterAxleLck "Mch.KPD1.KEYPADS3.InterAxleLck";
BA_ "VssSig" SG_ 2365559376 RtdBrkAst "Mch.KPD1.KEYPADS3.RtdBrkAst";
BA_ "VssSig" SG_ 2365559376 QckCplBzOff "Mch.KPD1.KEYPADS3.QckCplBzOff";
BA_ "VssSig" SG_ 2365559585 GreenBeaconLInd "Mch.MCU.KEYPADI5.GreenBeaconLInd";
BA_ "VssSig" SG_ 2365559585 GreenBeaconCtrInd "Mch.MCU.KEYPADI5.GreenBeaconCtrInd";
BA_ "VssSig" SG_ 2365559585 GreenBeaconRInd "Mch.MCU.KEYPADI5.GreenBeaconRInd";
BA_ "VssSig" SG_ 2365559585 IdleSpdSetLInd "Mch.MCU.KEYPADI5.IdleSpdSetLInd";
BA_ "VssSig" SG_ 2365559585 IdleSpdSetCtrInd "Mch.MCU.KEYPADI5.IdleSpdSetCtrInd";
BA_ "VssSig" SG_ 2365559585 IdleSpdSetRInd "Mch.MCU.KEYPADI5.IdleSpdSetRInd";
BA_ "VssSig" SG_ 2365559585 TransverseDiffLckLOprSig "Mch.MCU.KEYPADI5.TransverseDiffLckLOprSig";
BA_ "VssSig" SG_ 2365559585 TransverseDiffLckCtrOprSig "Mch.MCU.KEYPADI5.TransverseDiffLckCtrOprSig";
BA_ "VssSig" SG_ 2365559585 TransverseDiffLckROprSig "Mch.MCU.KEYPADI5.TransverseDiffLckROprSig";
BA_ "VssSig" SG_ 2365559585 CruiseLInd "Mch.MCU.KEYPADI5.CruiseLInd";
BA_ "VssSig" SG_ 2365559585 CruiseCtrInd "Mch.MCU.KEYPADI5.CruiseCtrInd";
BA_ "VssSig" SG_ 2365559585 CruiseRInd "Mch.MCU.KEYPADI5.CruiseRInd";
BA_ "VssSig" SG_ 2365559585 RtdBrkAstLInd "Mch.MCU.KEYPADI5.RtdBrkAstLInd";
BA_ "VssSig" SG_ 2365559585 RtdBrkAstCtrInd "Mch.MCU.KEYPADI5.RtdBrkAstCtrInd";
BA_ "VssSig" SG_ 2365559585 RtdBrkAstRInd "Mch.MCU.KEYPADI5.RtdBrkAstRInd";
BA_ "VssSig" SG_ 2365559585 QckCplBzOffLInd "Mch.MCU.KEYPADI5.QckCplBzOffLInd";
BA_ "VssSig" SG_ 2365559585 QckCplBzOffCtrInd "Mch.MCU.KEYPADI5.QckCplBzOffCtrInd";
BA_ "VssSig" SG_ 2365559585 QckCplBzOffRInd "Mch.MCU.KEYPADI5.QckCplBzOffRInd";
BA_ "VssSig" SG_ 2365559585 FrcRgnStpLInd "Mch.MCU.KEYPADI5.FrcRgnStpLInd";
BA_ "VssSig" SG_ 2365559585 FrcRgnStpCtrInd "Mch.MCU.KEYPADI5.FrcRgnStpCtrInd";
BA_ "VssSig" SG_ 2365559585 FrcRgnStpRInd "Mch.MCU.KEYPADI5.FrcRgnStpRInd";
BA_ "VssSig" SG_ 2365559585 FrcRgnLInd "Mch.MCU.KEYPADI5.FrcRgnLInd";
BA_ "VssSig" SG_ 2365559585 FrcRgnCtrInd "Mch.MCU.KEYPADI5.FrcRgnCtrInd";
BA_ "VssSig" SG_ 2365559585 FrcRgnRInd "Mch.MCU.KEYPADI5.FrcRgnRInd";
BA_ "VssSig" SG_ 2365559585 BodyKickOutLInd "Mch.MCU.KEYPADI5.BodyKickOutLInd";
BA_ "VssSig" SG_ 2365559585 BodyKickOutCtrInd "Mch.MCU.KEYPADI5.BodyKickOutCtrInd";
BA_ "VssSig" SG_ 2365559585 BodyKickOutRInd "Mch.MCU.KEYPADI5.BodyKickOutRInd";
BA_ "VssSig" SG_ 2365559585 InterAxleLckLInd "Mch.MCU.KEYPADI5.InterAxleLckLInd";
BA_ "VssSig" SG_ 2365559585 InterAxleLckCtrInd "Mch.MCU.KEYPADI5.InterAxleLckCtrInd";
BA_ "VssSig" SG_ 2365559585 InterAxleLckRInd "Mch.MCU.KEYPADI5.InterAxleLckRInd";
BA_ "VssSig" SG_ 2566910903 EmgEgStpSwSt "Mch.RDU.RCC.EmgEgStpSwSt";
BA_ "VssSig" SG_ 2566910903 RmRpmCmdbyRcu "Mch.RDU.RCC.RmRpmCmdbyRcu";
BA_ "VssSig" SG_ 2566910903 RmPwrMdSelSig1 "Mch.RDU.RCC.RmPwrMdSelSig1";
BA_ "VssSig" SG_ 2566910903 RmEmgStpOprtSig1 "Mch.RDU.RCC.RmEmgStpOprtSig1";
BA_ "VssSig" SG_ 2566910903 RmCtrlMethodSelSt "Mch.RDU.RCC.RmCtrlMethodSelSt";
BA_ "VssSig" SG_ 2566910903 RmCtrlSelSt "Mch.RDU.RCC.RmCtrlSelSt";
BA_ "VssSig" SG_ 2566891510 Mc3DOprtSt "Mch.PT3D.TCSMVCU.Mc3DOprtSt";
BA_ "VssSig" SG_ 2566891510 Mc3DSysReadySt "Mch.PT3D.TCSMVCU.Mc3DSysReadySt";
BA_ "VssSig" SG_ 2583645770 OtaProg "Mch.TGU.OTAIM.OtaProg";
BA_ "VssSig" SG_ 2583645770 OtaSt "Mch.TGU.OTAIM.OtaSt";
BA_ "VssSig" SG_ 2583645770 OtaPackId "Mch.TGU.OTAIM.OtaPackId";
BA_ "VssSig" SG_ 2566859041 FnrDirForLv1RrMon "Mch.MCU.CTM.FnrDirForLv1RrMon";
BA_ "VssSig" SG_ 2566858273 Afc "Mch.MCU.AFCL.Afc";
BA_ "VssSig" SG_ 2566858529 Hfc "Mch.MCU.HFCL.Hfc";
BA_ "VssSig" SG_ 2583646026 EndPoint "Mch.TGU.API.EndPoint";
BA_ "VssSig" SG_ 2583646026 Key "Mch.TGU.API.Key";
BA_ "VssSig" SG_ 2566725888 At2GocDifPrsPrlFmi "Mch.ECU.A2GOC.At2GocDifPrsPrlFmi";
BA_ "VssSig" SG_ 2566725888 At2GocOutTmpPrlFmi "Mch.ECU.A2GOC.At2GocOutTmpPrlFmi";
BA_ "VssSig" SG_ 2566725888 At2GocInTmpPrlFmi "Mch.ECU.A2GOC.At2GocInTmpPrlFmi";
BA_ "VssSig" SG_ 2566725888 At2GocDifPrs "Mch.ECU.A2GOC.At2GocDifPrs";
BA_ "VssSig" SG_ 2566725888 At2GocOutTmp "Mch.ECU.A2GOC.At2GocOutTmp";
BA_ "VssSig" SG_ 2566725888 At2GocInTmp "Mch.ECU.A2GOC.At2GocInTmp";
BA_ "VssSig" SG_ 2566879050 Z "Mch.TGU.TMSGPSI2.Z";
BA_ "VssSig" SG_ 2566913576 CompanyName "Mch.GP.MTSI.CompanyName";
BA_ "VssSig" SG_ 2566913576 TgWghofCurTrk "Mch.GP.MTSI.TgWghofCurTrk";
BA_ "VssSig" SG_ 2566913576 TrkCntFinalTm "Mch.GP.MTSI.TrkCntFinalTm";
BA_ "VssSig" SG_ 2566913576 MaterialLoadSt "Mch.GP.MTSI.MaterialLoadSt";
BA_ "VssSig" SG_ 2566913576 TotWghCurTrk "Mch.GP.MTSI.TotWghCurTrk";
BA_ "VssSig" SG_ 2566913576 BckCntCurTrk "Mch.GP.MTSI.BckCntCurTrk";
BA_ "VssSig" SG_ 2566913576 MtrDensity "Mch.GP.MTSI.MtrDensity";
BA_ "VssSig" SG_ 2566913576 MtrName "Mch.GP.MTSI.MtrName";
BA_ "VssSig" SG_ 2566913576 TrkName "Mch.GP.MTSI.TrkName";
BA_ "VssSig" SG_ 2566838880 PckVer "Mch.MCU2.SOFT.PckVer";
BA_ "VssSig" SG_ 2566838880 DtLgh "Mch.MCU2.SOFT.DtLgh";
BA_ "VssSig" SG_ 2633947703 PckVer "Mch.AVM.SOFT.PckVer";
BA_ "VssSig" SG_ 2633947703 DtLgh "Mch.AVM.SOFT.DtLgh";
BA_ "VssSig" SG_ 2566838959 PckVer "Mch.PHM.SOFT.PckVer";
BA_ "VssSig" SG_ 2566838959 DtLgh "Mch.PHM.SOFT.DtLgh";
BA_ "VssSig" SG_ 2566838960 PckVer "Mch.MC3D.SOFT.PckVer";
BA_ "VssSig" SG_ 2566838960 DtLgh "Mch.MC3D.SOFT.DtLgh";
BA_ "VssSig" SG_ 2583660833 TiltPos "Mch.MCU.GSA.TiltPos";
BA_ "VssSig" SG_ 2583660833 TiltSA "Mch.MCU.GSA.TiltSA";
BA_ "VssSig" SG_ 2583660833 BodySA "Mch.MCU.GSA.BodySA";
BA_ "VssSig" SG_ 2583660833 BoomSA "Mch.MCU.GSA.BoomSA";
BA_ "VssSig" SG_ 2583660833 ArtiSA "Mch.MCU.GSA.ArtiSA";
BA_ "VssSig" SG_ 2583660833 ArmSA "Mch.MCU.GSA.ArmSA";
BA_ "VssSig" SG_ 2583660833 BckSA "Mch.MCU.GSA.BckSA";
BA_ "VssSig" SG_ 2566885450 PartNo "Mch.TGU.QRCI.PartNo";
BA_ "VssSig" SG_ 2566885450 SerialNo "Mch.TGU.QRCI.SerialNo";
BA_ "VssSig" SG_ 2566885450 MnftCode "Mch.TGU.QRCI.MnftCode";
BA_ "VssSig" SG_ 2566885450 ComCode "Mch.TGU.QRCI.ComCode";
BA_ "VssSig" SG_ 2566885450 Year "Mch.TGU.QRCI.Year";
BA_ "VssSig" SG_ 2566885450 Day "Mch.TGU.QRCI.Day";
BA_ "VssSig" SG_ 2566885450 Month "Mch.TGU.QRCI.Month";
BA_ "VssSig" SG_ 2566885450 SwVer "Mch.TGU.QRCI.SwVer";
BA_ "VssSig" SG_ 2583645258 RmSetDataList "Mch.TGU.RDI.RmSetDataList";
BA_ "VssSig" SG_ 2583645258 GpBtnCtrl "Mch.TGU.RDI.GpBtnCtrl";
BA_ "VssSig" SG_ 2583645258 GpPopupReq "Mch.TGU.RDI.GpPopupReq";
BA_ "VssSig" SG_ 2365573153 MsgChecksum "Mch.TCU.TCTL1.MsgChecksum";
BA_ "VssSig" SG_ 2365573153 MsgCnt "Mch.TCU.TCTL1.MsgCnt";
BA_ "VssSig" SG_ 2365573153 KickDownAct "Mch.TCU.TCTL1.KickDownAct";
BA_ "VssSig" SG_ 2365573153 SecondFnrEnable "Mch.TCU.TCTL1.SecondFnrEnable";
BA_ "VssSig" SG_ 2365573153 SecondFnr "Mch.TCU.TCTL1.SecondFnr";
BA_ "VssSig" SG_ 2365573153 ReqEgMd "Mch.TCU.TCTL1.ReqEgMd";
BA_ "VssSig" SG_ 2365573153 CrpCtrlSpdRange "Mch.TCU.TCTL1.CrpCtrlSpdRange";
BA_ "VssSig" SG_ 2365573153 CrpCtrlAct "Mch.TCU.TCTL1.CrpCtrlAct";
BA_ "VssSig" SG_ 2365573153 TractionLvSel "Mch.TCU.TCTL1.TractionLvSel";
BA_ "VssSig" SG_ 2365573153 TractionCtrlMd "Mch.TCU.TCTL1.TractionCtrlMd";
BA_ "VssSig" SG_ 2365573153 CstSpdCtrlReqSpd "Mch.TCU.TCTL1.CstSpdCtrlReqSpd";
BA_ "VssSig" SG_ 2365573153 ThrtLck "Mch.TCU.TCTL1.ThrtLck";
BA_ "VssSig" SG_ 2365573153 DmsActCmd "Mch.TCU.TCTL1.DmsActCmd";
BA_ "VssSig" SG_ 2365573153 WarmUp "Mch.TCU.TCTL1.WarmUp";
BA_ "VssSig" SG_ 2365573153 AutoIdle "Mch.TCU.TCTL1.AutoIdle";
BA_ "VssSig" SG_ 2365573409 MsgChecksum "Mch.TCU.TCTL2.MsgChecksum";
BA_ "VssSig" SG_ 2365573409 MsgCnt "Mch.TCU.TCTL2.MsgCnt";
BA_ "VssSig" SG_ 2365573409 HydTmp "Mch.TCU.TCTL2.HydTmp";
BA_ "VssSig" SG_ 2365573409 RvsLmtSpdCtrl "Mch.TCU.TCTL2.RvsLmtSpdCtrl";
BA_ "VssSig" SG_ 2365573409 VariableSpdCtrl "Mch.TCU.TCTL2.VariableSpdCtrl";
BA_ "VssSig" SG_ 2365573409 MaxSpdLmt "Mch.TCU.TCTL2.MaxSpdLmt";
BA_ "VssSig" SG_ 2365573409 JoyTypeSel "Mch.TCU.TCTL2.JoyTypeSel";
BA_ "VssSig" SG_ 2566900739 MsgChecksum "Mch.TCU.HST3.MsgChecksum";
BA_ "VssSig" SG_ 2566900739 MsgCnt "Mch.TCU.HST3.MsgCnt";
BA_ "VssSig" SG_ 2566900739 LmtRvsSpd "Mch.TCU.HST3.LmtRvsSpd";
BA_ "VssSig" SG_ 2566900739 InchingPdlAngSs "Mch.TCU.HST3.InchingPdlAngSs";
BA_ "VssSig" SG_ 2566900739 StPrkBrk "Mch.TCU.HST3.StPrkBrk";
BA_ "VssSig" SG_ 2566900739 StTmpDpdDrvPdlLmt "Mch.TCU.HST3.StTmpDpdDrvPdlLmt";
BA_ "VssSig" SG_ 2566900739 BackUpRly "Mch.TCU.HST3.BackUpRly";
BA_ "VssSig" SG_ 2566900739 ThrtLckAct "Mch.TCU.HST3.ThrtLckAct";
BA_ "VssSig" SG_ 2566900739 ReqEgMd "Mch.TCU.HST3.ReqEgMd";
BA_ "VssSig" SG_ 2566900739 TractionLvSel "Mch.TCU.HST3.TractionLvSel";
BA_ "VssSig" SG_ 2566900739 TractionCtrlMd "Mch.TCU.HST3.TractionCtrlMd";
BA_ "VssSig" SG_ 2566900995 MsgChecksum "Mch.TCU.HST4.MsgChecksum";
BA_ "VssSig" SG_ 2566900995 MsgCnt "Mch.TCU.HST4.MsgCnt";
BA_ "VssSig" SG_ 2566900995 CtrlVariableSpd "Mch.TCU.HST4.CtrlVariableSpd";
BA_ "VssSig" SG_ 2566888963 AutoShiftIcbConfig "Mch.TCU.TMCI.AutoShiftIcbConfig";
BA_ "VssSig" SG_ 2566881825 BladeLoadPct "Mch.MCU.GPG5.BladeLoadPct";
BA_ "VssSig" SG_ 2566881825 RHFrSspnCylLv "Mch.MCU.GPG5.RHFrSspnCylLv";
BA_ "VssSig" SG_ 2566881825 LHFrSspnCylLv "Mch.MCU.GPG5.LHFrSspnCylLv";
BA_ "VssSig" SG_ 2566882081 CoolLvWarneTMSCab "Mch.MCU.WSG4.CoolLvWarneTMSCab";
BA_ "VssSig" SG_ 2566882081 CoolLvWarneTMS22 "Mch.MCU.WSG4.CoolLvWarneTMS22";
BA_ "VssSig" SG_ 2566882081 CoolLvWarneTMS21 "Mch.MCU.WSG4.CoolLvWarneTMS21";
BA_ "VssSig" SG_ 2566882081 CoolLvWarneTMS13 "Mch.MCU.WSG4.CoolLvWarneTMS13";
BA_ "VssSig" SG_ 2566882081 CoolLvWarneTMS12 "Mch.MCU.WSG4.CoolLvWarneTMS12";
BA_ "VssSig" SG_ 2566882081 CoolLvWarneTMS11 "Mch.MCU.WSG4.CoolLvWarneTMS11";
BA_ "VssSig" SG_ 2566882081 Ldc2AbnCur "Mch.MCU.WSG4.Ldc2AbnCur";
BA_ "VssSig" SG_ 2566882081 Ldc1AbnCur "Mch.MCU.WSG4.Ldc1AbnCur";
BA_ "VssSig" SG_ 2566882081 Ldc2AbnVlt "Mch.MCU.WSG4.Ldc2AbnVlt";
BA_ "VssSig" SG_ 2566882081 Ldc1AbnVlt "Mch.MCU.WSG4.Ldc1AbnVlt";
BA_ "VssSig" SG_ 2566882081 Imd "Mch.MCU.WSG4.Imd";
BA_ "VssSig" SG_ 2566882081 BatSuperCoolWarn "Mch.MCU.WSG4.BatSuperCoolWarn";
BA_ "VssSig" SG_ 2566882081 ObcOvrHt "Mch.MCU.WSG4.ObcOvrHt";
BA_ "VssSig" SG_ 2566882081 TrvlIvtOvrHt "Mch.MCU.WSG4.TrvlIvtOvrHt";
BA_ "VssSig" SG_ 2566882081 SwgIvtOvrHt "Mch.MCU.WSG4.SwgIvtOvrHt";
BA_ "VssSig" SG_ 2566882081 PmpIvtOvrHt "Mch.MCU.WSG4.PmpIvtOvrHt";
BA_ "VssSig" SG_ 2566882081 TrvlMotOvrHt "Mch.MCU.WSG4.TrvlMotOvrHt";
BA_ "VssSig" SG_ 2566882081 SwgMotOvrHt "Mch.MCU.WSG4.SwgMotOvrHt";
BA_ "VssSig" SG_ 2566882081 PmpMotOvrHt "Mch.MCU.WSG4.PmpMotOvrHt";
BA_ "VssSig" SG_ 2566882337 PmpDrvOvrHt "Mch.MCU.WSG5.PmpDrvOvrHt";
BA_ "VssSig" SG_ 2566882337 AirClnPrsType "Mch.MCU.WSG5.AirClnPrsType";
BA_ "VssSig" SG_ 2566882337 PwrStairway "Mch.MCU.WSG5.PwrStairway";
BA_ "VssSig" SG_ 2566882593 CarryAstSt "Mch.MCU.SIG6.CarryAstSt";
BA_ "VssSig" SG_ 2566882593 DacMdTransitionInfo "Mch.MCU.SIG6.DacMdTransitionInfo";
BA_ "VssSig" SG_ 2566882593 TurnSigR "Mch.MCU.SIG6.TurnSigR";
BA_ "VssSig" SG_ 2566882593 TurnSigL "Mch.MCU.SIG6.TurnSigL";
BA_ "VssSig" SG_ 2566882593 ApprovalReqforRedPrsRmv "Mch.MCU.SIG6.ApprovalReqforRedPrsRmv";
BA_ "VssSig" SG_ 2583628065 TrvlRStrk "Mch.MCU.RPSSEV.TrvlRStrk";
BA_ "VssSig" SG_ 2583628065 BoomCnfStrk "Mch.MCU.RPSSEV.BoomCnfStrk";
BA_ "VssSig" SG_ 2583628065 BoomSwgStrk "Mch.MCU.RPSSEV.BoomSwgStrk";
BA_ "VssSig" SG_ 2583628065 ArmStrk "Mch.MCU.RPSSEV.ArmStrk";
BA_ "VssSig" SG_ 2583628321 BoomSwgREpprFrcCmd "Mch.MCU.ABSFC.BoomSwgREpprFrcCmd";
BA_ "VssSig" SG_ 2583628321 BoomSwgLEpprFrcCmd "Mch.MCU.ABSFC.BoomSwgLEpprFrcCmd";
BA_ "VssSig" SG_ 2583628321 Arm1DumpEpprFrcCmd "Mch.MCU.ABSFC.Arm1DumpEpprFrcCmd";
BA_ "VssSig" SG_ 2583628321 Arm1CrowdEpprFrcCmd "Mch.MCU.ABSFC.Arm1CrowdEpprFrcCmd";
BA_ "VssSig" SG_ 2583661345 PsmartMd "Mch.MCU.SBUDI.PsmartMd";
BA_ "VssSig" SG_ 2583661345 TotSocBatUsed "Mch.MCU.SBUDI.TotSocBatUsed";
BA_ "VssSig" SG_ 2583661345 LiftMd "Mch.MCU.SBUDI.LiftMd";
BA_ "VssSig" SG_ 2583661345 TrvlStd "Mch.MCU.SBUDI.TrvlStd";
BA_ "VssSig" SG_ 2583661345 TrvlPwr "Mch.MCU.SBUDI.TrvlPwr";
BA_ "VssSig" SG_ 2583661345 Idle "Mch.MCU.SBUDI.Idle";
BA_ "VssSig" SG_ 2583661345 AutoIdle "Mch.MCU.SBUDI.AutoIdle";
BA_ "VssSig" SG_ 2583661345 EcoMd "Mch.MCU.SBUDI.EcoMd";
BA_ "VssSig" SG_ 2583661345 StdMd "Mch.MCU.SBUDI.StdMd";
BA_ "VssSig" SG_ 2583661345 PwrMd "Mch.MCU.SBUDI.PwrMd";
BA_ "VssSig" SG_ 2583661345 PwrPlusMd "Mch.MCU.SBUDI.PwrPlusMd";
BA_ "VssSig" SG_ 2583679521 BckCylrodPrs "Mch.MCU.LABHRP.BckCylrodPrs";
BA_ "VssSig" SG_ 2583679521 BckCylheadPrs "Mch.MCU.LABHRP.BckCylheadPrs";
BA_ "VssSig" SG_ 2583679521 ArmCylrodPrs "Mch.MCU.LABHRP.ArmCylrodPrs";
BA_ "VssSig" SG_ 2583679521 ArmCylheadPrs "Mch.MCU.LABHRP.ArmCylheadPrs";
BA_ "VssSig" SG_ 2583679777 BckAngPct "Mch.MCU.LASP.BckAngPct";
BA_ "VssSig" SG_ 2583679777 ArmAngPct "Mch.MCU.LASP.ArmAngPct";
BA_ "VssSig" SG_ 2583683361 VhcStSybAutoSleep "Mch.MCU.ESIG1.VhcStSybAutoSleep";
BA_ "VssSig" SG_ 2583683361 CmdChgOprLmt "Mch.MCU.ESIG1.CmdChgOprLmt";
BA_ "VssSig" SG_ 2583683361 VhcStSybChgType "Mch.MCU.ESIG1.VhcStSybChgType";
BA_ "VssSig" SG_ 2583683361 VhcStSybObc2ChgSt "Mch.MCU.ESIG1.VhcStSybObc2ChgSt";
BA_ "VssSig" SG_ 2583683361 VhcStSybObc1ChgSt "Mch.MCU.ESIG1.VhcStSybObc1ChgSt";
BA_ "VssSig" SG_ 2583661096 GeoidalHgt "Mch.GP.GPI.GeoidalHgt";
BA_ "VssSig" SG_ 2583688759 SyncIdx "Mch.AVM.SOI.SyncIdx";
BA_ "VssSig" SG_ 2583688759 ObjId "Mch.AVM.SOI.ObjId";
BA_ "VssSig" SG_ 2583688759 CamNo "Mch.AVM.SOI.CamNo";
BA_ "VssSig" SG_ 2583688759 Confidence "Mch.AVM.SOI.Confidence";
BA_ "VssSig" SG_ 2583688759 YDirPos "Mch.AVM.SOI.YDirPos";
BA_ "VssSig" SG_ 2583688759 XDirPos "Mch.AVM.SOI.XDirPos";
BA_ "VssSig" SG_ 2583688624 BrkLmtCmd "Mch.XCU.DLC.BrkLmtCmd";
BA_ "VssSig" SG_ 2583688624 AccLmtCmd "Mch.XCU.DLC.AccLmtCmd";
BA_ "VssSig" SG_ 2583689136 SyncIdx "Mch.XCU.XOI.SyncIdx";
BA_ "VssSig" SG_ 2583689136 FusionOdinZone6 "Mch.XCU.XOI.FusionOdinZone6";
BA_ "VssSig" SG_ 2583689136 FusionOdinZone5 "Mch.XCU.XOI.FusionOdinZone5";
BA_ "VssSig" SG_ 2583689136 FusionOdinZone4 "Mch.XCU.XOI.FusionOdinZone4";
BA_ "VssSig" SG_ 2583689136 FusionOdinZone3 "Mch.XCU.XOI.FusionOdinZone3";
BA_ "VssSig" SG_ 2583689136 FusionOdinZone2 "Mch.XCU.XOI.FusionOdinZone2";
BA_ "VssSig" SG_ 2583689136 FusionOdinZone1 "Mch.XCU.XOI.FusionOdinZone1";
BA_ "VssSig" SG_ 2583689136 RadarOdinZone6 "Mch.XCU.XOI.RadarOdinZone6";
BA_ "VssSig" SG_ 2583689136 RadarOdinZone5 "Mch.XCU.XOI.RadarOdinZone5";
BA_ "VssSig" SG_ 2583689136 RadarOdinZone4 "Mch.XCU.XOI.RadarOdinZone4";
BA_ "VssSig" SG_ 2583689136 RadarOdinZone3 "Mch.XCU.XOI.RadarOdinZone3";
BA_ "VssSig" SG_ 2583689136 RadarOdinZone2 "Mch.XCU.XOI.RadarOdinZone2";
BA_ "VssSig" SG_ 2583689136 RadarOdinZone1 "Mch.XCU.XOI.RadarOdinZone1";
BA_ "VssSig" SG_ 2583689136 SavmOdinZone6 "Mch.XCU.XOI.SavmOdinZone6";
BA_ "VssSig" SG_ 2583689136 SavmOdinZone5 "Mch.XCU.XOI.SavmOdinZone5";
BA_ "VssSig" SG_ 2583689136 SavmOdinZone4 "Mch.XCU.XOI.SavmOdinZone4";
BA_ "VssSig" SG_ 2583689136 SavmOdinZone3 "Mch.XCU.XOI.SavmOdinZone3";
BA_ "VssSig" SG_ 2583689136 SavmOdinZone2 "Mch.XCU.XOI.SavmOdinZone2";
BA_ "VssSig" SG_ 2583689136 SavmOdinZone1 "Mch.XCU.XOI.SavmOdinZone1";
BA_ "VssSig" SG_ 2583690672 RolloverDttWarn "Mch.XCU.ROLL.RolloverDttWarn";
BA_ "VssSig" SG_ 2583690672 RollAngWarn "Mch.XCU.ROLL.RollAngWarn";
BA_ "VssSig" SG_ 2583690672 PchAngWarn "Mch.XCU.ROLL.PchAngWarn";
BA_ "VssSig" SG_ 2566865953 HstTractionLvSel "Mch.MCU.SIG2.HstTractionLvSel";
BA_ "VssSig" SG_ 2566865953 FltHold "Mch.MCU.SIG2.FltHold";
BA_ "VssSig" SG_ 2566865953 Adb "Mch.MCU.SIG2.Adb";
BA_ "VssSig" SG_ 2566865953 Cruise "Mch.MCU.SIG2.Cruise";
BA_ "VssSig" SG_ 2566865953 WhlDrvMd "Mch.MCU.SIG2.WhlDrvMd";
BA_ "VssSig" SG_ 2566865953 DesMchShtDn "Mch.MCU.SIG2.DesMchShtDn";
BA_ "VssSig" SG_ 2566865953 FrcRgnStp "Mch.MCU.SIG2.FrcRgnStp";
BA_ "VssSig" SG_ 2566865953 FrcRgnScs "Mch.MCU.SIG2.FrcRgnScs";
BA_ "VssSig" SG_ 2566865953 WghCnt "Mch.MCU.SIG2.WghCnt";
BA_ "VssSig" SG_ 2566865953 MapCreateProg "Mch.MCU.SIG2.MapCreateProg";
BA_ "VssSig" SG_ 2566865953 AngSsTunReq "Mch.MCU.SIG2.AngSsTunReq";
BA_ "VssSig" SG_ 2566865953 ZeroCalbReq "Mch.MCU.SIG2.ZeroCalbReq";
BA_ "VssSig" SG_ 2566865953 WarmUp "Mch.MCU.SIG2.WarmUp";
BA_ "VssSig" SG_ 2566865953 MapCreatReady "Mch.MCU.SIG2.MapCreatReady";
BA_ "VssSig" SG_ 2566865953 ColdStart "Mch.MCU.SIG2.ColdStart";
BA_ "VssSig" SG_ 2566865953 WghTooHv "Mch.MCU.SIG2.WghTooHv";
BA_ "VssSig" SG_ 2566865953 WghPoorLft "Mch.MCU.SIG2.WghPoorLft";
BA_ "VssSig" SG_ 2566865953 WghStartPosHh "Mch.MCU.SIG2.WghStartPosHh";
BA_ "VssSig" SG_ 2566865953 WghSpdBuc "Mch.MCU.SIG2.WghSpdBuc";
BA_ "VssSig" SG_ 2566865953 WghUnderSpd "Mch.MCU.SIG2.WghUnderSpd";
BA_ "VssSig" SG_ 2566865953 RrDefst "Mch.MCU.SIG2.RrDefst";
BA_ "VssSig" SG_ 2566865953 EmgMd "Mch.MCU.SIG2.EmgMd";
BA_ "VssSig" SG_ 2566865953 OprMd "Mch.MCU.SIG2.OprMd";
BA_ "VssSig" SG_ 2566865953 OprPowMd "Mch.MCU.SIG2.OprPowMd";
BA_ "VssSig" SG_ 2566865953 HstMdWld "Mch.MCU.SIG2.HstMdWld";
BA_ "VssSig" SG_ 2566865953 CCO "Mch.MCU.SIG2.CCO";
BA_ "VssSig" SG_ 2566865953 TrqCvt "Mch.MCU.SIG2.TrqCvt";
BA_ "VssSig" SG_ 2566865953 TrvMdWld "Mch.MCU.SIG2.TrvMdWld";
BA_ "VssSig" SG_ 2566865953 Creep "Mch.MCU.SIG2.Creep";
BA_ "VssSig" SG_ 2566865953 ThrtLck "Mch.MCU.SIG2.ThrtLck";
BA_ "VssSig" SG_ 2566865953 Dhl "Mch.MCU.SIG2.Dhl";
BA_ "VssSig" SG_ 2566865953 LisSw "Mch.MCU.SIG2.LisSw";
BA_ "VssSig" SG_ 2566865953 CoolDrtTm "Mch.MCU.SIG2.CoolDrtTm";
BA_ "VssSig" SG_ 2566865953 WifDrtTm "Mch.MCU.SIG2.WifDrtTm";
BA_ "VssSig" SG_ 2566838784 SwId "Mch.ECU.SOFT.SwId";
BA_ "VssSig" SG_ 2566838784 NoOfSwId "Mch.ECU.SOFT.NoOfSwId";
BA_ "VssSig" SG_ 2566838858 FwBleVer "Mch.TGU.SOFT.FwBleVer";
BA_ "VssSig" SG_ 2566838858 FwBleYy "Mch.TGU.SOFT.FwBleYy";
BA_ "VssSig" SG_ 2566838858 FwBleDd "Mch.TGU.SOFT.FwBleDd";
BA_ "VssSig" SG_ 2566838858 FwBleMm "Mch.TGU.SOFT.FwBleMm";
BA_ "VssSig" SG_ 2566838858 FwEsuVer "Mch.TGU.SOFT.FwEsuVer";
BA_ "VssSig" SG_ 2566838858 FwEsuYy "Mch.TGU.SOFT.FwEsuYy";
BA_ "VssSig" SG_ 2566838858 FwEsuDd "Mch.TGU.SOFT.FwEsuDd";
BA_ "VssSig" SG_ 2566838858 FwEsuMm "Mch.TGU.SOFT.FwEsuMm";
BA_ "VssSig" SG_ 2566838858 FwTguVer "Mch.TGU.SOFT.FwTguVer";
BA_ "VssSig" SG_ 2566838858 FwTguYy "Mch.TGU.SOFT.FwTguYy";
BA_ "VssSig" SG_ 2566838858 FwTguDd "Mch.TGU.SOFT.FwTguDd";
BA_ "VssSig" SG_ 2566838858 FwTguMm "Mch.TGU.SOFT.FwTguMm";
BA_ "VssSig" SG_ 2566838858 SwTguVer "Mch.TGU.SOFT.SwTguVer";
BA_ "VssSig" SG_ 2566838858 SwTguYy "Mch.TGU.SOFT.SwTguYy";
BA_ "VssSig" SG_ 2566838858 SwTguDd "Mch.TGU.SOFT.SwTguDd";
BA_ "VssSig" SG_ 2566838858 SwTguMm "Mch.TGU.SOFT.SwTguMm";
BA_ "VssSig" SG_ 2566838858 VerCnt "Mch.TGU.SOFT.VerCnt";
BA_ "VssSig" SG_ 2583642401 TguId "Mch.MCU.MPI.TguId";
BA_ "VssSig" SG_ 2583642401 Oem "Mch.MCU.MPI.Oem";
BA_ "VssSig" SG_ 2583642401 Mch "Mch.MCU.MPI.Mch";
VAL_ 2583660065 EstopTpr 0 "OFF" 1 "ON" 2 "ERROR" 3 "NOT_AVAILABLE" ;
VAL_ 2566908592 TiltRttArg 0 "OFF" 1 "ON" 2 "ERROR" 3 "NOT_AVAILABLE" ;
VAL_ 2566908592 GnssSt 0 "NORMAL" 1 "NOT_FIXED" 2 "RELEASE_ON_GA" 3 "ERROR_EXCEEDED" 4 "GNSS_COMMUNICATION_ERROR" ;
VAL_ 2566908592 VhcStFineSwgTprDsb 0 "OFF" 1 "ON" 2 "ERROR" 3 "NOT_AVAILABLE" ;
VAL_ 2566908592 AssitSwgRh 0 "OFF" 1 "ON" 2 "ERROR" 3 "NOT_AVAILABLE" ;
VAL_ 2566908592 AssitSwgLh 0 "OFF" 1 "ON" 2 "ERROR" 3 "NOT_AVAILABLE" ;
VAL_ 2566908592 AssitBck 0 "OFF" 1 "ON" 2 "ERROR" 3 "NOT_AVAILABLE" ;
VAL_ 2566908592 AssitGrd 0 "OFF" 1 "ON" 2 "ERROR" 3 "NOT_AVAILABLE" ;
VAL_ 2566908592 SafeWrkSideFar 0 "OFF" 1 "ON" 2 "ERROR" 3 "NOT_AVAILABLE" ;
VAL_ 2566908592 SafeWrkSideMid 0 "OFF" 1 "ON" 2 "ERROR" 3 "NOT_AVAILABLE" ;
VAL_ 2566908592 SafeWrkSideNear 0 "OFF" 1 "ON" 2 "ERROR" 3 "NOT_AVAILABLE" ;
VAL_ 2566908592 SafeWrkFrFar 0 "OFF" 1 "ON" 2 "ERROR" 3 "NOT_AVAILABLE" ;
VAL_ 2566908592 SafeWrkFrMid 0 "OFF" 1 "ON" 2 "ERROR" 3 "NOT_AVAILABLE" ;
VAL_ 2566908592 SafeWrkFrNear 0 "OFF" 1 "ON" 2 "ERROR" 3 "NOT_AVAILABLE" ;
VAL_ 2566908592 FrMvGuidArmOut 0 "OFF" 1 "ON" 2 "ERROR" 3 "NOT_AVAILABLE" ;
VAL_ 2566908592 FrMvGuidArmIn 0 "OFF" 1 "ON" 2 "ERROR" 3 "NOT_AVAILABLE" ;
VAL_ 2566908592 FrMvGuidBoomDn 0 "OFF" 1 "ON" 2 "ERROR" 3 "NOT_AVAILABLE" ;
VAL_ 2566908592 FrMvGuidBoomUp 0 "GREEN" 1 "YELLOW" 2 "RED" ;
VAL_ 2566908592 EfenceTrkWrn 0 "OFF" 1 "ON" 2 "ACTIVE" 3 "RESERVED" ;
VAL_ 2566908592 EfenceDzWrn 0 "OFF" 1 "ON" 2 "ACTIVE" 3 "RESERVED" ;
VAL_ 2566908592 EfenceCabWrn 0 "OFF" 1 "ON" 2 "ACTIVE" 3 "RESERVED" ;
VAL_ 2566908592 EfenceFSwgRhWrn 0 "OFF" 1 "ON" 2 "ACTIVE" 3 "RESERVED" ;
VAL_ 2566908592 EfenceFSwgLhWrn 0 "OFF" 1 "ON" 2 "ACTIVE" 3 "RESERVED" ;
VAL_ 2566908592 EfenceCeilWrn 0 "OFF" 1 "ON" 2 "ACTIVE" 3 "RESERVED" ;
VAL_ 2566908592 EfenceFloorWrn 0 "OFF" 1 "ON" 2 "ACTIVE" 3 "RESERVED" ;
VAL_ 2566908592 EfenceWallWrn 0 "OFF" 1 "ON" 2 "ACTIVE" 3 "RESERVED" ;
VAL_ 2583660464 SelMdHeartbeat 0 "INITIALIZED" 1 "DISARMED" 2 "ARM_REQUESTED" 3 "DEACTIVATION" 4 "ACTIVATION" ;
VAL_ 2583660464 ArmingAcptReq 0 "NOT_ACCEPTED" 1 "ACCEPTED" ;
VAL_ 2583660464 McActCmd 0 "NO_ACTIVATION" 1 "ACTIVATION" ;
VAL_ 2583660464 GrdAstOptmCtrlMdSt 0 "DISABLE" 1 "ENABLE" ;
VAL_ 2583660464 McItlReq 0 "NO_LOCKOUT_PRESENT_AUTO_ALLOWED" 1 "TIME_OUT" 2 "MACHINE_SAFETY" ;
VAL_ 2583660464 McReqMd 0 "DISARMED" 1 "NORMAL" 2 "SERVICE" 3 "NOT_DEFINED" ;
VAL_ 2566911153 AmbLmpColorMd 0 "USER_SETTING_COLOR" 1 "POWER_MODE_COLOR" ;
VAL_ 2566911308 SelMdHeartbeat 0 "INITIALIZED" 1 "DISARMED" 2 "ARM_REQUESTED" 3 "DEACTIVATION" 4 "ACTIVATED" ;
VAL_ 2566911308 ArmingAcptReq 0 "NOT_ACCEPTED" 1 "ACCEPTED" ;
VAL_ 2566911308 RmWrkMdSelSig 0 "DIG" 1 "LIFT" 2 "1WAY" 3 "2WAY" ;
VAL_ 2566911308 RmTrvlSpdSelSig 0 "LOW_SPEED" 1 "HIGH_SPEED" 2 "AUTO_SPEED" 3 "NOT_AVAILABLE" ;
VAL_ 2566911308 RmPwrMdSelSig2 0 "POWER+" 1 "POWER" 2 "STANDARD" 3 "ECO" ;
VAL_ 2566911308 RmCtrlActSig 0 "NO_ACTIVATION" 1 "ACTIVATION" ;
VAL_ 2566911308 RmCtrlReq 0 "DISARMED " 1 "NORMAL" 2 "SERVICE " 3 "NOT DEFINED" ;
VAL_ 2566911308 RmEgStopSt 0 "OFF" 1 "ON" 2 "ERROR" 3 "NOT_AVAILABLE" ;
VAL_ 2566911308 RmPwrMdSelSig1 0 "OFF" 1 "ON" 2 "ERROR" 3 "NOT_AVAILABLE" ;
VAL_ 2566911308 RmEmgStopOprSig 0 "OFF" 1 "ON" 2 "ERROR" 3 "NOT_AVAILABLE" ;
VAL_ 2566911308 RmFrcRgnOprSig 0 "OFF" 1 "ON" 2 "ERROR" 3 "NOT_AVAILABLE" ;
VAL_ 2566911308 RmHornOprSig 0 "OFF" 1 "ON" 2 "ERROR" 3 "NOT_AVAILABLE" ;
VAL_ 2566911308 RmPltCutoffRlsSvOprSig 0 "OFF" 1 "ON" 2 "ERROR" 3 "NOT_AVAILABLE" ;
VAL_ 2566911308 RmFineSwgSvOprSig 0 "OFF" 1 "ON" 2 "ERROR" 3 "NOT_AVAILABLE" ;
VAL_ 2566911308 RmCbLmpRly2OprSig 0 "OFF" 1 "ON" 2 "ERROR" 3 "NOT_AVAILABLE" ;
VAL_ 2566911308 RmCbLmpRly1OprSig 0 "OFF" 1 "ON" 2 "ERROR" 3 "NOT_AVAILABLE" ;
VAL_ 2566911308 RmBodyLmpRlyOprSig 0 "OFF" 1 "ON" 2 "ERROR" 3 "NOT_AVAILABLE" ;
VAL_ 2566911308 RmWrkLmpRlyOprSig 0 "OFF" 1 "ON" 2 "ERROR" 3 "NOT_AVAILABLE" ;
VAL_ 2566867632 WarnPopLimitangexcess 0 "NONE" 1 "TILTING_IS_NOT_POSSIBLE" ;
VAL_ 2566867632 WarnPopMgMcSsErr 0 "NONE" 1 "SS_ERROR_BODY_BOOM_ARM_BCK_SWG" 2 "SENSOR_ERROR_TILT" 3 "SENSOR_ERROR_PILOT_CUTOFF" 4 "MACHINE_ERROR" 5 "XCU_COMMUNICATION_ERROR" 6 "TILT_ROTATOR_ERROR" ;
VAL_ 2566867632 McTemporaryRlsPop 0 "OFF" 1 "ON" 2 "ERROR" 3 "NOT_AVAILABLE" ;
VAL_ 2566867632 VhcStStickStr 0 "OFF" 1 "ON" 2 "ERROR" 3 "NOT_AVAILABLE" ;
VAL_ 2566867632 VhcStFineSwg 0 "OFF" 1 "ON" 2 "ERROR" 3 "NOT_AVAILABLE" ;
VAL_ 2566867632 ActTrvlSpdforCrwl 0 "LOW_SPEED" 1 "HIGH_SPEED" 2 "AUTO_SPEED" 3 "NOT_AVAILABLE" ;
VAL_ 2566867632 ActTrvlStforCrwl 0 "NOT_TRAVELING" 1 "TRAVELING" 2 "RESERVED" 3 "NOT_AVAILABLE" ;
VAL_ 2566867632 VhcStParallelLift 0 "OFF" 1 "ON" 2 "ERROR" 3 "NOT_AVAILABLE" ;
VAL_ 2566867632 VhcStFrSspnAuto 0 "OFF" 1 "ON" 2 "ERROR" 3 "NOT_AVAILABLE" ;
VAL_ 2566867632 RmCrakingSt 0 "NONE" 1 "SUCCESS" 2 "FAIL_BY_PARKING_SWITCH" 3 "FAIL_BY_NEUTRAL_SWITCH" 4 "FAIL_BY_PILOT_CUT_OFF_SWITCH" 5 "FAIL_BY_ANOTHER_REASON" ;
VAL_ 2566867632 VhcStElevatingCabin 0 "OFF" 1 "ON_NO_BLINKING" 2 "ON_NORMAL_BLINKING" 3 "ON_SLOW_BLINKING" ;
VAL_ 2566867632 WarnPopStickStr 0 "OFF" 1 "ON" 2 "ERROR" 3 "NOT_AVAILABLE" ;
VAL_ 2566867632 PopCmdThwLvrErr 0 "OFF" 1 "ON" 2 "ERROR" 3 "NOT_AVAILABLE" ;
VAL_ 2566867632 HpApMd 0 "OFF" 1 "HP" 2 "AP" 3 "NOT_AVAILABLE" ;
VAL_ 2566867632 GrLmt 0 "OFF" 1 "ON" 2 "ERROR" 3 "NOT_AVAILABLE" ;
VAL_ 2566867632 BodyAng 0 "OFF" 1 "ON" 2 "ERROR" 3 "NOT_AVAILABLE" ;
VAL_ 2566867632 WghIndSt 0 "OFF" 1 "STATE_1" 2 "STATE_2" 3 "STATE_3" ;
VAL_ 2566867632 RtrdSt 0 "OFF" 1 "STATE_1" 2 "STATE_2" 3 "STATE_3" 4 "STATE_4" 5 "STATE_5" 6 "STATE_6" 7 "STATE_7" ;
VAL_ 2566867632 PilotCutOffSt 0 "UNLOCK" 1 "MANUAL_LOCK" 2 "AUTO_LOCK" 3 "NOT_AVAILABLE" ;
VAL_ 2566867632 BodySt 0 "OFF" 1 "HOLD" 2 "FLOAT" 3 "NOT_DEFINED" ;
VAL_ 2566867632 VhcStGndSaw 0 "OFF" 1 "ON" 2 "ERROR" 3 "NOT_AVAILABLE" ;
VAL_ 2566867632 VhcStIntAxleLck 0 "OFF" 1 "ON" 2 "ERROR" 3 "NOT_AVAILABLE" ;
VAL_ 2566867632 TrlHhFlowMd 0 "STANDARD_BLUE" 1 "XPS_ORANGE" 2 "XHP_XE_RED" ;
VAL_ 2566867632 ExcAutoBrkAntiFire 0 "OFF" 1 "ON" 2 "CONDITION_GREEN" 3 "CONDITION_YELLOW" ;
VAL_ 2566867632 TrlIntLckOvrd 0 "OFF" 1 "ON" 2 "ERROR" 3 "NOT_AVAILABLE" ;
VAL_ 2566867632 TrlCtrlFlow 0 "OFF" 1 "ON" 2 "CONDITION_GREEN" 3 "CONDITION_YELLOW" ;
VAL_ 2566867632 TrlSelfLv 0 "OFF" 1 "ON" 2 "CONDITION_GREEN" 3 "CONDITION_YELLOW" ;
VAL_ 2566867632 TrlHhFlow 0 "OFF" 1 "ON" 2 "ERROR" 3 "NOT_AVAILABLE" ;
VAL_ 2583642698 CellAntType 0 "NONE" 1 "INTERNAL" 2 "EXTERNAL" 3 "NOT_AVAILABLE" ;
VAL_ 2583642698 CellType 0 "2G" 1 "3G" 2 "4G" 3 "5G" 7 "NOT_AVAILABLE" ;
VAL_ 2583642698 ActiveNw 0 "NONE" 1 "CELL" 2 "WIFI" 3 "ERROR" ;
VAL_ 2583642698 Provisioned 0 "NONE" 1 "NETWORK_PROVISIONED" 2 "THING_PROVISIONED" ;
VAL_ 2583642698 Connected 0 "NONE" 1 "NETWORK_CONNECTED" 2 "CLOUD_CONNECTED" 3 "NOT_AVAILABLE" ;
VAL_ 2565406538 Ack 0 "FALSE" 1 "TRUE" 2 "ERROR" 3 "NOT_AVAILABLE" ;
VAL_ 2566878753 ActnDrSec 0 "INACTIVE" 1 "ACTIVE" 2 "RESERVED" 3 "NOT_AVAILABLE" ;
VAL_ 2566878753 WifiAntSt 0 "NORMAL" 1 "ERROR1" 2 "ERROR2" 3 "ERROR3" ;
VAL_ 2566878753 CellAntSt 0 "NORMAL" 1 "ERROR1" 2 "ERROR2" 3 "ERROR3" ;
VAL_ 2566878753 GpsAntSt 0 "NORMAL" 1 "ERROR1" 2 "ERROR2" 3 "NOT_AVAILABLE" ;
VAL_ 2566878753 SecCmd 0 "NORMAL" 1 "RPM_LIMIT" 2 "ENGINE_LOCK" 3 "NOT_AVAILABLE" ;
VAL_ 2566868513 VhcStSybEmgStrCheck 0 "OFF" 1 "ON" 2 "ERROR" 3 "NOT_AVAILABLE" ;
VAL_ 2566868513 CmdBodyLiftLmt 0 "OFF" 1 "ON" 2 "ERROR" 3 "NOT_AVAILABLE" ;
VAL_ 2566868513 VhcStSybAutoHold 0 "OFF" 1 "STATE1_WHITE" 2 "STATE2_GREEN" ;
VAL_ 2566868513 VhcStSybAutoDig 0 "OFF" 1 "STATE1_WHITE" 2 "STATE2_GREEN" ;
VAL_ 2566868513 RearRTirePrsLow 0 "OFF" 1 "ON" 2 "ERROR" 3 "NOT_AVAILABLE" ;
VAL_ 2566868513 RearLTirePrsLow 0 "OFF" 1 "ON" 2 "ERROR" 3 "NOT_AVAILABLE" ;
VAL_ 2566868513 FrRTirePrsLow 0 "OFF" 1 "ON" 2 "ERROR" 3 "NOT_AVAILABLE" ;
VAL_ 2566868513 FrLTirePrsLow 0 "OFF" 1 "ON" 2 "ERROR" 3 "NOT_AVAILABLE" ;
VAL_ 2566868513 HhFlowAuxSt 0 "OFF" 1 "STATE1_WHITE" 2 "STATE2_GREEN" ;
VAL_ 2566868513 IndSybWirelessChgSt 0 "OFF" 1 "CHARGING" 2 "CHARGING_COMPLETE" 3 "FOD_STATUS" ;
VAL_ 2566868513 VhcStSybIdleSpdSet 0 "OFF" 1 "ON" 2 "ERROR" 3 "NOT_AVAILABLE" ;
VAL_ 2566868513 GrStMismatchSig 0 "OFF" 1 "ON" 2 "ERROR" 3 "NOT_AVAILABLE" ;
VAL_ 2566868513 VhcStSybBrkChg 0 "OFF" 1 "ON_NO_BLINKING" 2 "ON_NORMAL_BLINKING" 3 "ON_SLOW_BLINKING" ;
VAL_ 2566868513 CmdFineSwg 0 "OFF" 1 "ON" 2 "ERROR" 3 "NOT_AVAILABLE" ;
VAL_ 2566868513 CmdOptLinePrsRf 0 "OFF" 1 "ON" 2 "ERROR" 3 "NOT_AVAILABLE" ;
VAL_ 2566868513 AdtUserWghCalSt 0 "OFF" 1 "ON" 2 "ERROR" 3 "NOT_AVAILABLE" ;
VAL_ 2566868513 VhcStateSybSpdLimitCtrl 0 "OFF" 1 "ON" 2 "ERROR" 3 "NOT_AVAILABLE" ;
VAL_ 2566868513 TmShftMdSybforLd 0 "MANUAL" 1 "AUTO_LIGHT" 2 "AUTO_NORMAL" 3 "AUTO_HEAVY" ;
VAL_ 2566868513 BckShakeStSig 0 "OFF" 1 "STATE1" 2 "STATE2" ;
VAL_ 2566868513 CmdForceRegenFail 0 "OFF" 1 "MANUAL" 2 "SELF_LEVELING" ;
VAL_ 2566868513 DumpBodyOprSig 0 "OFF" 1 "MANUAL" 2 "SELF_LEVELING" ;
VAL_ 2566868513 WghStRefreshSig 0 "OFF" 1 "REFRESH" ;
VAL_ 2566868513 CmdStarterFail 0 "OFF" 1 "STARTER1_FAIL" 2 "STARTER2_FAIL" ;
VAL_ 2566868513 IdleSpdSetCond 0 "OFF" 1 "ON" 2 "ERROR" 3 "NOT_AVAILABLE" ;
VAL_ 2566868513 CmdRrSspn_SelfLv 0 "OFF" 1 "MANUAL" 2 "SELF_LEVELING" ;
VAL_ 2566868513 VhcStSybRrSspnAuto 0 "OFF" 1 "ON" 2 "ERROR" 3 "NOT_AVAILABLE" ;
VAL_ 2566868513 CmdFrSspn 0 "OFF" 1 "MANUAL" 2 "SELF_LEVELING" ;
VAL_ 2365559376 GreenBeaconOprSig 0 "OFF" 1 "ON" 2 "ERROR" 3 "NOT_AVAILABLE" ;
VAL_ 2365559376 IdleSpdSetOprSig 0 "OFF" 1 "ON" 2 "ERROR" 3 "NOT_AVAILABLE" ;
VAL_ 2365559376 TransverseDiffLckOprSig 0 "OFF" 1 "ON" 2 "ERROR" 3 "NOT_AVAILABLE" ;
VAL_ 2365559376 CruiseOprSig 0 "OFF" 1 "ON" 2 "ERROR" 3 "NOT_AVAILABLE" ;
VAL_ 2365559376 AirconDisplayOn 0 "OFF" 1 "ON" 2 "ERROR" 3 "NOT_AVAILABLE" ;
VAL_ 2365559376 FrcRgnStp 0 "OFF" 1 "ON" 2 "ERROR" 3 "NOT_AVAILABLE" ;
VAL_ 2365559376 FrcRgn 0 "OFF" 1 "ON" 2 "ERROR" 3 "NOT_AVAILABLE" ;
VAL_ 2365559376 BodyKickOut 0 "OFF" 1 "ON" 2 "ERROR" 3 "NOT_AVAILABLE" ;
VAL_ 2365559376 InterAxleLck 0 "OFF" 1 "ON" 2 "ERROR" 3 "NOT_AVAILABLE" ;
VAL_ 2365559376 RtdBrkAst 0 "OFF" 1 "ON" 2 "ERROR" 3 "NOT_AVAILABLE" ;
VAL_ 2365559376 QckCplBzOff 0 "OFF" 1 "ON" 2 "ERROR" 3 "NOT_AVAILABLE" ;
VAL_ 2365559585 GreenBeaconLInd 0 "OFF" 1 "ON" 2 "BLINKING" 3 "NOT_AVAILABLE" ;
VAL_ 2365559585 GreenBeaconCtrInd 0 "OFF" 1 "ON" 2 "BLINKING" 3 "NOT_AVAILABLE" ;
VAL_ 2365559585 GreenBeaconRInd 0 "OFF" 1 "ON" 2 "BLINKING" 3 "NOT_AVAILABLE" ;
VAL_ 2365559585 IdleSpdSetLInd 0 "OFF" 1 "ON" 2 "BLINKING" 3 "NOT_AVAILABLE" ;
VAL_ 2365559585 IdleSpdSetCtrInd 0 "OFF" 1 "ON" 2 "BLINKING" 3 "NOT_AVAILABLE" ;
VAL_ 2365559585 IdleSpdSetRInd 0 "OFF" 1 "ON" 2 "BLINKING" 3 "NOT_AVAILABLE" ;
VAL_ 2365559585 TransverseDiffLckLOprSig 0 "OFF" 1 "ON" 2 "BLINKING" 3 "NOT_AVAILABLE" ;
VAL_ 2365559585 TransverseDiffLckCtrOprSig 0 "OFF" 1 "ON" 2 "BLINKING" 3 "NOT_AVAILABLE" ;
VAL_ 2365559585 TransverseDiffLckROprSig 0 "OFF" 1 "ON" 2 "BLINKING" 3 "NOT_AVAILABLE" ;
VAL_ 2365559585 CruiseLInd 0 "OFF" 1 "ON" 2 "BLINKING" 3 "NOT_AVAILABLE" ;
VAL_ 2365559585 CruiseCtrInd 0 "OFF" 1 "ON" 2 "BLINKING" 3 "NOT_AVAILABLE" ;
VAL_ 2365559585 CruiseRInd 0 "OFF" 1 "ON" 2 "BLINKING" 3 "NOT_AVAILABLE" ;
VAL_ 2365559585 RtdBrkAstLInd 0 "OFF" 1 "ON" 2 "BLINKING" 3 "NOT_AVAILABLE" ;
VAL_ 2365559585 RtdBrkAstCtrInd 0 "OFF" 1 "ON" 2 "BLINKING" 3 "NOT_AVAILABLE" ;
VAL_ 2365559585 RtdBrkAstRInd 0 "OFF" 1 "ON" 2 "BLINKING" 3 "NOT_AVAILABLE" ;
VAL_ 2365559585 QckCplBzOffLInd 0 "OFF" 1 "ON" 2 "BLINKING" 3 "NOT_AVAILABLE" ;
VAL_ 2365559585 QckCplBzOffCtrInd 0 "OFF" 1 "ON" 2 "BLINKING" 3 "NOT_AVAILABLE" ;
VAL_ 2365559585 QckCplBzOffRInd 0 "OFF" 1 "ON" 2 "BLINKING" 3 "NOT_AVAILABLE" ;
VAL_ 2365559585 FrcRgnStpLInd 0 "OFF" 1 "ON" 2 "BLINKING" 3 "NOT_AVAILABLE" ;
VAL_ 2365559585 FrcRgnStpCtrInd 0 "OFF" 1 "ON" 2 "BLINKING" 3 "NOT_AVAILABLE" ;
VAL_ 2365559585 FrcRgnStpRInd 0 "OFF" 1 "ON" 2 "BLINKING" 3 "NOT_AVAILABLE" ;
VAL_ 2365559585 FrcRgnLInd 0 "OFF" 1 "ON" 2 "BLINKING" 3 "NOT_AVAILABLE" ;
VAL_ 2365559585 FrcRgnCtrInd 0 "OFF" 1 "ON" 2 "BLINKING" 3 "NOT_AVAILABLE" ;
VAL_ 2365559585 FrcRgnRInd 0 "OFF" 1 "ON" 2 "BLINKING" 3 "NOT_AVAILABLE" ;
VAL_ 2365559585 BodyKickOutLInd 0 "OFF" 1 "ON" 2 "BLINKING" 3 "NOT_AVAILABLE" ;
VAL_ 2365559585 BodyKickOutCtrInd 0 "OFF" 1 "ON" 2 "BLINKING" 3 "NOT_AVAILABLE" ;
VAL_ 2365559585 BodyKickOutRInd 0 "OFF" 1 "ON" 2 "BLINKING" 3 "NOT_AVAILABLE" ;
VAL_ 2365559585 InterAxleLckLInd 0 "OFF" 1 "ON" 2 "BLINKING" 3 "NOT_AVAILABLE" ;
VAL_ 2365559585 InterAxleLckCtrInd 0 "OFF" 1 "ON" 2 "BLINKING" 3 "NOT_AVAILABLE" ;
VAL_ 2365559585 InterAxleLckRInd 0 "OFF" 1 "ON" 2 "BLINKING" 3 "NOT_AVAILABLE" ;
VAL_ 2566910903 EmgEgStpSwSt 0 "OFF" 1 "ON" 2 "ERROR" 3 "NOT_AVAILABLE" ;
VAL_ 2566910903 RmPwrMdSelSig1 0 "OFF" 1 "ON" 2 "ERROR" 3 "NOT_AVAILABLE" ;
VAL_ 2566910903 RmEmgStpOprtSig1 0 "OFF" 1 "ON" 2 "ERROR" 3 "NOT_AVAILABLE" ;
VAL_ 2566910903 RmCtrlMethodSelSt 0 "REMOTE_CONTROL_STATION" 1 "REMOTE_CONTROL_APP" 2 "REMOTE_CONTROL_CONSOLE" 3 "ERROR" ;
VAL_ 2566910903 RmCtrlSelSt 0 "MANUAL_MODE" 1 "REMOTE_MODE" 2 "NOT_DEFINED" ;
VAL_ 2566891510 Mc3DOprtSt 0 "MANUAL" 1 "AUTO" 2 "AUTO_SUSPEND" ;
VAL_ 2566891510 Mc3DSysReadySt 0 "NOT_READY" 1 "READY" 2 "MC_3D_CALIBRATION" ;
VAL_ 2583645770 OtaSt 0 "DOWNLOAD" 1 "DOWNLOAD_COMPLETE" 2 "DOWNLOAD_FAILURE" 3 "INSTALL" 4 "CONTROLLER_REBOOTING" 5 "MACHINE_REBOOTING" 6 "INSTALL_COMPLETE" 7 "INSTALL_FAILURE_RETRIAL" 8 "OTA_FAILURE" ;
VAL_ 2566859041 FnrDirForLv1RrMon 0 "F" 1 "N" 2 "R" ;
VAL_ 2566913576 MaterialLoadSt 0 "IN_PROGRESS" 1 "COMPLETE" ;
VAL_ 2365573153 KickDownAct 0 "OFF" 1 "ON" 2 "ERROR" 3 "NOT_AVAILABLE" ;
VAL_ 2365573153 SecondFnrEnable 0 "OFF" 1 "ON" 2 "ERROR" 3 "NOT_AVAILABLE" ;
VAL_ 2365573153 SecondFnr 0 "N" 1 "F" 2 "R" 3 "TCU_REQUIRES_N_POSITION" ;
VAL_ 2365573153 ReqEgMd 0 "ECO" 1 "NORMAL" 2 "POWER" ;
VAL_ 2365573153 CrpCtrlSpdRange 0 "RANGE1" 1 "RANGE2" 2 "RANGE3" ;
VAL_ 2365573153 CrpCtrlAct 0 "OFF" 1 "ON" 2 "ERROR" 3 "NOT_AVAILABLE" ;
VAL_ 2365573153 TractionLvSel 0 "A" 1 "B" 2 "C" ;
VAL_ 2365573153 TractionCtrlMd 0 "MAX" 1 "CONTROL_MODE" 2 "SLIP_MODE" ;
VAL_ 2365573153 ThrtLck 0 "OFF" 1 "ON" 2 "ERROR" 3 "NOT_AVAILABLE" ;
VAL_ 2365573153 DmsActCmd 0 "OFF" 1 "ON" 2 "ERROR" 3 "NOT_AVAILABLE" ;
VAL_ 2365573153 WarmUp 0 "OFF" 1 "ON" 2 "ERROR" 3 "NOT_AVAILABLE" ;
VAL_ 2365573153 AutoIdle 0 "OFF" 1 "ON" 2 "ERROR" 3 "NOT_AVAILABLE" ;
VAL_ 2365573409 MaxSpdLmt 0 "UNLIMIT" 1 "LIMIT" ;
VAL_ 2365573409 JoyTypeSel 0 "ELECTRIC_TYPE" 1 "LOCKER_TYPE" ;
VAL_ 2566900739 StPrkBrk 0 "OFF" 1 "ON" 2 "ERROR" 3 "NOT_AVAILABLE" ;
VAL_ 2566900739 StTmpDpdDrvPdlLmt 0 "OFF" 1 "ON" 2 "ERROR" 3 "NOT_AVAILABLE" ;
VAL_ 2566900739 BackUpRly 0 "OFF" 1 "ON" 2 "ERROR" 3 "NOT_AVAILABLE" ;
VAL_ 2566900739 ThrtLckAct 0 "OFF" 1 "ON" 2 "ERROR" 3 "NOT_AVAILABLE" ;
VAL_ 2566900739 ReqEgMd 0 "ECO" 1 "NORMAL" 2 "POWER" ;
VAL_ 2566900739 TractionLvSel 0 "A" 1 "B" 2 "C" ;
VAL_ 2566900739 TractionCtrlMd 0 "MAX" 1 "CONTROL_MODE" 2 "SLIP_MODE" ;
VAL_ 2566888963 AutoShiftIcbConfig 0 "NO_ACTIVATION" 1 "ACTIVATION" ;
VAL_ 2566882081 CoolLvWarneTMSCab 0 "OFF" 1 "ON_NO_BLINKING" 2 "ON_NORMAL_BLINKING" 3 "ON_SLOW_BLINKING" ;
VAL_ 2566882081 CoolLvWarneTMS22 0 "OFF" 1 "ON_NO_BLINKING" 2 "ON_NORMAL_BLINKING" 3 "ON_SLOW_BLINKING" ;
VAL_ 2566882081 CoolLvWarneTMS21 0 "OFF" 1 "ON_NO_BLINKING" 2 "ON_NORMAL_BLINKING" 3 "ON_SLOW_BLINKING" ;
VAL_ 2566882081 CoolLvWarneTMS13 0 "OFF" 1 "ON_NO_BLINKING" 2 "ON_NORMAL_BLINKING" 3 "ON_SLOW_BLINKING" ;
VAL_ 2566882081 CoolLvWarneTMS12 0 "OFF" 1 "ON_NO_BLINKING" 2 "ON_NORMAL_BLINKING" 3 "ON_SLOW_BLINKING" ;
VAL_ 2566882081 CoolLvWarneTMS11 0 "OFF" 1 "ON_NO_BLINKING" 2 "ON_NORMAL_BLINKING" 3 "ON_SLOW_BLINKING" ;
VAL_ 2566882081 Ldc2AbnCur 0 "OFF" 1 "ON_NO_BLINKING" 2 "ON_NORMAL_BLINKING" 3 "ON_SLOW_BLINKING" ;
VAL_ 2566882081 Ldc1AbnCur 0 "OFF" 1 "ON_NO_BLINKING" 2 "ON_NORMAL_BLINKING" 3 "ON_SLOW_BLINKING" ;
VAL_ 2566882081 Ldc2AbnVlt 0 "OFF" 1 "ON_NO_BLINKING" 2 "ON_NORMAL_BLINKING" 3 "ON_SLOW_BLINKING" ;
VAL_ 2566882081 Ldc1AbnVlt 0 "OFF" 1 "ON_NO_BLINKING" 2 "ON_NORMAL_BLINKING" 3 "ON_SLOW_BLINKING" ;
VAL_ 2566882081 Imd 0 "OFF" 1 "ON_NO_BLINKING" 2 "ON_NORMAL_BLINKING" 3 "ON_SLOW_BLINKING" ;
VAL_ 2566882081 BatSuperCoolWarn 0 "OFF" 1 "ON_NO_BLINKING" 2 "ON_NORMAL_BLINKING" 3 "ON_SLOW_BLINKING" ;
VAL_ 2566882081 ObcOvrHt 0 "OFF" 1 "ON_NO_BLINKING" 2 "ON_NORMAL_BLINKING" 3 "ON_SLOW_BLINKING" ;
VAL_ 2566882081 TrvlIvtOvrHt 0 "OFF" 1 "ON_NO_BLINKING" 2 "ON_NORMAL_BLINKING" 3 "ON_SLOW_BLINKING" ;
VAL_ 2566882081 SwgIvtOvrHt 0 "OFF" 1 "ON_NO_BLINKING" 2 "ON_NORMAL_BLINKING" 3 "ON_SLOW_BLINKING" ;
VAL_ 2566882081 PmpIvtOvrHt 0 "OFF" 1 "ON_NO_BLINKING" 2 "ON_NORMAL_BLINKING" 3 "ON_SLOW_BLINKING" ;
VAL_ 2566882081 TrvlMotOvrHt 0 "OFF" 1 "ON_NO_BLINKING" 2 "ON_NORMAL_BLINKING" 3 "ON_SLOW_BLINKING" ;
VAL_ 2566882081 SwgMotOvrHt 0 "OFF" 1 "ON_NO_BLINKING" 2 "ON_NORMAL_BLINKING" 3 "ON_SLOW_BLINKING" ;
VAL_ 2566882081 PmpMotOvrHt 0 "OFF" 1 "ON_NO_BLINKING" 2 "ON_NORMAL_BLINKING" 3 "ON_SLOW_BLINKING" ;
VAL_ 2566882337 PmpDrvOvrHt 0 "OFF" 1 "ON_NO_BLINKING" 2 "ON_NORMAL_BLINKING" 3 "ON_SLOW_BLINKING" ;
VAL_ 2566882337 AirClnPrsType 0 "OFF" 1 "ON_TEXT1" 2 "BLINKING_TEXT1" 3 "SLOW_BLINKING_TEXT1" 4 "NOT_DEFINED1" 5 "ON_TEXT3" 6 "BLINKING_TEXT3" 7 "SLOW_BLINKING_TEXT3" 8 "NOT_DEFINED2" 9 "ON_TEXT2" 10 "BLINKING_TEXT2" 11 "SLOW_BLINKING_TEXT2" 12 "NOT_DEFINED3" 13 "ON_TEXT4" 14 "BLINKING_TEXT4" 15 "SLOW_BLINKING_TEXT4" ;
VAL_ 2566882337 PwrStairway 0 "OFF" 1 "ON_NO_BLINKING" 2 "ON_NORMAL_BLINKING" 3 "ON_SLOW_BLINKING" ;
VAL_ 2566882593 CarryAstSt 0 "OFF" 1 "READY" 2 "ON" ;
VAL_ 2566882593 DacMdTransitionInfo 0 "OFF" 1 "ON" 2 "ERROR" 3 "NOT_AVAILABLE" ;
VAL_ 2566882593 TurnSigR 0 "OFF" 1 "ON" 2 "ERROR" 3 "NOT_AVAILABLE" ;
VAL_ 2566882593 TurnSigL 0 "OFF" 1 "ON" 2 "ERROR" 3 "NOT_AVAILABLE" ;
VAL_ 2566882593 ApprovalReqforRedPrsRmv 0 "OFF" 1 "ON_TEXT1" 2 "BLINKING_TEXT1" 3 "SLOW_BLINKING_TEXT1" 4 "NOT_DEFINED1" 5 "ON_TEXT3" 6 "BLINKING_TEXT3" 7 "SLOW_BLINKING_TEXT3" 8 "NOT_DEFINED2" 9 "ON_TEXT2" 10 "BLINKING_TEXT2" 11 "SLOW_BLINKING_TEXT2" 12 "NOT_DEFINED3" 13 "ON_TEXT4" 14 "BLINKING_TEXT4" 15 "SLOW_BLINKING_TEXT4" ;
VAL_ 2583683361 VhcStSybAutoSleep 0 "OFF" 1 "ON" 2 "ERROR" 3 "NOT_AVAILABLE" ;
VAL_ 2583683361 CmdChgOprLmt 0 "OFF" 1 "ON" 2 "ERROR" 3 "NOT_AVAILABLE" ;
VAL_ 2583683361 VhcStSybChgType 0 "OFF" 1 "SLOW_CHARGING" 2 "FAST_CHARGING" ;
VAL_ 2583683361 VhcStSybObc2ChgSt 0 "OFF" 1 "READY_FOR_CHARGING" 2 "CHARGING" 3 "CANNOT_CHARGE" ;
VAL_ 2583683361 VhcStSybObc1ChgSt 0 "OFF" 1 "READY_FOR_CHARGING" 2 "CHARGING" 3 "CANNOT_CHARGE" ;
VAL_ 2583688759 ObjId 0 "OBJECT_10" 1 "OBJECT_9" 2 "OBJECT_8" 3 "OBJECT_7" 4 "OBJECT_6" 5 "OBJECT_5" 6 "OBJECT_4" 7 "OBJECT_3" 8 "OBJECT_2" 9 "OBJECT_1" 10 "OBJECT_0" ;
VAL_ 2583689136 FusionOdinZone6 0 "NO_OD_IN_ZONE_1" 1 "LEVEL_A" 2 "LEVEL_B" 3 "LEVEL_C" 4 "LEVEL_D" ;
VAL_ 2583689136 FusionOdinZone5 0 "NO_OD_IN_ZONE_1" 1 "LEVEL_A" 2 "LEVEL_B" 3 "LEVEL_C" 4 "LEVEL_D" ;
VAL_ 2583689136 FusionOdinZone4 0 "NO_OD_IN_ZONE_1" 1 "LEVEL_A" 2 "LEVEL_B" 3 "LEVEL_C" 4 "LEVEL_D" ;
VAL_ 2583689136 FusionOdinZone3 0 "NO_OD_IN_ZONE_1" 1 "LEVEL_A" 2 "LEVEL_B" 3 "LEVEL_C" 4 "LEVEL_D" ;
VAL_ 2583689136 FusionOdinZone2 0 "NO_OD_IN_ZONE_1" 1 "LEVEL_A" 2 "LEVEL_B" 3 "LEVEL_C" 4 "LEVEL_D" ;
VAL_ 2583689136 FusionOdinZone1 0 "NO_OD_IN_ZONE_1" 1 "LEVEL_A" 2 "LEVEL_B" 3 "LEVEL_C" 4 "LEVEL_D" ;
VAL_ 2583689136 RadarOdinZone6 0 "NO_OD_IN_ZONE_1" 1 "LEVEL_A" 2 "LEVEL_B" 3 "LEVEL_C" 4 "LEVEL_D" ;
VAL_ 2583689136 RadarOdinZone5 0 "NO_OD_IN_ZONE_1" 1 "LEVEL_A" 2 "LEVEL_B" 3 "LEVEL_C" 4 "LEVEL_D" ;
VAL_ 2583689136 RadarOdinZone4 0 "NO_OD_IN_ZONE_1" 1 "LEVEL_A" 2 "LEVEL_B" 3 "LEVEL_C" 4 "LEVEL_D" ;
VAL_ 2583689136 RadarOdinZone3 0 "NO_OD_IN_ZONE_1" 1 "LEVEL_A" 2 "LEVEL_B" 3 "LEVEL_C" 4 "LEVEL_D" ;
VAL_ 2583689136 RadarOdinZone2 0 "NO_OD_IN_ZONE_1" 1 "LEVEL_A" 2 "LEVEL_B" 3 "LEVEL_C" 4 "LEVEL_D" ;
VAL_ 2583689136 RadarOdinZone1 0 "NO_OD_IN_ZONE_1" 1 "LEVEL_A" 2 "LEVEL_B" 3 "LEVEL_C" 4 "LEVEL_D" ;
VAL_ 2583689136 SavmOdinZone6 0 "NO_OD_IN_ZONE_1" 1 "LEVEL_A" 2 "LEVEL_B" 3 "LEVEL_C" 4 "LEVEL_D" ;
VAL_ 2583689136 SavmOdinZone5 0 "NO_OD_IN_ZONE_1" 1 "LEVEL_A" 2 "LEVEL_B" 3 "LEVEL_C" 4 "LEVEL_D" ;
VAL_ 2583689136 SavmOdinZone4 0 "NO_OD_IN_ZONE_1" 1 "LEVEL_A" 2 "LEVEL_B" 3 "LEVEL_C" 4 "LEVEL_D" ;
VAL_ 2583689136 SavmOdinZone3 0 "NO_OD_IN_ZONE_1" 1 "LEVEL_A" 2 "LEVEL_B" 3 "LEVEL_C" 4 "LEVEL_D" ;
VAL_ 2583689136 SavmOdinZone2 0 "NO_OD_IN_ZONE_1" 1 "LEVEL_A" 2 "LEVEL_B" 3 "LEVEL_C" 4 "LEVEL_D" ;
VAL_ 2583689136 SavmOdinZone1 0 "NO_OD_IN_ZONE_1" 1 "LEVEL_A" 2 "LEVEL_B" 3 "LEVEL_C" 4 "LEVEL_D" ;
VAL_ 2583690672 RolloverDttWarn 0 "OFF" 1 "OVERTURN_WARNING_1" 2 "OVERTURN_WARNING_2" ;
VAL_ 2583690672 RollAngWarn 0 "OFF" 1 "OVERTURN_WARNING_1" 2 "OVERTURN_WARNING_2" ;
VAL_ 2583690672 PchAngWarn 0 "OFF" 1 "OVERTURN_WARNING_1" 2 "OVERTURN_WARNING_2" ;
